VERSION ""

NS_ :

BS_:

BU_: WCM VPM VLM VKM UVM TIM TEST_TOOL_2 TEST_TOOL_1 TCP TCM TCCM3 TCCM STC SRR_SRR SRR_SLR SRR_RR SRR_RF SRR_LR_CR SRR_LF SIB SDM SCL SBZA_R SBZA_L SBM SADS RadioLow RSC RDCM PTM PDR PA NVM MTCM_R MTCM_L MSM_RR MSM_P MSM_LR MSM_D MSB2 MSB1 MRCM_R MRCM_L MFC LRR_HC LRR LIB1 IPC ICS_Info ICCM HVAC_FP_R HVAC_FP_F HUD_CAN HDLM FCM_LC FCM EPS EOCM_HCP2 EOCM_HCP1 EOCM ELM ECP_X1 ECP_MC ECP_E ECM EBCM DMS DEFC DCM CSM CMMb CMMa CGM BSM_MH BSM BCM ARS ARB APA AOS AMP ALC AHS AHL_AFL AGC

BO_ 1470 CGM_CAN5_PDU98: 8 CGM
 SG_ PTOStndbySpdCstCurrSetVal : 48|3@0+ (1,0) [0|7] "" CSM,RadioLow
 SG_ PTOEngRunTmrCstAvlFlg1 : 56|1@0+ (1,0) [0|1] "" CSM,RadioLow
 SG_ PTOEngSpdTypCstCurrSetVal : 58|2@0+ (1,0) [0|2] "" CSM,RadioLow
 SG_ PTOTpStpSpdCstCurrSetVal : 61|3@0+ (1,0) [0|7] "" CSM,RadioLow

BO_ 325 CGM_NM_PDU_On_CAN_5_Cluster: 8 CGM
 SG_ ISignal_CGM_CAN_5_Cluster : 23|48@0+ (1,0) [0|281474976710655] "" AGC,AMP,CSM,HUD_CAN,HVAC_FP_F,HVAC_FP_R,ICS_Info,IPC,PDR,MFC,RSC,RadioLow,TCP,VKM,WCM

BO_ 1263 CSM_CAN5_PDU03: 6 CSM
 SG_ TrlrPlcrdPres : 7|8@0+ (4,0) [0|1020] "kPaG" CGM
 SG_ TrlrProfDrvrReqdSeltn : 10|5@0+ (1,0) [0|21] "" CGM
 SG_ TrlrProfDeltn : 15|5@0+ (1,0) [0|20] "" CGM
 SG_ NumofAxls : 18|2@0+ (1,0) [0|3] "" CGM
 SG_ TrlrTireCnt : 21|3@0+ (1,0) [0|7] "count" CGM

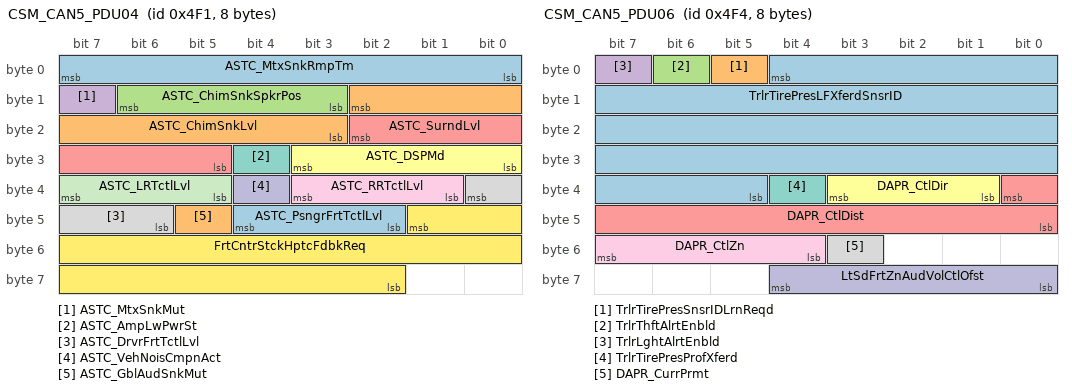
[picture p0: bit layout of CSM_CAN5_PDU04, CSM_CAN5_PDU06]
BO_ 1265 CSM_CAN5_PDU04: 8 CSM
 SG_ ASTC_MtxSnkRmpTm : 7|8@0+ (5,0) [0|1275] "ms" AMP
 SG_ ASTC_ChimSnkLvl : 10|8@0+ (0.5,-127.5) [-127.5|0] "dB" AMP
 SG_ ASTC_ChimSnkSpkrPos : 14|4@0+ (1,0) [0|15] "" AMP
 SG_ ASTC_MtxSnkMut : 15|1@0+ (1,0) [0|1] "" AMP
 SG_ ASTC_SurndLvl : 18|6@0- (1,0) [-32|31] "" AMP
 SG_ ASTC_DSPMd : 27|4@0+ (1,0) [0|15] "" AMP
 SG_ ASTC_AmpLwPwrSt : 28|1@0+ (1,0) [0|1] "" AMP
 SG_ ASTC_DrvrFrtTctlLvl : 32|3@0+ (1,0) [0|7] "Counts" AMP
 SG_ ASTC_RRTctlLvl : 35|3@0+ (1,0) [0|7] "Counts" AMP
 SG_ ASTC_VehNoisCmpnAct : 36|1@0+ (1,0) [0|1] "" AMP
 SG_ ASTC_LRTctlLvl : 39|3@0+ (1,0) [0|7] "Counts" AMP
 SG_ FrtCntrStckHptcFdbkReq : 41|16@0+ (1,0) [0|15] "" ICS_Info
 SG_ ASTC_PsngrFrtTctlLvl : 44|3@0+ (1,0) [0|7] "Counts" AMP
 SG_ ASTC_GblAudSnkMut : 45|1@0+ (1,0) [0|1] "" AMP

BO_ 1266 CSM_CAN5_PDU05: 8 CSM
 SG_ ZALC_LRMtxSnkRmpTm : 4|8@0+ (5,0) [0|1275] "msec" AMP
 SG_ ZALC_LRMtxSnkMut : 5|1@0+ (1,0) [0|1] "" AMP
 SG_ ZALC_PsngrFrtMtxSnkMut : 6|1@0+ (1,0) [0|1] "" AMP
 SG_ ZALC_MltZnMixPrmtAudRR : 7|1@0+ (1,0) [0|1] "" AMP
 SG_ ZALC_PsngrFrtMtxSnkLvl : 12|8@0+ (0.5,-127.5) [-127.5|0] "dB" AMP
 SG_ ZALC_RRMtxSnkLvl : 16|8@0+ (0.5,-127.5) [-127.5|0] "dB" AMP
 SG_ ZALC_RRMtxSnkMut : 17|1@0+ (1,0) [0|1] "" AMP
 SG_ ZALC_MltZnAudFtrStat : 20|3@0+ (1,0) [0|3] "" AMP
 SG_ ZALC_RRMtxSnkRmpTm : 24|8@0+ (5,0) [0|1275] "msec" AMP
 SG_ ZALC_PsngrFrtMtxSnkRmpTm : 32|8@0+ (5,0) [0|1275] "msec" AMP
 SG_ ZALC_VcSrcActvOnRRMtx : 40|1@0+ (1,0) [0|1] "" AMP
 SG_ ZALC_LRMtxSnkLvl : 53|8@0+ (0.5,-127.5) [-127.5|0] "dB" AMP
 SG_ ZALC_MltZnMixPrmtAudDrvrFrt : 54|1@0+ (1,0) [0|1] "" AMP
 SG_ ZALC_VcSrcActvOnPsngrFrtMtx : 55|1@0+ (1,0) [0|1] "" AMP
 SG_ FrtCntrStckOptDskDrvDckStat : 58|3@0+ (1,0) [0|7] "" ICS_Info,TCP
 SG_ ZALC_MltZnMixPrmtAudLR : 59|1@0+ (1,0) [0|1] "" AMP
 SG_ ZALC_MltZnMixPrmtAudPsngrFrt : 60|1@0+ (1,0) [0|1] "" AMP
 SG_ ZALC_VcSrcActvOnLRMtx : 61|1@0+ (1,0) [0|1] "" AMP

BO_ 1268 CSM_CAN5_PDU06: 8 CSM
 SG_ TrlrTirePresLFXferdSnsrID : 4|32@0+ (1,0) [0|4.29497e+009] "" CGM
 SG_ TrlrTirePresSnsrIDLrnReqd : 5|1@0+ (1,0) [0|1] "" CGM
 SG_ TrlrThftAlrtEnbld : 6|1@0+ (1,0) [0|1] "" CGM
 SG_ TrlrLghtAlrtEnbld : 7|1@0+ (1,0) [0|1] "" CGM
 SG_ DAPR_CtlDist : 32|9@0+ (1,0) [0|511] "" AMP
 SG_ DAPR_CtlDir : 35|3@0+ (1,0) [0|7] "" AMP
 SG_ TrlrTirePresProfXferd : 36|1@0+ (1,0) [0|1] "" CGM
 SG_ DAPR_CurrPrmt : 51|1@0+ (1,0) [0|1] "" AMP
 SG_ DAPR_CtlZn : 55|4@0+ (1,0) [0|15] "" AMP
 SG_ LtSdFrtZnAudVolCtlOfst : 60|5@0- (1,0) [-16|15] "" AMP

BO_ 1269 CSM_CAN5_PDU07: 8 CSM
 SG_ LVMAVC_RmtSpchRcgnID : 0|3@0+ (1,0) [0|3] "" PDR
 SG_ LVMAVC_PrmtAudResp : 2|2@0+ (1,0) [0|1] "" PDR
 SG_ LVMAVC_RmtSpchRcgnActn : 4|2@0+ (1,0) [0|3] "" PDR
 SG_ LVMAVC_ApplID : 7|3@0+ (1,0) [0|4] "" PDR
 SG_ LVMAVC_StreoAudResp : 8|2@0+ (1,0) [0|1] "" PDR
 SG_ LVMAVC_RmtEnbl : 11|3@0+ (1,0) [0|2] "" PDR
 SG_ LVMAVC_SpchRcgnAval : 13|2@0+ (1,0) [0|1] "" PDR
 SG_ TrlrLgth : 22|12@0+ (1,0) [0|4095] "cm" CGM
 SG_ TrlrHght : 26|10@0+ (1,0) [0|1023] "cm" CGM
 SG_ TrlrWdth : 32|9@0+ (1,0) [0|511] "cm" CGM
 SG_ TrlrStatTowHaulModeOvrrd : 49|2@0+ (1,0) [0|3] "" CGM
 SG_ TrlrLtngSeqReq : 51|2@0+ (1,0) [0|2] "" CGM
 SG_ TrlrHtchTyp : 53|2@0+ (1,0) [0|3] "" CGM
 SG_ FrtCntrStckVidInSel : 55|2@0+ (1,0) [0|2] "" ICS_Info,PDR,TCP
 SG_ TrlrAppInvsblTrlrPrvwReqd : 56|1@0+ (1,0) [0|1] "" CGM
 SG_ TrlrAppAux2CamPrvwReqd : 57|1@0+ (1,0) [0|1] "" CGM
 SG_ TrlrAppAux1CamPrvwReqd : 58|1@0+ (1,0) [0|1] "" CGM
 SG_ TrlRvsLghtFldEnbld : 59|1@0+ (1,0) [0|1] "" CGM
 SG_ FrtCntrStckTchCtlrRstCmd : 60|1@0+ (1,0) [0|1] "" ICS_Info,TCP
 SG_ Frt360CamSwAct : 61|1@0+ (1,0) [0|1] "" CGM
 SG_ TrlrTyp : 63|2@0+ (1,0) [0|2] "" CGM

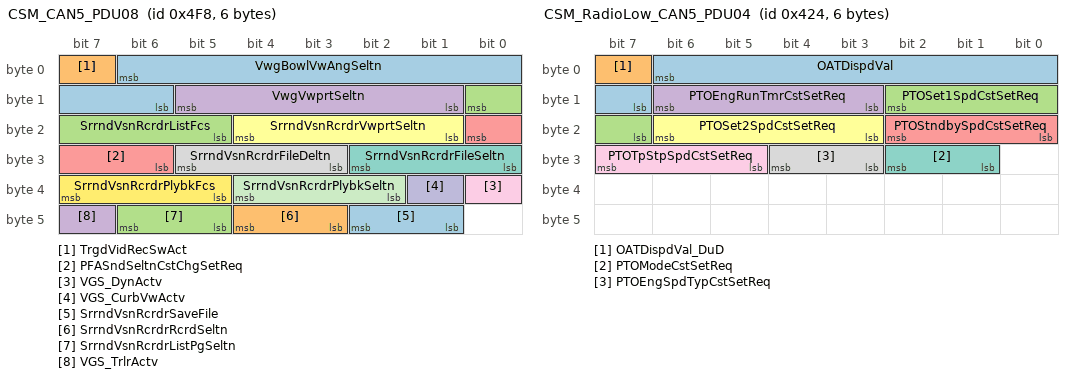
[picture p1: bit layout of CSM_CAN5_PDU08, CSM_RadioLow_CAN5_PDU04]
BO_ 1272 CSM_CAN5_PDU08: 6 CSM
 SG_ VwgBowlVwAngSeltn : 6|9@0+ (1,0) [0|511] "Degree" CGM
 SG_ TrgdVidRecSwAct : 7|1@0+ (1,0) [0|1] "" CGM
 SG_ SrrndVsnRcrdrListFcs : 8|4@0+ (1,0) [0|11] "" CGM
 SG_ VwgVwprtSeltn : 13|5@0+ (1,0) [0|24] "" CGM
 SG_ PFASndSeltnCstChgSetReq : 16|3@0+ (1,0) [0|7] "" CGM
 SG_ SrrndVsnRcrdrVwprtSeltn : 20|4@0+ (1,0) [0|8] "" CGM
 SG_ SrrndVsnRcrdrFileSeltn : 26|3@0+ (1,0) [0|6] "" CGM
 SG_ SrrndVsnRcrdrFileDeltn : 29|3@0+ (1,0) [0|6] "" CGM
 SG_ VGS_DynActv : 32|1@0+ (1,0) [0|1] "" CGM
 SG_ VGS_CurbVwActv : 33|1@0+ (1,0) [0|1] "" CGM
 SG_ SrrndVsnRcrdrPlybkSeltn : 36|3@0+ (1,0) [0|5] "" CGM
 SG_ SrrndVsnRcrdrPlybkFcs : 39|3@0+ (1,0) [0|6] "" CGM
 SG_ SrrndVsnRcrdrSaveFile : 42|2@0+ (1,0) [0|2] "" CGM
 SG_ SrrndVsnRcrdrRcrdSeltn : 44|2@0+ (1,0) [0|2] "" CGM
 SG_ SrrndVsnRcrdrListPgSeltn : 46|2@0+ (1,0) [0|3] "" CGM
 SG_ VGS_TrlrActv : 47|1@0+ (1,0) [0|1] "" CGM

BO_ 1254 CSM_CAN5_PDU09: 8 CSM
 SG_ TrlrTirePresLRXferdSnsrID : 7|32@0+ (1,0) [0|4.29497e+009] "" CGM
 SG_ TrlrTirePresLtMdlXferdSnsrID : 39|32@0+ (1,0) [0|4.29497e+009] "" CGM

BO_ 1257 CSM_CAN5_PDU10: 8 CSM
 SG_ TrlrTirePresRFXferdSnsrID : 7|32@0+ (1,0) [0|4.29497e+009] "" CGM
 SG_ TrlrTirePresRRXferdSnsrID : 39|32@0+ (1,0) [0|4.29497e+009] "" CGM

BO_ 1258 CSM_CAN5_PDU11: 6 CSM
 SG_ TrlrTirePresRtMdlXferdSnsrID : 7|32@0+ (1,0) [0|4.29497e+009] "" CGM
 SG_ HMIInCarVcCommCtl : 34|3@0+ (1,0) [0|6] "" AMP
 SG_ RtSdFrtZnAudVolCtlOfst : 39|5@0- (1,0) [-16|15] "" AMP
 SG_ AutoLnChgCstChgSetReq : 42|3@0+ (1,0) [0|4] "" CGM
 SG_ DrvrSeltdTrlrPrsnt : 43|1@0+ (1,0) [0|1] "" CGM
 SG_ VcRcgnSesnActv : 44|1@0+ (1,0) [0|1] "" AMP
 SG_ HndsFrVcCallActv : 45|1@0+ (1,0) [0|1] "" AMP
 SG_ FrtZnAudVolSyncCtlOn : 46|1@0+ (1,0) [0|1] "" AMP
 SG_ DirAudPrmtRndrngEnbld : 47|1@0+ (1,0) [0|1] "" AMP

BO_ 1415 CSM_CAN5_PDU12: 8 CSM
 SG_ HtchPtLgthExtd : 7|10@0+ (1,1) [1|1024] "cm" CGM
 SG_ TrlrTngeLgth : 13|9@0+ (1,0) [0|511] "cm" CGM
 SG_ VehHtchHght : 20|9@0+ (0.25,0) [0|127.75] "cm" CGM
 SG_ VehHtchLgth : 27|9@0+ (0.25,0) [0|127.75] "cm" CGM
 SG_ TrlrFllHtchPtLgth : 34|11@0+ (1,0) [0|2047] "cm" CGM
 SG_ TrlrToCabLgth : 55|10@0+ (1,0) [0|1023] "cm" CGM

BO_ 1063 CSM_CAN5_PDU13: 6 CSM
 SG_ PASftBtnSeltdStatRw : 5|2@0+ (1,0) [0|3] "" CGM
 SG_ APASftBtnSeltdStatRw : 7|2@0+ (1,0) [0|3] "" CGM

BO_ 1435 CSM_CAN5_PDU14: 6 CSM
 SG_ VehBedHtchToCabLgth : 7|9@0+ (1,0) [0|511] "cm" CGM

BO_ 384 CSM_NM_PDU_On_CAN_5_Cluster: 8 CSM
 SG_ ISignal_CSM_CAN_5_Cluster : 23|48@0+ (1,0) [0|281474976710655] "" AGC,AMP,CGM,HUD_CAN,HVAC_FP_F,HVAC_FP_R,ICS_Info,IPC,PDR,MFC,RSC,RadioLow,TCP,VKM,WCM

BO_ 552 CSM_RadioLow_CAN5_PDU02: 6 CSM
 SG_ WCM_LCMDataMsgStat : 0|1@0+ (1,0) [0|1] "" WCM
 SG_ WCM_LCMFileTrans : 4|3@0+ (1,0) [0|4] "" WCM

BO_ 1356 CSM_RadioLow_CAN5_PDU03: 6 CSM
 SG_ PwrRrClsrCstChgSetReq : 7|3@0+ (1,0) [0|7] "" CGM

BO_ 1060 CSM_RadioLow_CAN5_PDU04: 6 CSM
 SG_ OATDispdVal : 6|8@0+ (1,-40) [-40|215] "" IPC
 SG_ OATDispdVal_DuD : 7|1@0+ (1,0) [0|1] "" IPC
 SG_ PTOSet1SpdCstSetReq : 10|4@0+ (1,0) [0|15] "" CGM
 SG_ PTOEngRunTmrCstSetReq : 14|4@0+ (1,0) [0|15] "" CGM
 SG_ PTOStndbySpdCstSetReq : 18|3@0+ (1,0) [0|7] "" CGM
 SG_ PTOSet2SpdCstSetReq : 22|4@0+ (1,0) [0|15] "" CGM
 SG_ PTOModeCstSetReq : 26|2@0+ (1,0) [0|2] "" CGM
 SG_ PTOEngSpdTypCstSetReq : 28|2@0+ (1,0) [0|2] "" CGM
 SG_ PTOTpStpSpdCstSetReq : 31|3@0+ (1,0) [0|7] "" CGM

BO_ 1419 CSM_VCU_CAN5_PDU01: 6 CSM
 SG_ TrlrBoxWdth : 2|9@0+ (1,0) [0|511] "cm" CGM
 SG_ AutoTrnspHdActvnCstChgSetReq : 5|3@0+ (1,0) [0|2] "" CGM
 SG_ TrlrFaceDpth : 9|9@0+ (1,0) [0|511] "cm" CGM
 SG_ TrlrFrwdSdEdgeHght : 16|9@0+ (1,0) [0|511] "cm" CGM
 SG_ TrlrFrtBtmCrnrHght : 39|9@0+ (1,0) [0|511] "cm" CGM

BO_ 1374 ChmReqInfo_PDU: 8 IPC
 SG_ CRI_ChmPrdcrReq : 7|12@0+ (1,0) [0|4095] "msec" AMP,CSM,RadioLow
 SG_ CRI_CS : 50|11@0+ (1,0) [0|2047] "" AMP,CSM,RadioLow
 SG_ CRI_ARC : 55|2@0+ (1,0) [0|3] "" AMP,CSM,RadioLow

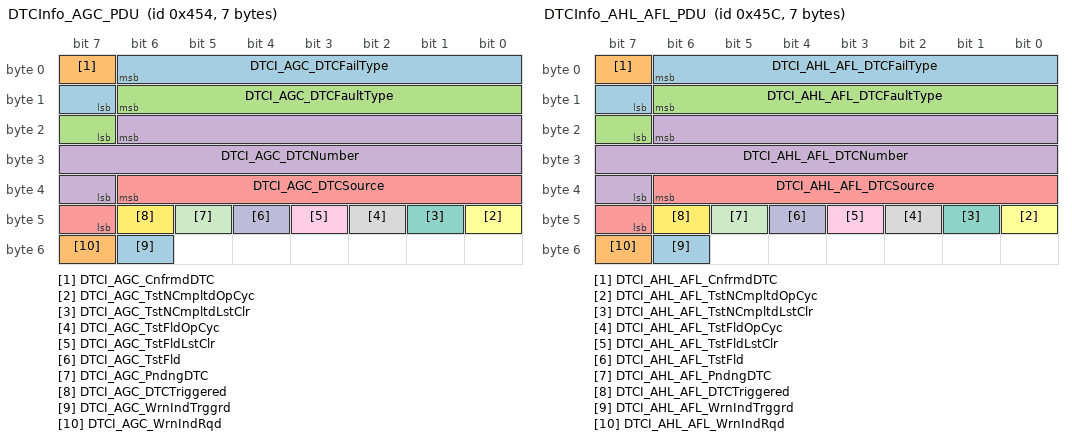
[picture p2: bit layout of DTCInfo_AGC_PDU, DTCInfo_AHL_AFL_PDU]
BO_ 1108 DTCInfo_AGC_PDU: 7 AGC
 SG_ DTCI_AGC_DTCFailType : 6|8@0+ (1,0) [0|255] "" CSM,TCP
 SG_ DTCI_AGC_CnfrmdDTC : 7|1@0+ (1,0) [0|1] "" CSM,TCP
 SG_ DTCI_AGC_DTCFaultType : 14|8@0+ (1,0) [0|3] "" CSM,TCP
 SG_ DTCI_AGC_DTCNumber : 22|16@0+ (1,0) [0|65535] "" CSM,TCP
 SG_ DTCI_AGC_DTCSource : 38|8@0+ (1,0) [0|255] "" CGM,CSM,TCP
 SG_ DTCI_AGC_TstNCmpltdOpCyc : 40|1@0+ (1,0) [0|1] "" CSM,TCP
 SG_ DTCI_AGC_TstNCmpltdLstClr : 41|1@0+ (1,0) [0|1] "" CSM,TCP
 SG_ DTCI_AGC_TstFldOpCyc : 42|1@0+ (1,0) [0|1] "" CSM,TCP
 SG_ DTCI_AGC_TstFldLstClr : 43|1@0+ (1,0) [0|1] "" CSM,TCP
 SG_ DTCI_AGC_TstFld : 44|1@0+ (1,0) [0|1] "" CSM,TCP
 SG_ DTCI_AGC_PndngDTC : 45|1@0+ (1,0) [0|1] "" CSM,TCP
 SG_ DTCI_AGC_DTCTriggered : 46|1@0+ (1,0) [0|1] "" CSM,TCP
 SG_ DTCI_AGC_WrnIndTrggrd : 54|1@0+ (1,0) [0|1] "" CSM,TCP
 SG_ DTCI_AGC_WrnIndRqd : 55|1@0+ (1,0) [0|1] "" CSM,TCP

BO_ 1116 DTCInfo_AHL_AFL_PDU: 7 CGM
 SG_ DTCI_AHL_AFL_DTCFailType : 6|8@0+ (1,0) [0|255] "" CSM,TCP
 SG_ DTCI_AHL_AFL_CnfrmdDTC : 7|1@0+ (1,0) [0|1] "" CSM,TCP
 SG_ DTCI_AHL_AFL_DTCFaultType : 14|8@0+ (1,0) [0|3] "" CSM,TCP
 SG_ DTCI_AHL_AFL_DTCNumber : 22|16@0+ (1,0) [0|65535] "" CSM,TCP
 SG_ DTCI_AHL_AFL_DTCSource : 38|8@0+ (1,0) [0|255] "" CSM,TCP
 SG_ DTCI_AHL_AFL_TstNCmpltdOpCyc : 40|1@0+ (1,0) [0|1] "" CSM,TCP
 SG_ DTCI_AHL_AFL_TstNCmpltdLstClr : 41|1@0+ (1,0) [0|1] "" CSM,TCP
 SG_ DTCI_AHL_AFL_TstFldOpCyc : 42|1@0+ (1,0) [0|1] "" CSM,TCP
 SG_ DTCI_AHL_AFL_TstFldLstClr : 43|1@0+ (1,0) [0|1] "" CSM,TCP
 SG_ DTCI_AHL_AFL_TstFld : 44|1@0+ (1,0) [0|1] "" CSM,TCP
 SG_ DTCI_AHL_AFL_PndngDTC : 45|1@0+ (1,0) [0|1] "" CSM,TCP
 SG_ DTCI_AHL_AFL_DTCTriggered : 46|1@0+ (1,0) [0|1] "" CSM,TCP
 SG_ DTCI_AHL_AFL_WrnIndTrggrd : 54|1@0+ (1,0) [0|1] "" CSM,TCP
 SG_ DTCI_AHL_AFL_WrnIndRqd : 55|1@0+ (1,0) [0|1] "" CSM,TCP

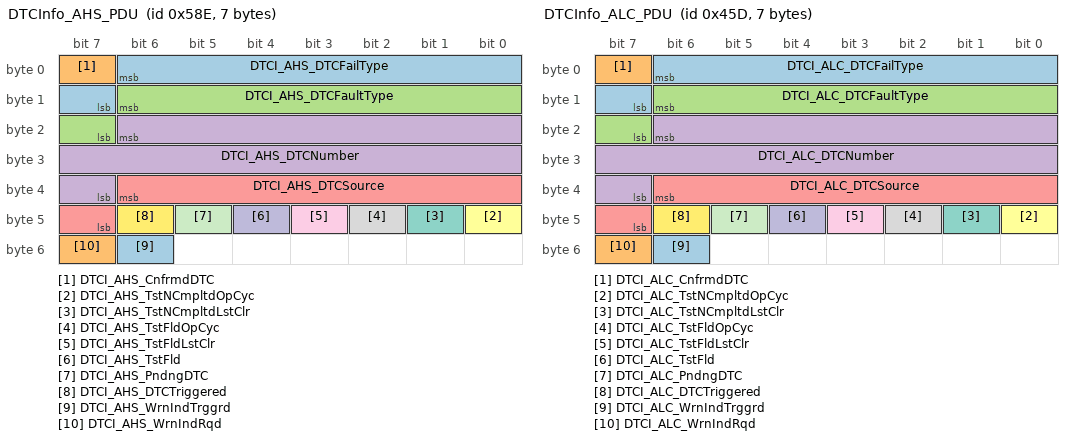
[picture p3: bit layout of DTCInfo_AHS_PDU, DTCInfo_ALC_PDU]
BO_ 1422 DTCInfo_AHS_PDU: 7 CGM
 SG_ DTCI_AHS_DTCFailType : 6|8@0+ (1,0) [0|255] "" TCP
 SG_ DTCI_AHS_CnfrmdDTC : 7|1@0+ (1,0) [0|1] "" TCP
 SG_ DTCI_AHS_DTCFaultType : 14|8@0+ (1,0) [0|3] "" TCP
 SG_ DTCI_AHS_DTCNumber : 22|16@0+ (1,0) [0|65535] "" TCP
 SG_ DTCI_AHS_DTCSource : 38|8@0+ (1,0) [0|255] "" TCP
 SG_ DTCI_AHS_TstNCmpltdOpCyc : 40|1@0+ (1,0) [0|1] "" TCP
 SG_ DTCI_AHS_TstNCmpltdLstClr : 41|1@0+ (1,0) [0|1] "" TCP
 SG_ DTCI_AHS_TstFldOpCyc : 42|1@0+ (1,0) [0|1] "" TCP
 SG_ DTCI_AHS_TstFldLstClr : 43|1@0+ (1,0) [0|1] "" TCP
 SG_ DTCI_AHS_TstFld : 44|1@0+ (1,0) [0|1] "" TCP
 SG_ DTCI_AHS_PndngDTC : 45|1@0+ (1,0) [0|1] "" TCP
 SG_ DTCI_AHS_DTCTriggered : 46|1@0+ (1,0) [0|1] "" TCP
 SG_ DTCI_AHS_WrnIndTrggrd : 54|1@0+ (1,0) [0|1] "" TCP
 SG_ DTCI_AHS_WrnIndRqd : 55|1@0+ (1,0) [0|1] "" TCP

BO_ 1117 DTCInfo_ALC_PDU: 7 CGM
 SG_ DTCI_ALC_DTCFailType : 6|8@0+ (1,0) [0|255] "" CSM,TCP
 SG_ DTCI_ALC_CnfrmdDTC : 7|1@0+ (1,0) [0|1] "" CSM,TCP
 SG_ DTCI_ALC_DTCFaultType : 14|8@0+ (1,0) [0|3] "" CSM,TCP
 SG_ DTCI_ALC_DTCNumber : 22|16@0+ (1,0) [0|65535] "" CSM,TCP
 SG_ DTCI_ALC_DTCSource : 38|8@0+ (1,0) [0|255] "" CSM,TCP
 SG_ DTCI_ALC_TstNCmpltdOpCyc : 40|1@0+ (1,0) [0|1] "" CSM,TCP
 SG_ DTCI_ALC_TstNCmpltdLstClr : 41|1@0+ (1,0) [0|1] "" CSM,TCP
 SG_ DTCI_ALC_TstFldOpCyc : 42|1@0+ (1,0) [0|1] "" CSM,TCP
 SG_ DTCI_ALC_TstFldLstClr : 43|1@0+ (1,0) [0|1] "" CSM,TCP
 SG_ DTCI_ALC_TstFld : 44|1@0+ (1,0) [0|1] "" CSM,TCP
 SG_ DTCI_ALC_PndngDTC : 45|1@0+ (1,0) [0|1] "" CSM,TCP
 SG_ DTCI_ALC_DTCTriggered : 46|1@0+ (1,0) [0|1] "" CSM,TCP
 SG_ DTCI_ALC_WrnIndTrggrd : 54|1@0+ (1,0) [0|1] "" CSM,TCP
 SG_ DTCI_ALC_WrnIndRqd : 55|1@0+ (1,0) [0|1] "" CSM,TCP

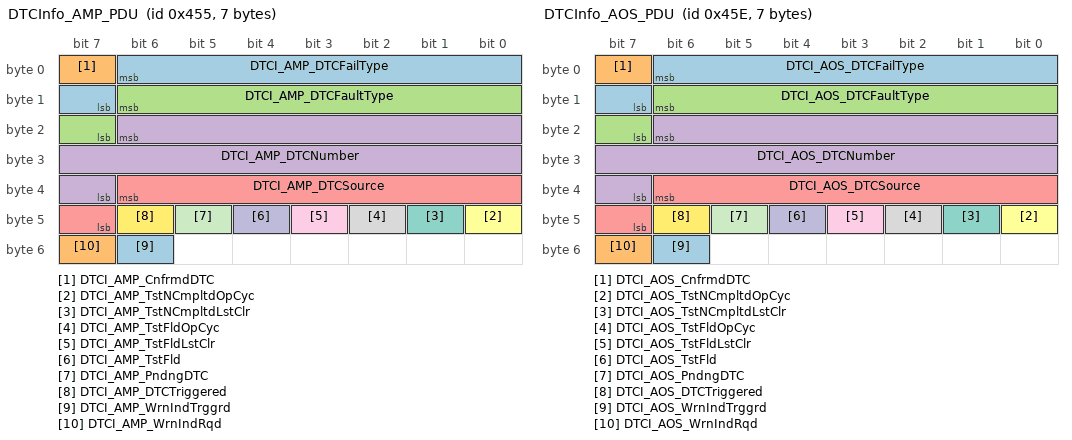
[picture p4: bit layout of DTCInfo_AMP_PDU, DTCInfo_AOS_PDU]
BO_ 1109 DTCInfo_AMP_PDU: 7 AMP
 SG_ DTCI_AMP_DTCFailType : 6|8@0+ (1,0) [0|255] "" CSM,TCP
 SG_ DTCI_AMP_CnfrmdDTC : 7|1@0+ (1,0) [0|1] "" CSM,TCP
 SG_ DTCI_AMP_DTCFaultType : 14|8@0+ (1,0) [0|3] "" CSM,TCP
 SG_ DTCI_AMP_DTCNumber : 22|16@0+ (1,0) [0|65535] "" CSM,TCP
 SG_ DTCI_AMP_DTCSource : 38|8@0+ (1,0) [0|255] "" CGM,CSM,TCP
 SG_ DTCI_AMP_TstNCmpltdOpCyc : 40|1@0+ (1,0) [0|1] "" CSM,TCP
 SG_ DTCI_AMP_TstNCmpltdLstClr : 41|1@0+ (1,0) [0|1] "" CSM,TCP
 SG_ DTCI_AMP_TstFldOpCyc : 42|1@0+ (1,0) [0|1] "" CSM,TCP
 SG_ DTCI_AMP_TstFldLstClr : 43|1@0+ (1,0) [0|1] "" CSM,TCP
 SG_ DTCI_AMP_TstFld : 44|1@0+ (1,0) [0|1] "" CSM,TCP
 SG_ DTCI_AMP_PndngDTC : 45|1@0+ (1,0) [0|1] "" CSM,TCP
 SG_ DTCI_AMP_DTCTriggered : 46|1@0+ (1,0) [0|1] "" CSM,TCP
 SG_ DTCI_AMP_WrnIndTrggrd : 54|1@0+ (1,0) [0|1] "" CSM,TCP
 SG_ DTCI_AMP_WrnIndRqd : 55|1@0+ (1,0) [0|1] "" CSM,TCP

BO_ 1118 DTCInfo_AOS_PDU: 7 CGM
 SG_ DTCI_AOS_DTCFailType : 6|8@0+ (1,0) [0|255] "" CSM,TCP
 SG_ DTCI_AOS_CnfrmdDTC : 7|1@0+ (1,0) [0|1] "" CSM,TCP
 SG_ DTCI_AOS_DTCFaultType : 14|8@0+ (1,0) [0|3] "" CSM,TCP
 SG_ DTCI_AOS_DTCNumber : 22|16@0+ (1,0) [0|65535] "" CSM,TCP
 SG_ DTCI_AOS_DTCSource : 38|8@0+ (1,0) [0|255] "" CSM,TCP
 SG_ DTCI_AOS_TstNCmpltdOpCyc : 40|1@0+ (1,0) [0|1] "" CSM,TCP
 SG_ DTCI_AOS_TstNCmpltdLstClr : 41|1@0+ (1,0) [0|1] "" CSM,TCP
 SG_ DTCI_AOS_TstFldOpCyc : 42|1@0+ (1,0) [0|1] "" CSM,TCP
 SG_ DTCI_AOS_TstFldLstClr : 43|1@0+ (1,0) [0|1] "" CSM,TCP
 SG_ DTCI_AOS_TstFld : 44|1@0+ (1,0) [0|1] "" CSM,TCP
 SG_ DTCI_AOS_PndngDTC : 45|1@0+ (1,0) [0|1] "" CSM,TCP
 SG_ DTCI_AOS_DTCTriggered : 46|1@0+ (1,0) [0|1] "" CSM,TCP
 SG_ DTCI_AOS_WrnIndTrggrd : 54|1@0+ (1,0) [0|1] "" CSM,TCP
 SG_ DTCI_AOS_WrnIndRqd : 55|1@0+ (1,0) [0|1] "" CSM,TCP

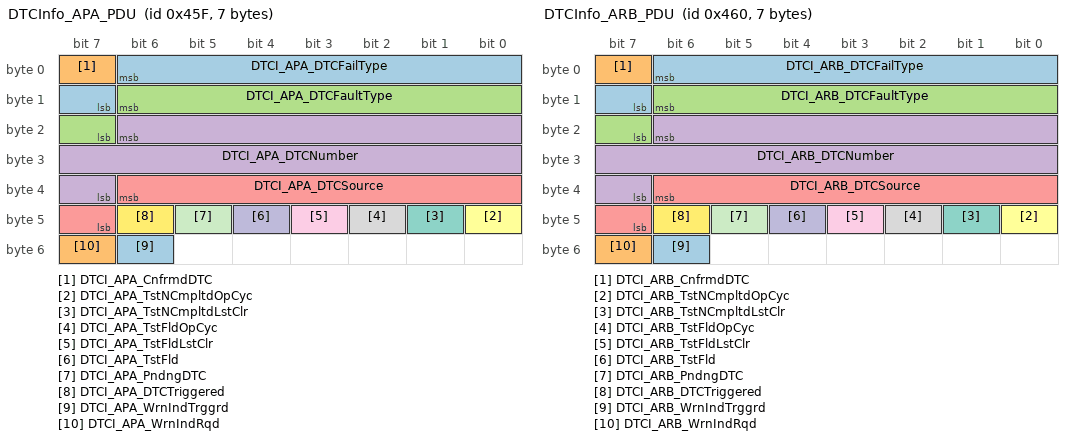
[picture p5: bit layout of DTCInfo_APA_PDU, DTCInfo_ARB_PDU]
BO_ 1119 DTCInfo_APA_PDU: 7 CGM
 SG_ DTCI_APA_DTCFailType : 6|8@0+ (1,0) [0|255] "" CSM,TCP
 SG_ DTCI_APA_CnfrmdDTC : 7|1@0+ (1,0) [0|1] "" CSM,TCP
 SG_ DTCI_APA_DTCFaultType : 14|8@0+ (1,0) [0|3] "" CSM,TCP
 SG_ DTCI_APA_DTCNumber : 22|16@0+ (1,0) [0|65535] "" CSM,TCP
 SG_ DTCI_APA_DTCSource : 38|8@0+ (1,0) [0|255] "" CSM,TCP
 SG_ DTCI_APA_TstNCmpltdOpCyc : 40|1@0+ (1,0) [0|1] "" CSM,TCP
 SG_ DTCI_APA_TstNCmpltdLstClr : 41|1@0+ (1,0) [0|1] "" CSM,TCP
 SG_ DTCI_APA_TstFldOpCyc : 42|1@0+ (1,0) [0|1] "" CSM,TCP
 SG_ DTCI_APA_TstFldLstClr : 43|1@0+ (1,0) [0|1] "" CSM,TCP
 SG_ DTCI_APA_TstFld : 44|1@0+ (1,0) [0|1] "" CSM,TCP
 SG_ DTCI_APA_PndngDTC : 45|1@0+ (1,0) [0|1] "" CSM,TCP
 SG_ DTCI_APA_DTCTriggered : 46|1@0+ (1,0) [0|1] "" CSM,TCP
 SG_ DTCI_APA_WrnIndTrggrd : 54|1@0+ (1,0) [0|1] "" CSM,TCP
 SG_ DTCI_APA_WrnIndRqd : 55|1@0+ (1,0) [0|1] "" CSM,TCP

BO_ 1120 DTCInfo_ARB_PDU: 7 CGM
 SG_ DTCI_ARB_DTCFailType : 6|8@0+ (1,0) [0|255] "" CSM,TCP
 SG_ DTCI_ARB_CnfrmdDTC : 7|1@0+ (1,0) [0|1] "" CSM,TCP
 SG_ DTCI_ARB_DTCFaultType : 14|8@0+ (1,0) [0|3] "" CSM,TCP
 SG_ DTCI_ARB_DTCNumber : 22|16@0+ (1,0) [0|65535] "" CSM,TCP
 SG_ DTCI_ARB_DTCSource : 38|8@0+ (1,0) [0|255] "" CSM,TCP
 SG_ DTCI_ARB_TstNCmpltdOpCyc : 40|1@0+ (1,0) [0|1] "" CSM,TCP
 SG_ DTCI_ARB_TstNCmpltdLstClr : 41|1@0+ (1,0) [0|1] "" CSM,TCP
 SG_ DTCI_ARB_TstFldOpCyc : 42|1@0+ (1,0) [0|1] "" CSM,TCP
 SG_ DTCI_ARB_TstFldLstClr : 43|1@0+ (1,0) [0|1] "" CSM,TCP
 SG_ DTCI_ARB_TstFld : 44|1@0+ (1,0) [0|1] "" CSM,TCP
 SG_ DTCI_ARB_PndngDTC : 45|1@0+ (1,0) [0|1] "" CSM,TCP
 SG_ DTCI_ARB_DTCTriggered : 46|1@0+ (1,0) [0|1] "" CSM,TCP
 SG_ DTCI_ARB_WrnIndTrggrd : 54|1@0+ (1,0) [0|1] "" CSM,TCP
 SG_ DTCI_ARB_WrnIndRqd : 55|1@0+ (1,0) [0|1] "" CSM,TCP

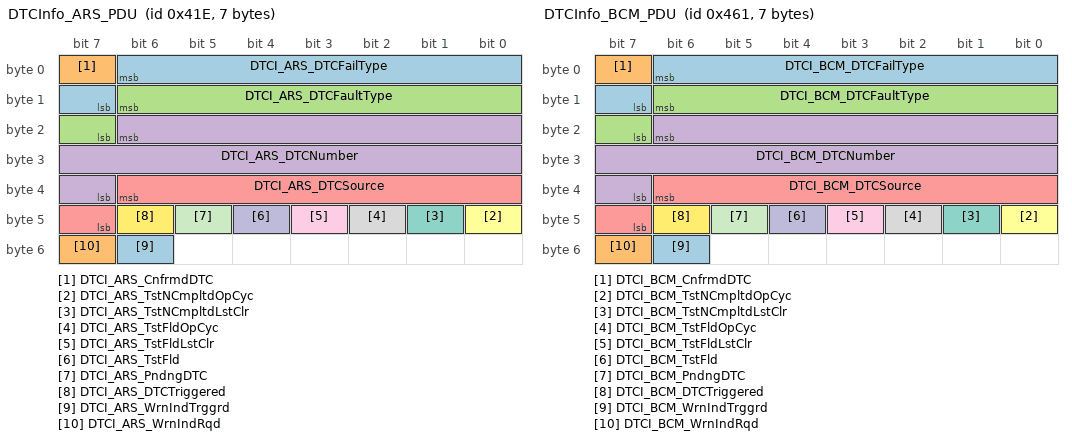
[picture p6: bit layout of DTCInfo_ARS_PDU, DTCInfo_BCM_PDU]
BO_ 1054 DTCInfo_ARS_PDU: 7 CGM
 SG_ DTCI_ARS_DTCFailType : 6|8@0+ (1,0) [0|255] "" CSM,TCP
 SG_ DTCI_ARS_CnfrmdDTC : 7|1@0+ (1,0) [0|1] "" CSM,TCP
 SG_ DTCI_ARS_DTCFaultType : 14|8@0+ (1,0) [0|3] "" CSM,TCP
 SG_ DTCI_ARS_DTCNumber : 22|16@0+ (1,0) [0|65535] "" CSM,TCP
 SG_ DTCI_ARS_DTCSource : 38|8@0+ (1,0) [0|255] "" CSM,TCP
 SG_ DTCI_ARS_TstNCmpltdOpCyc : 40|1@0+ (1,0) [0|1] "" CSM,TCP
 SG_ DTCI_ARS_TstNCmpltdLstClr : 41|1@0+ (1,0) [0|1] "" CSM,TCP
 SG_ DTCI_ARS_TstFldOpCyc : 42|1@0+ (1,0) [0|1] "" CSM,TCP
 SG_ DTCI_ARS_TstFldLstClr : 43|1@0+ (1,0) [0|1] "" CSM,TCP
 SG_ DTCI_ARS_TstFld : 44|1@0+ (1,0) [0|1] "" CSM,TCP
 SG_ DTCI_ARS_PndngDTC : 45|1@0+ (1,0) [0|1] "" CSM,TCP
 SG_ DTCI_ARS_DTCTriggered : 46|1@0+ (1,0) [0|1] "" CSM,TCP
 SG_ DTCI_ARS_WrnIndTrggrd : 54|1@0+ (1,0) [0|1] "" CSM,TCP
 SG_ DTCI_ARS_WrnIndRqd : 55|1@0+ (1,0) [0|1] "" CSM,TCP

BO_ 1121 DTCInfo_BCM_PDU: 7 CGM
 SG_ DTCI_BCM_DTCFailType : 6|8@0+ (1,0) [0|255] "" CSM,TCP
 SG_ DTCI_BCM_CnfrmdDTC : 7|1@0+ (1,0) [0|1] "" CSM,TCP
 SG_ DTCI_BCM_DTCFaultType : 14|8@0+ (1,0) [0|3] "" CSM,TCP
 SG_ DTCI_BCM_DTCNumber : 22|16@0+ (1,0) [0|65535] "" CSM,TCP
 SG_ DTCI_BCM_DTCSource : 38|8@0+ (1,0) [0|255] "" CSM,TCP
 SG_ DTCI_BCM_TstNCmpltdOpCyc : 40|1@0+ (1,0) [0|1] "" CSM,TCP
 SG_ DTCI_BCM_TstNCmpltdLstClr : 41|1@0+ (1,0) [0|1] "" CSM,TCP
 SG_ DTCI_BCM_TstFldOpCyc : 42|1@0+ (1,0) [0|1] "" CSM,TCP
 SG_ DTCI_BCM_TstFldLstClr : 43|1@0+ (1,0) [0|1] "" CSM,TCP
 SG_ DTCI_BCM_TstFld : 44|1@0+ (1,0) [0|1] "" CSM,TCP
 SG_ DTCI_BCM_PndngDTC : 45|1@0+ (1,0) [0|1] "" CSM,TCP
 SG_ DTCI_BCM_DTCTriggered : 46|1@0+ (1,0) [0|1] "" CSM,TCP
 SG_ DTCI_BCM_WrnIndTrggrd : 54|1@0+ (1,0) [0|1] "" CSM,TCP
 SG_ DTCI_BCM_WrnIndRqd : 55|1@0+ (1,0) [0|1] "" CSM,TCP

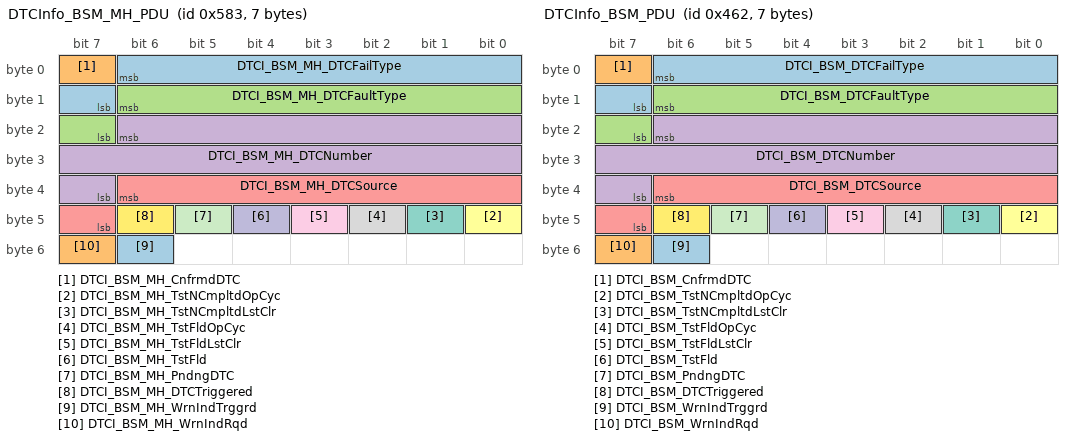
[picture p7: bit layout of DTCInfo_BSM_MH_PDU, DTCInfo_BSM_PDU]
BO_ 1411 DTCInfo_BSM_MH_PDU: 7 CGM
 SG_ DTCI_BSM_MH_DTCFailType : 6|8@0+ (1,0) [0|255] "" CSM,TCP
 SG_ DTCI_BSM_MH_CnfrmdDTC : 7|1@0+ (1,0) [0|1] "" CSM,TCP
 SG_ DTCI_BSM_MH_DTCFaultType : 14|8@0+ (1,0) [0|3] "" CSM,TCP
 SG_ DTCI_BSM_MH_DTCNumber : 22|16@0+ (1,0) [0|65535] "" CSM,TCP
 SG_ DTCI_BSM_MH_DTCSource : 38|8@0+ (1,0) [0|255] "" CSM,TCP
 SG_ DTCI_BSM_MH_TstNCmpltdOpCyc : 40|1@0+ (1,0) [0|1] "" CSM,TCP
 SG_ DTCI_BSM_MH_TstNCmpltdLstClr : 41|1@0+ (1,0) [0|1] "" CSM,TCP
 SG_ DTCI_BSM_MH_TstFldOpCyc : 42|1@0+ (1,0) [0|1] "" CSM,TCP
 SG_ DTCI_BSM_MH_TstFldLstClr : 43|1@0+ (1,0) [0|1] "" CSM,TCP
 SG_ DTCI_BSM_MH_TstFld : 44|1@0+ (1,0) [0|1] "" CSM,TCP
 SG_ DTCI_BSM_MH_PndngDTC : 45|1@0+ (1,0) [0|1] "" CSM,TCP
 SG_ DTCI_BSM_MH_DTCTriggered : 46|1@0+ (1,0) [0|1] "" CSM,TCP
 SG_ DTCI_BSM_MH_WrnIndTrggrd : 54|1@0+ (1,0) [0|1] "" CSM,TCP
 SG_ DTCI_BSM_MH_WrnIndRqd : 55|1@0+ (1,0) [0|1] "" CSM,TCP

BO_ 1122 DTCInfo_BSM_PDU: 7 CGM
 SG_ DTCI_BSM_DTCFailType : 6|8@0+ (1,0) [0|255] "" CSM,TCP
 SG_ DTCI_BSM_CnfrmdDTC : 7|1@0+ (1,0) [0|1] "" CSM,TCP
 SG_ DTCI_BSM_DTCFaultType : 14|8@0+ (1,0) [0|3] "" CSM,TCP
 SG_ DTCI_BSM_DTCNumber : 22|16@0+ (1,0) [0|65535] "" CSM,TCP
 SG_ DTCI_BSM_DTCSource : 38|8@0+ (1,0) [0|255] "" CSM,TCP
 SG_ DTCI_BSM_TstNCmpltdOpCyc : 40|1@0+ (1,0) [0|1] "" CSM,TCP
 SG_ DTCI_BSM_TstNCmpltdLstClr : 41|1@0+ (1,0) [0|1] "" CSM,TCP
 SG_ DTCI_BSM_TstFldOpCyc : 42|1@0+ (1,0) [0|1] "" CSM,TCP
 SG_ DTCI_BSM_TstFldLstClr : 43|1@0+ (1,0) [0|1] "" CSM,TCP
 SG_ DTCI_BSM_TstFld : 44|1@0+ (1,0) [0|1] "" CSM,TCP
 SG_ DTCI_BSM_PndngDTC : 45|1@0+ (1,0) [0|1] "" CSM,TCP
 SG_ DTCI_BSM_DTCTriggered : 46|1@0+ (1,0) [0|1] "" CSM,TCP
 SG_ DTCI_BSM_WrnIndTrggrd : 54|1@0+ (1,0) [0|1] "" CSM,TCP
 SG_ DTCI_BSM_WrnIndRqd : 55|1@0+ (1,0) [0|1] "" CSM,TCP

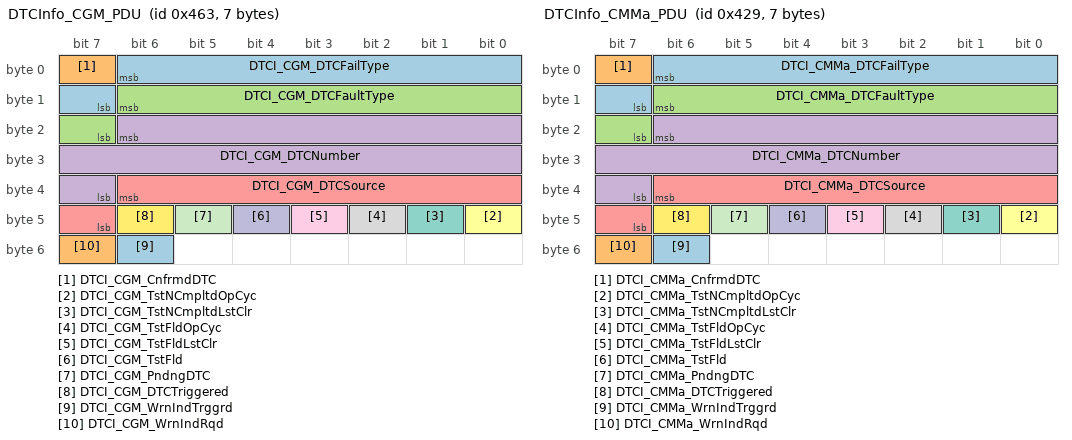
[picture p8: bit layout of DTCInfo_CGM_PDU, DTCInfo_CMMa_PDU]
BO_ 1123 DTCInfo_CGM_PDU: 7 CGM
 SG_ DTCI_CGM_DTCFailType : 6|8@0+ (1,0) [0|255] "" CSM,TCP
 SG_ DTCI_CGM_CnfrmdDTC : 7|1@0+ (1,0) [0|1] "" CSM,TCP
 SG_ DTCI_CGM_DTCFaultType : 14|8@0+ (1,0) [0|3] "" CSM,TCP
 SG_ DTCI_CGM_DTCNumber : 22|16@0+ (1,0) [0|65535] "" CSM,TCP
 SG_ DTCI_CGM_DTCSource : 38|8@0+ (1,0) [0|255] "" CSM,TCP
 SG_ DTCI_CGM_TstNCmpltdOpCyc : 40|1@0+ (1,0) [0|1] "" CSM,TCP
 SG_ DTCI_CGM_TstNCmpltdLstClr : 41|1@0+ (1,0) [0|1] "" CSM,TCP
 SG_ DTCI_CGM_TstFldOpCyc : 42|1@0+ (1,0) [0|1] "" CSM,TCP
 SG_ DTCI_CGM_TstFldLstClr : 43|1@0+ (1,0) [0|1] "" CSM,TCP
 SG_ DTCI_CGM_TstFld : 44|1@0+ (1,0) [0|1] "" CSM,TCP
 SG_ DTCI_CGM_PndngDTC : 45|1@0+ (1,0) [0|1] "" CSM,TCP
 SG_ DTCI_CGM_DTCTriggered : 46|1@0+ (1,0) [0|1] "" CSM,TCP
 SG_ DTCI_CGM_WrnIndTrggrd : 54|1@0+ (1,0) [0|1] "" CSM,TCP
 SG_ DTCI_CGM_WrnIndRqd : 55|1@0+ (1,0) [0|1] "" CSM,TCP

BO_ 1065 DTCInfo_CMMa_PDU: 7 CGM
 SG_ DTCI_CMMa_DTCFailType : 6|8@0+ (1,0) [0|255] "" CSM,TCP
 SG_ DTCI_CMMa_CnfrmdDTC : 7|1@0+ (1,0) [0|1] "" CSM,TCP
 SG_ DTCI_CMMa_DTCFaultType : 14|8@0+ (1,0) [0|3] "" CSM,TCP
 SG_ DTCI_CMMa_DTCNumber : 22|16@0+ (1,0) [0|65535] "" CSM,TCP
 SG_ DTCI_CMMa_DTCSource : 38|8@0+ (1,0) [0|255] "" CSM,TCP
 SG_ DTCI_CMMa_TstNCmpltdOpCyc : 40|1@0+ (1,0) [0|1] "" CSM,TCP
 SG_ DTCI_CMMa_TstNCmpltdLstClr : 41|1@0+ (1,0) [0|1] "" CSM,TCP
 SG_ DTCI_CMMa_TstFldOpCyc : 42|1@0+ (1,0) [0|1] "" CSM,TCP
 SG_ DTCI_CMMa_TstFldLstClr : 43|1@0+ (1,0) [0|1] "" CSM,TCP
 SG_ DTCI_CMMa_TstFld : 44|1@0+ (1,0) [0|1] "" CSM,TCP
 SG_ DTCI_CMMa_PndngDTC : 45|1@0+ (1,0) [0|1] "" CSM,TCP
 SG_ DTCI_CMMa_DTCTriggered : 46|1@0+ (1,0) [0|1] "" CSM,TCP
 SG_ DTCI_CMMa_WrnIndTrggrd : 54|1@0+ (1,0) [0|1] "" CSM,TCP
 SG_ DTCI_CMMa_WrnIndRqd : 55|1@0+ (1,0) [0|1] "" CSM,TCP

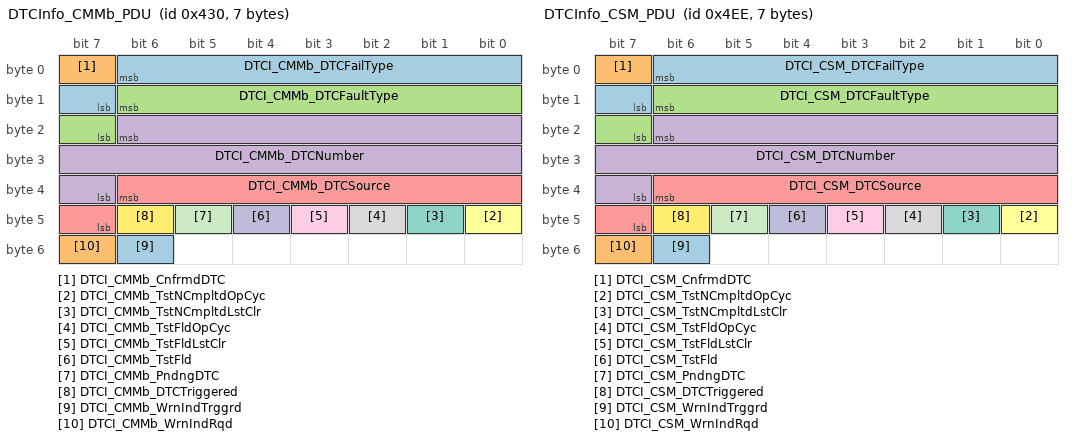
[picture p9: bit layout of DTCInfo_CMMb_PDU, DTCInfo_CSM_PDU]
BO_ 1072 DTCInfo_CMMb_PDU: 7 CGM
 SG_ DTCI_CMMb_DTCFailType : 6|8@0+ (1,0) [0|255] "" CSM,TCP
 SG_ DTCI_CMMb_CnfrmdDTC : 7|1@0+ (1,0) [0|1] "" CSM,TCP
 SG_ DTCI_CMMb_DTCFaultType : 14|8@0+ (1,0) [0|3] "" CSM,TCP
 SG_ DTCI_CMMb_DTCNumber : 22|16@0+ (1,0) [0|65535] "" CSM,TCP
 SG_ DTCI_CMMb_DTCSource : 38|8@0+ (1,0) [0|255] "" CSM,TCP
 SG_ DTCI_CMMb_TstNCmpltdOpCyc : 40|1@0+ (1,0) [0|1] "" CSM,TCP
 SG_ DTCI_CMMb_TstNCmpltdLstClr : 41|1@0+ (1,0) [0|1] "" CSM,TCP
 SG_ DTCI_CMMb_TstFldOpCyc : 42|1@0+ (1,0) [0|1] "" CSM,TCP
 SG_ DTCI_CMMb_TstFldLstClr : 43|1@0+ (1,0) [0|1] "" CSM,TCP
 SG_ DTCI_CMMb_TstFld : 44|1@0+ (1,0) [0|1] "" CSM,TCP
 SG_ DTCI_CMMb_PndngDTC : 45|1@0+ (1,0) [0|1] "" CSM,TCP
 SG_ DTCI_CMMb_DTCTriggered : 46|1@0+ (1,0) [0|1] "" CSM,TCP
 SG_ DTCI_CMMb_WrnIndTrggrd : 54|1@0+ (1,0) [0|1] "" CSM,TCP
 SG_ DTCI_CMMb_WrnIndRqd : 55|1@0+ (1,0) [0|1] "" CSM,TCP

BO_ 1262 DTCInfo_CSM_PDU: 7 CSM
 SG_ DTCI_CSM_DTCFailType : 6|8@0+ (1,0) [0|255] "" CSM,TCP
 SG_ DTCI_CSM_CnfrmdDTC : 7|1@0+ (1,0) [0|1] "" CSM,TCP
 SG_ DTCI_CSM_DTCFaultType : 14|8@0+ (1,0) [0|3] "" CSM,TCP
 SG_ DTCI_CSM_DTCNumber : 22|16@0+ (1,0) [0|65535] "" CSM,TCP
 SG_ DTCI_CSM_DTCSource : 38|8@0+ (1,0) [0|255] "" CGM,CSM,TCP
 SG_ DTCI_CSM_TstNCmpltdOpCyc : 40|1@0+ (1,0) [0|1] "" CSM,TCP
 SG_ DTCI_CSM_TstNCmpltdLstClr : 41|1@0+ (1,0) [0|1] "" CSM,TCP
 SG_ DTCI_CSM_TstFldOpCyc : 42|1@0+ (1,0) [0|1] "" CSM,TCP
 SG_ DTCI_CSM_TstFldLstClr : 43|1@0+ (1,0) [0|1] "" CSM,TCP
 SG_ DTCI_CSM_TstFld : 44|1@0+ (1,0) [0|1] "" CSM,TCP
 SG_ DTCI_CSM_PndngDTC : 45|1@0+ (1,0) [0|1] "" CSM,TCP
 SG_ DTCI_CSM_DTCTriggered : 46|1@0+ (1,0) [0|1] "" CSM,TCP
 SG_ DTCI_CSM_WrnIndTrggrd : 54|1@0+ (1,0) [0|1] "" CSM,TCP
 SG_ DTCI_CSM_WrnIndRqd : 55|1@0+ (1,0) [0|1] "" CSM,TCP

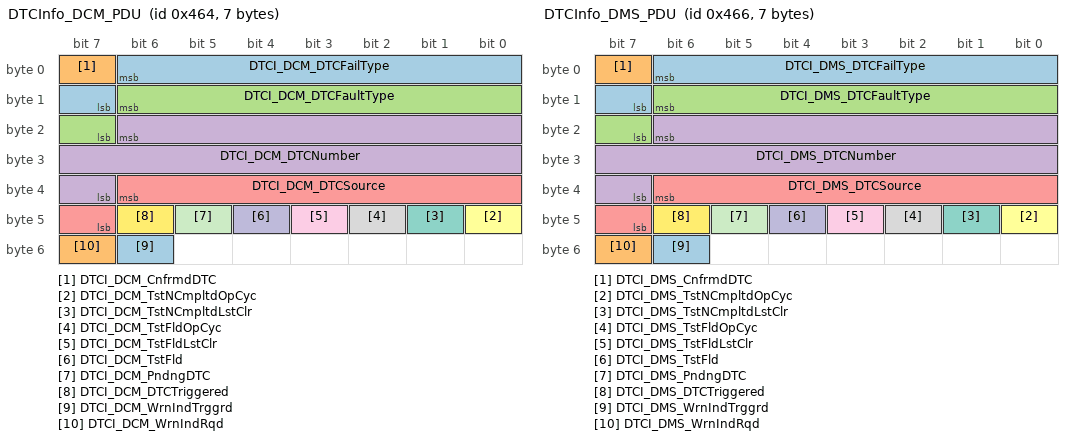
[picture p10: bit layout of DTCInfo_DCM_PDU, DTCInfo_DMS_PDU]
BO_ 1124 DTCInfo_DCM_PDU: 7 CGM
 SG_ DTCI_DCM_DTCFailType : 6|8@0+ (1,0) [0|255] "" CSM,TCP
 SG_ DTCI_DCM_CnfrmdDTC : 7|1@0+ (1,0) [0|1] "" CSM,TCP
 SG_ DTCI_DCM_DTCFaultType : 14|8@0+ (1,0) [0|3] "" CSM,TCP
 SG_ DTCI_DCM_DTCNumber : 22|16@0+ (1,0) [0|65535] "" CSM,TCP
 SG_ DTCI_DCM_DTCSource : 38|8@0+ (1,0) [0|255] "" CSM,TCP
 SG_ DTCI_DCM_TstNCmpltdOpCyc : 40|1@0+ (1,0) [0|1] "" CSM,TCP
 SG_ DTCI_DCM_TstNCmpltdLstClr : 41|1@0+ (1,0) [0|1] "" CSM,TCP
 SG_ DTCI_DCM_TstFldOpCyc : 42|1@0+ (1,0) [0|1] "" CSM,TCP
 SG_ DTCI_DCM_TstFldLstClr : 43|1@0+ (1,0) [0|1] "" CSM,TCP
 SG_ DTCI_DCM_TstFld : 44|1@0+ (1,0) [0|1] "" CSM,TCP
 SG_ DTCI_DCM_PndngDTC : 45|1@0+ (1,0) [0|1] "" CSM,TCP
 SG_ DTCI_DCM_DTCTriggered : 46|1@0+ (1,0) [0|1] "" CSM,TCP
 SG_ DTCI_DCM_WrnIndTrggrd : 54|1@0+ (1,0) [0|1] "" CSM,TCP
 SG_ DTCI_DCM_WrnIndRqd : 55|1@0+ (1,0) [0|1] "" CSM,TCP

BO_ 1126 DTCInfo_DMS_PDU: 7 CGM
 SG_ DTCI_DMS_DTCFailType : 6|8@0+ (1,0) [0|255] "" CSM,TCP
 SG_ DTCI_DMS_CnfrmdDTC : 7|1@0+ (1,0) [0|1] "" CSM,TCP
 SG_ DTCI_DMS_DTCFaultType : 14|8@0+ (1,0) [0|3] "" CSM,TCP
 SG_ DTCI_DMS_DTCNumber : 22|16@0+ (1,0) [0|65535] "" CSM,TCP
 SG_ DTCI_DMS_DTCSource : 38|8@0+ (1,0) [0|255] "" CSM,TCP
 SG_ DTCI_DMS_TstNCmpltdOpCyc : 40|1@0+ (1,0) [0|1] "" CSM,TCP
 SG_ DTCI_DMS_TstNCmpltdLstClr : 41|1@0+ (1,0) [0|1] "" CSM,TCP
 SG_ DTCI_DMS_TstFldOpCyc : 42|1@0+ (1,0) [0|1] "" CSM,TCP
 SG_ DTCI_DMS_TstFldLstClr : 43|1@0+ (1,0) [0|1] "" CSM,TCP
 SG_ DTCI_DMS_TstFld : 44|1@0+ (1,0) [0|1] "" CSM,TCP
 SG_ DTCI_DMS_PndngDTC : 45|1@0+ (1,0) [0|1] "" CSM,TCP
 SG_ DTCI_DMS_DTCTriggered : 46|1@0+ (1,0) [0|1] "" CSM,TCP
 SG_ DTCI_DMS_WrnIndTrggrd : 54|1@0+ (1,0) [0|1] "" CSM,TCP
 SG_ DTCI_DMS_WrnIndRqd : 55|1@0+ (1,0) [0|1] "" CSM,TCP

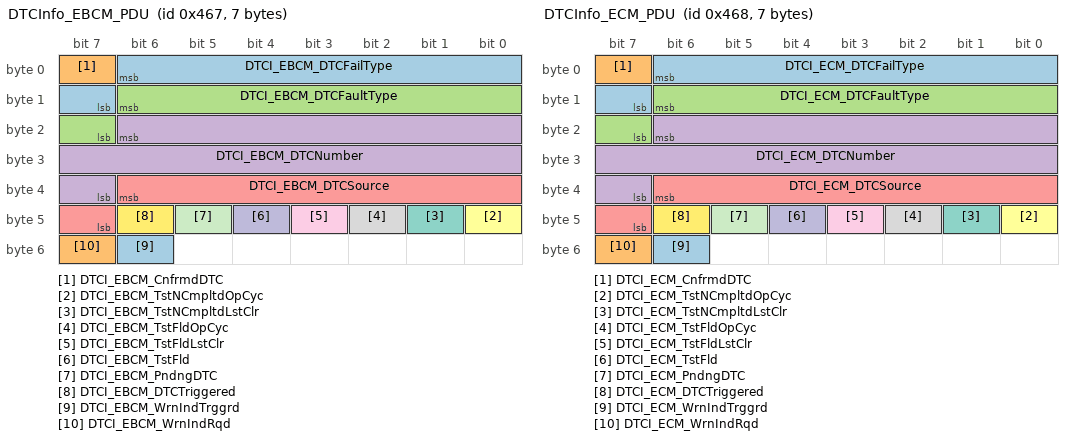
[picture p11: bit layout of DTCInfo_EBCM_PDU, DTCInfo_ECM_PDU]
BO_ 1127 DTCInfo_EBCM_PDU: 7 CGM
 SG_ DTCI_EBCM_DTCFailType : 6|8@0+ (1,0) [0|255] "" CSM,TCP
 SG_ DTCI_EBCM_CnfrmdDTC : 7|1@0+ (1,0) [0|1] "" CSM,TCP
 SG_ DTCI_EBCM_DTCFaultType : 14|8@0+ (1,0) [0|3] "" CSM,TCP
 SG_ DTCI_EBCM_DTCNumber : 22|16@0+ (1,0) [0|65535] "" CSM,TCP
 SG_ DTCI_EBCM_DTCSource : 38|8@0+ (1,0) [0|255] "" CSM,TCP
 SG_ DTCI_EBCM_TstNCmpltdOpCyc : 40|1@0+ (1,0) [0|1] "" CSM,TCP
 SG_ DTCI_EBCM_TstNCmpltdLstClr : 41|1@0+ (1,0) [0|1] "" CSM,TCP
 SG_ DTCI_EBCM_TstFldOpCyc : 42|1@0+ (1,0) [0|1] "" CSM,TCP
 SG_ DTCI_EBCM_TstFldLstClr : 43|1@0+ (1,0) [0|1] "" CSM,TCP
 SG_ DTCI_EBCM_TstFld : 44|1@0+ (1,0) [0|1] "" CSM,TCP
 SG_ DTCI_EBCM_PndngDTC : 45|1@0+ (1,0) [0|1] "" CSM,TCP
 SG_ DTCI_EBCM_DTCTriggered : 46|1@0+ (1,0) [0|1] "" CSM,TCP
 SG_ DTCI_EBCM_WrnIndTrggrd : 54|1@0+ (1,0) [0|1] "" CSM,TCP
 SG_ DTCI_EBCM_WrnIndRqd : 55|1@0+ (1,0) [0|1] "" CSM,TCP

BO_ 1128 DTCInfo_ECM_PDU: 7 CGM
 SG_ DTCI_ECM_DTCFailType : 6|8@0+ (1,0) [0|255] "" CSM,TCP
 SG_ DTCI_ECM_CnfrmdDTC : 7|1@0+ (1,0) [0|1] "" CSM,TCP
 SG_ DTCI_ECM_DTCFaultType : 14|8@0+ (1,0) [0|3] "" CSM,TCP
 SG_ DTCI_ECM_DTCNumber : 22|16@0+ (1,0) [0|65535] "" CSM,TCP
 SG_ DTCI_ECM_DTCSource : 38|8@0+ (1,0) [0|255] "" CSM,TCP
 SG_ DTCI_ECM_TstNCmpltdOpCyc : 40|1@0+ (1,0) [0|1] "" CSM,TCP
 SG_ DTCI_ECM_TstNCmpltdLstClr : 41|1@0+ (1,0) [0|1] "" CSM,TCP
 SG_ DTCI_ECM_TstFldOpCyc : 42|1@0+ (1,0) [0|1] "" CSM,TCP
 SG_ DTCI_ECM_TstFldLstClr : 43|1@0+ (1,0) [0|1] "" CSM,TCP
 SG_ DTCI_ECM_TstFld : 44|1@0+ (1,0) [0|1] "" CSM,TCP
 SG_ DTCI_ECM_PndngDTC : 45|1@0+ (1,0) [0|1] "" CSM,TCP
 SG_ DTCI_ECM_DTCTriggered : 46|1@0+ (1,0) [0|1] "" CSM,TCP
 SG_ DTCI_ECM_WrnIndTrggrd : 54|1@0+ (1,0) [0|1] "" CSM,TCP
 SG_ DTCI_ECM_WrnIndRqd : 55|1@0+ (1,0) [0|1] "" CSM,TCP

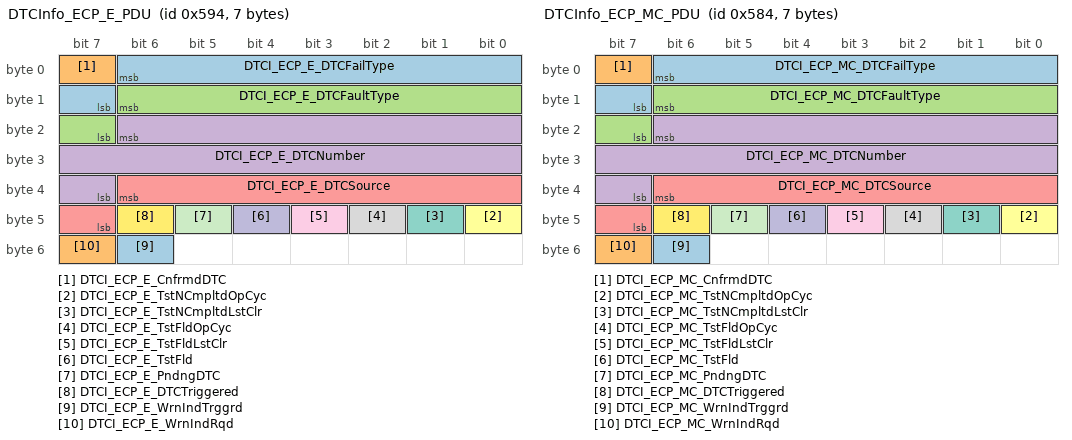
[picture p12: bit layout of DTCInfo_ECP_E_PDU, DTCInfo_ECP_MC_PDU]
BO_ 1428 DTCInfo_ECP_E_PDU: 7 CGM
 SG_ DTCI_ECP_E_DTCFailType : 6|8@0+ (1,0) [0|255] "" CSM,TCP
 SG_ DTCI_ECP_E_CnfrmdDTC : 7|1@0+ (1,0) [0|1] "" CSM,TCP
 SG_ DTCI_ECP_E_DTCFaultType : 14|8@0+ (1,0) [0|3] "" CSM,TCP
 SG_ DTCI_ECP_E_DTCNumber : 22|16@0+ (1,0) [0|65535] "" CSM,TCP
 SG_ DTCI_ECP_E_DTCSource : 38|8@0+ (1,0) [0|255] "" CSM,TCP
 SG_ DTCI_ECP_E_TstNCmpltdOpCyc : 40|1@0+ (1,0) [0|1] "" CSM,TCP
 SG_ DTCI_ECP_E_TstNCmpltdLstClr : 41|1@0+ (1,0) [0|1] "" CSM,TCP
 SG_ DTCI_ECP_E_TstFldOpCyc : 42|1@0+ (1,0) [0|1] "" CSM,TCP
 SG_ DTCI_ECP_E_TstFldLstClr : 43|1@0+ (1,0) [0|1] "" CSM,TCP
 SG_ DTCI_ECP_E_TstFld : 44|1@0+ (1,0) [0|1] "" CSM,TCP
 SG_ DTCI_ECP_E_PndngDTC : 45|1@0+ (1,0) [0|1] "" CSM,TCP
 SG_ DTCI_ECP_E_DTCTriggered : 46|1@0+ (1,0) [0|1] "" CSM,TCP
 SG_ DTCI_ECP_E_WrnIndTrggrd : 54|1@0+ (1,0) [0|1] "" CSM,TCP
 SG_ DTCI_ECP_E_WrnIndRqd : 55|1@0+ (1,0) [0|1] "" CSM,TCP

BO_ 1412 DTCInfo_ECP_MC_PDU: 7 CGM
 SG_ DTCI_ECP_MC_DTCFailType : 6|8@0+ (1,0) [0|255] "" CSM,TCP
 SG_ DTCI_ECP_MC_CnfrmdDTC : 7|1@0+ (1,0) [0|1] "" CSM,TCP
 SG_ DTCI_ECP_MC_DTCFaultType : 14|8@0+ (1,0) [0|3] "" CSM,TCP
 SG_ DTCI_ECP_MC_DTCNumber : 22|16@0+ (1,0) [0|65535] "" CSM,TCP
 SG_ DTCI_ECP_MC_DTCSource : 38|8@0+ (1,0) [0|255] "" CSM,TCP
 SG_ DTCI_ECP_MC_TstNCmpltdOpCyc : 40|1@0+ (1,0) [0|1] "" CSM,TCP
 SG_ DTCI_ECP_MC_TstNCmpltdLstClr : 41|1@0+ (1,0) [0|1] "" CSM,TCP
 SG_ DTCI_ECP_MC_TstFldOpCyc : 42|1@0+ (1,0) [0|1] "" CSM,TCP
 SG_ DTCI_ECP_MC_TstFldLstClr : 43|1@0+ (1,0) [0|1] "" CSM,TCP
 SG_ DTCI_ECP_MC_TstFld : 44|1@0+ (1,0) [0|1] "" CSM,TCP
 SG_ DTCI_ECP_MC_PndngDTC : 45|1@0+ (1,0) [0|1] "" CSM,TCP
 SG_ DTCI_ECP_MC_DTCTriggered : 46|1@0+ (1,0) [0|1] "" CSM,TCP
 SG_ DTCI_ECP_MC_WrnIndTrggrd : 54|1@0+ (1,0) [0|1] "" CSM,TCP
 SG_ DTCI_ECP_MC_WrnIndRqd : 55|1@0+ (1,0) [0|1] "" CSM,TCP

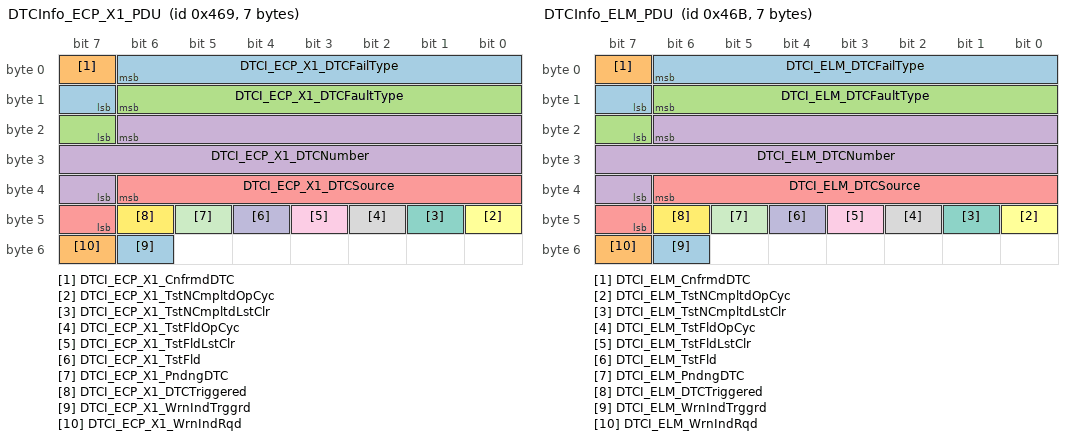
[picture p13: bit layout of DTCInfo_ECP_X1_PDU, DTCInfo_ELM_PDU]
BO_ 1129 DTCInfo_ECP_X1_PDU: 7 CGM
 SG_ DTCI_ECP_X1_DTCFailType : 6|8@0+ (1,0) [0|255] "" CSM,TCP
 SG_ DTCI_ECP_X1_CnfrmdDTC : 7|1@0+ (1,0) [0|1] "" CSM,TCP
 SG_ DTCI_ECP_X1_DTCFaultType : 14|8@0+ (1,0) [0|3] "" CSM,TCP
 SG_ DTCI_ECP_X1_DTCNumber : 22|16@0+ (1,0) [0|65535] "" CSM,TCP
 SG_ DTCI_ECP_X1_DTCSource : 38|8@0+ (1,0) [0|255] "" CSM,TCP
 SG_ DTCI_ECP_X1_TstNCmpltdOpCyc : 40|1@0+ (1,0) [0|1] "" CSM,TCP
 SG_ DTCI_ECP_X1_TstNCmpltdLstClr : 41|1@0+ (1,0) [0|1] "" CSM,TCP
 SG_ DTCI_ECP_X1_TstFldOpCyc : 42|1@0+ (1,0) [0|1] "" CSM,TCP
 SG_ DTCI_ECP_X1_TstFldLstClr : 43|1@0+ (1,0) [0|1] "" CSM,TCP
 SG_ DTCI_ECP_X1_TstFld : 44|1@0+ (1,0) [0|1] "" CSM,TCP
 SG_ DTCI_ECP_X1_PndngDTC : 45|1@0+ (1,0) [0|1] "" CSM,TCP
 SG_ DTCI_ECP_X1_DTCTriggered : 46|1@0+ (1,0) [0|1] "" CSM,TCP
 SG_ DTCI_ECP_X1_WrnIndTrggrd : 54|1@0+ (1,0) [0|1] "" CSM,TCP
 SG_ DTCI_ECP_X1_WrnIndRqd : 55|1@0+ (1,0) [0|1] "" CSM,TCP

BO_ 1131 DTCInfo_ELM_PDU: 7 CGM
 SG_ DTCI_ELM_DTCFailType : 6|8@0+ (1,0) [0|255] "" CSM,TCP
 SG_ DTCI_ELM_CnfrmdDTC : 7|1@0+ (1,0) [0|1] "" CSM,TCP
 SG_ DTCI_ELM_DTCFaultType : 14|8@0+ (1,0) [0|3] "" CSM,TCP
 SG_ DTCI_ELM_DTCNumber : 22|16@0+ (1,0) [0|65535] "" CSM,TCP
 SG_ DTCI_ELM_DTCSource : 38|8@0+ (1,0) [0|255] "" CSM,TCP
 SG_ DTCI_ELM_TstNCmpltdOpCyc : 40|1@0+ (1,0) [0|1] "" CSM,TCP
 SG_ DTCI_ELM_TstNCmpltdLstClr : 41|1@0+ (1,0) [0|1] "" CSM,TCP
 SG_ DTCI_ELM_TstFldOpCyc : 42|1@0+ (1,0) [0|1] "" CSM,TCP
 SG_ DTCI_ELM_TstFldLstClr : 43|1@0+ (1,0) [0|1] "" CSM,TCP
 SG_ DTCI_ELM_TstFld : 44|1@0+ (1,0) [0|1] "" CSM,TCP
 SG_ DTCI_ELM_PndngDTC : 45|1@0+ (1,0) [0|1] "" CSM,TCP
 SG_ DTCI_ELM_DTCTriggered : 46|1@0+ (1,0) [0|1] "" CSM,TCP
 SG_ DTCI_ELM_WrnIndTrggrd : 54|1@0+ (1,0) [0|1] "" CSM,TCP
 SG_ DTCI_ELM_WrnIndRqd : 55|1@0+ (1,0) [0|1] "" CSM,TCP

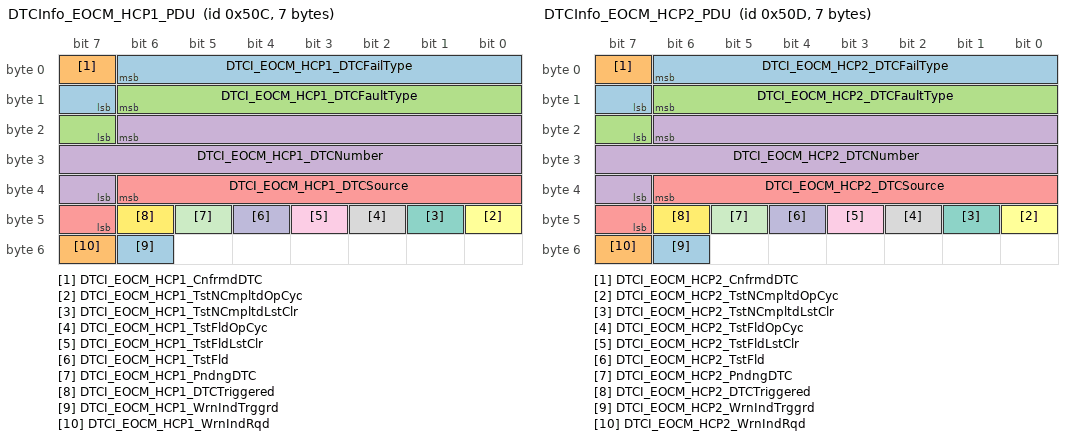
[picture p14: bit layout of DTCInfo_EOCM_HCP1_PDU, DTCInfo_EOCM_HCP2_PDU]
BO_ 1292 DTCInfo_EOCM_HCP1_PDU: 7 CGM
 SG_ DTCI_EOCM_HCP1_DTCFailType : 6|8@0+ (1,0) [0|255] "" CSM,TCP
 SG_ DTCI_EOCM_HCP1_CnfrmdDTC : 7|1@0+ (1,0) [0|1] "" CSM,TCP
 SG_ DTCI_EOCM_HCP1_DTCFaultType : 14|8@0+ (1,0) [0|3] "" CSM,TCP
 SG_ DTCI_EOCM_HCP1_DTCNumber : 22|16@0+ (1,0) [0|65535] "" CSM,TCP
 SG_ DTCI_EOCM_HCP1_DTCSource : 38|8@0+ (1,0) [0|255] "" CSM,TCP
 SG_ DTCI_EOCM_HCP1_TstNCmpltdOpCyc : 40|1@0+ (1,0) [0|1] "" CSM,TCP
 SG_ DTCI_EOCM_HCP1_TstNCmpltdLstClr : 41|1@0+ (1,0) [0|1] "" CSM,TCP
 SG_ DTCI_EOCM_HCP1_TstFldOpCyc : 42|1@0+ (1,0) [0|1] "" CSM,TCP
 SG_ DTCI_EOCM_HCP1_TstFldLstClr : 43|1@0+ (1,0) [0|1] "" CSM,TCP
 SG_ DTCI_EOCM_HCP1_TstFld : 44|1@0+ (1,0) [0|1] "" CSM,TCP
 SG_ DTCI_EOCM_HCP1_PndngDTC : 45|1@0+ (1,0) [0|1] "" CSM,TCP
 SG_ DTCI_EOCM_HCP1_DTCTriggered : 46|1@0+ (1,0) [0|1] "" CSM,TCP
 SG_ DTCI_EOCM_HCP1_WrnIndTrggrd : 54|1@0+ (1,0) [0|1] "" CSM,TCP
 SG_ DTCI_EOCM_HCP1_WrnIndRqd : 55|1@0+ (1,0) [0|1] "" CSM,TCP

BO_ 1293 DTCInfo_EOCM_HCP2_PDU: 7 CGM
 SG_ DTCI_EOCM_HCP2_DTCFailType : 6|8@0+ (1,0) [0|255] "" CSM,TCP
 SG_ DTCI_EOCM_HCP2_CnfrmdDTC : 7|1@0+ (1,0) [0|1] "" CSM,TCP
 SG_ DTCI_EOCM_HCP2_DTCFaultType : 14|8@0+ (1,0) [0|3] "" CSM,TCP
 SG_ DTCI_EOCM_HCP2_DTCNumber : 22|16@0+ (1,0) [0|65535] "" CSM,TCP
 SG_ DTCI_EOCM_HCP2_DTCSource : 38|8@0+ (1,0) [0|255] "" CSM,TCP
 SG_ DTCI_EOCM_HCP2_TstNCmpltdOpCyc : 40|1@0+ (1,0) [0|1] "" CSM,TCP
 SG_ DTCI_EOCM_HCP2_TstNCmpltdLstClr : 41|1@0+ (1,0) [0|1] "" CSM,TCP
 SG_ DTCI_EOCM_HCP2_TstFldOpCyc : 42|1@0+ (1,0) [0|1] "" CSM,TCP
 SG_ DTCI_EOCM_HCP2_TstFldLstClr : 43|1@0+ (1,0) [0|1] "" CSM,TCP
 SG_ DTCI_EOCM_HCP2_TstFld : 44|1@0+ (1,0) [0|1] "" CSM,TCP
 SG_ DTCI_EOCM_HCP2_PndngDTC : 45|1@0+ (1,0) [0|1] "" CSM,TCP
 SG_ DTCI_EOCM_HCP2_DTCTriggered : 46|1@0+ (1,0) [0|1] "" CSM,TCP
 SG_ DTCI_EOCM_HCP2_WrnIndTrggrd : 54|1@0+ (1,0) [0|1] "" CSM,TCP
 SG_ DTCI_EOCM_HCP2_WrnIndRqd : 55|1@0+ (1,0) [0|1] "" CSM,TCP

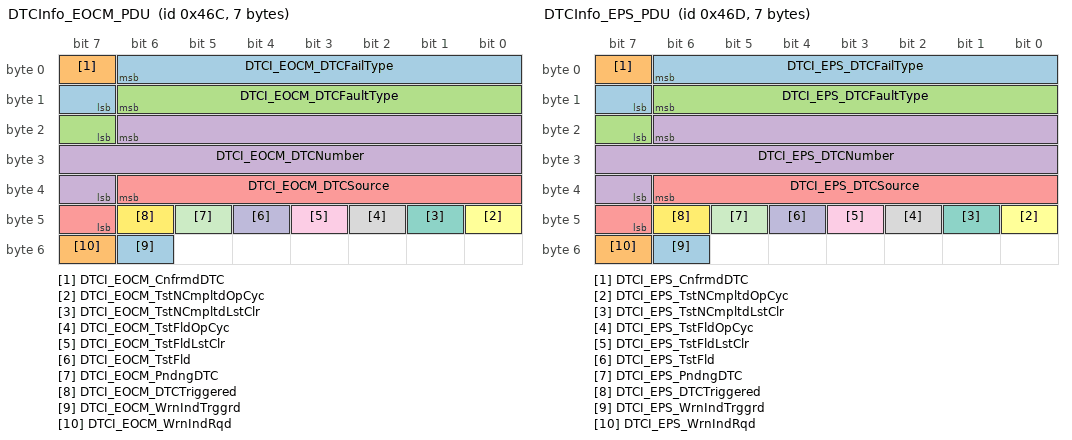
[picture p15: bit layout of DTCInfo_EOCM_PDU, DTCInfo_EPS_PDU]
BO_ 1132 DTCInfo_EOCM_PDU: 7 CGM
 SG_ DTCI_EOCM_DTCFailType : 6|8@0+ (1,0) [0|255] "" CSM,TCP
 SG_ DTCI_EOCM_CnfrmdDTC : 7|1@0+ (1,0) [0|1] "" CSM,TCP
 SG_ DTCI_EOCM_DTCFaultType : 14|8@0+ (1,0) [0|3] "" CSM,TCP
 SG_ DTCI_EOCM_DTCNumber : 22|16@0+ (1,0) [0|65535] "" CSM,TCP
 SG_ DTCI_EOCM_DTCSource : 38|8@0+ (1,0) [0|255] "" CSM,TCP
 SG_ DTCI_EOCM_TstNCmpltdOpCyc : 40|1@0+ (1,0) [0|1] "" CSM,TCP
 SG_ DTCI_EOCM_TstNCmpltdLstClr : 41|1@0+ (1,0) [0|1] "" CSM,TCP
 SG_ DTCI_EOCM_TstFldOpCyc : 42|1@0+ (1,0) [0|1] "" CSM,TCP
 SG_ DTCI_EOCM_TstFldLstClr : 43|1@0+ (1,0) [0|1] "" CSM,TCP
 SG_ DTCI_EOCM_TstFld : 44|1@0+ (1,0) [0|1] "" CSM,TCP
 SG_ DTCI_EOCM_PndngDTC : 45|1@0+ (1,0) [0|1] "" CSM,TCP
 SG_ DTCI_EOCM_DTCTriggered : 46|1@0+ (1,0) [0|1] "" CSM,TCP
 SG_ DTCI_EOCM_WrnIndTrggrd : 54|1@0+ (1,0) [0|1] "" CSM,TCP
 SG_ DTCI_EOCM_WrnIndRqd : 55|1@0+ (1,0) [0|1] "" CSM,TCP

BO_ 1133 DTCInfo_EPS_PDU: 7 CGM
 SG_ DTCI_EPS_DTCFailType : 6|8@0+ (1,0) [0|255] "" CSM,TCP
 SG_ DTCI_EPS_CnfrmdDTC : 7|1@0+ (1,0) [0|1] "" CSM,TCP
 SG_ DTCI_EPS_DTCFaultType : 14|8@0+ (1,0) [0|3] "" CSM,TCP
 SG_ DTCI_EPS_DTCNumber : 22|16@0+ (1,0) [0|65535] "" CSM,TCP
 SG_ DTCI_EPS_DTCSource : 38|8@0+ (1,0) [0|255] "" CSM,TCP
 SG_ DTCI_EPS_TstNCmpltdOpCyc : 40|1@0+ (1,0) [0|1] "" CSM,TCP
 SG_ DTCI_EPS_TstNCmpltdLstClr : 41|1@0+ (1,0) [0|1] "" CSM,TCP
 SG_ DTCI_EPS_TstFldOpCyc : 42|1@0+ (1,0) [0|1] "" CSM,TCP
 SG_ DTCI_EPS_TstFldLstClr : 43|1@0+ (1,0) [0|1] "" CSM,TCP
 SG_ DTCI_EPS_TstFld : 44|1@0+ (1,0) [0|1] "" CSM,TCP
 SG_ DTCI_EPS_PndngDTC : 45|1@0+ (1,0) [0|1] "" CSM,TCP
 SG_ DTCI_EPS_DTCTriggered : 46|1@0+ (1,0) [0|1] "" CSM,TCP
 SG_ DTCI_EPS_WrnIndTrggrd : 54|1@0+ (1,0) [0|1] "" CSM,TCP
 SG_ DTCI_EPS_WrnIndRqd : 55|1@0+ (1,0) [0|1] "" CSM,TCP

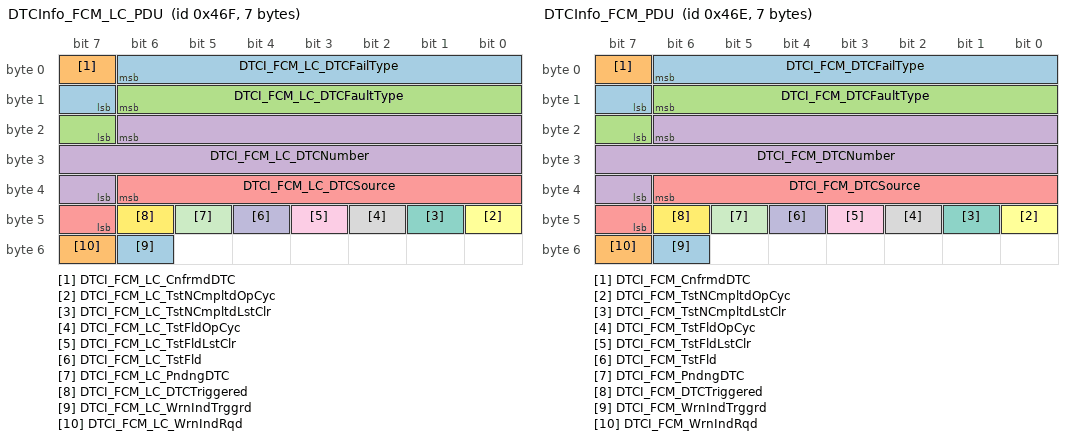
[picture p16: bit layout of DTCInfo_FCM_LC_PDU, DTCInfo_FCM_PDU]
BO_ 1135 DTCInfo_FCM_LC_PDU: 7 CGM
 SG_ DTCI_FCM_LC_DTCFailType : 6|8@0+ (1,0) [0|255] "" CSM,TCP
 SG_ DTCI_FCM_LC_CnfrmdDTC : 7|1@0+ (1,0) [0|1] "" CSM,TCP
 SG_ DTCI_FCM_LC_DTCFaultType : 14|8@0+ (1,0) [0|3] "" CSM,TCP
 SG_ DTCI_FCM_LC_DTCNumber : 22|16@0+ (1,0) [0|65535] "" CSM,TCP
 SG_ DTCI_FCM_LC_DTCSource : 38|8@0+ (1,0) [0|255] "" CSM,TCP
 SG_ DTCI_FCM_LC_TstNCmpltdOpCyc : 40|1@0+ (1,0) [0|1] "" CSM,TCP
 SG_ DTCI_FCM_LC_TstNCmpltdLstClr : 41|1@0+ (1,0) [0|1] "" CSM,TCP
 SG_ DTCI_FCM_LC_TstFldOpCyc : 42|1@0+ (1,0) [0|1] "" CSM,TCP
 SG_ DTCI_FCM_LC_TstFldLstClr : 43|1@0+ (1,0) [0|1] "" CSM,TCP
 SG_ DTCI_FCM_LC_TstFld : 44|1@0+ (1,0) [0|1] "" CSM,TCP
 SG_ DTCI_FCM_LC_PndngDTC : 45|1@0+ (1,0) [0|1] "" CSM,TCP
 SG_ DTCI_FCM_LC_DTCTriggered : 46|1@0+ (1,0) [0|1] "" CSM,TCP
 SG_ DTCI_FCM_LC_WrnIndTrggrd : 54|1@0+ (1,0) [0|1] "" CSM,TCP
 SG_ DTCI_FCM_LC_WrnIndRqd : 55|1@0+ (1,0) [0|1] "" CSM,TCP

BO_ 1134 DTCInfo_FCM_PDU: 7 CGM
 SG_ DTCI_FCM_DTCFailType : 6|8@0+ (1,0) [0|255] "" CSM,TCP
 SG_ DTCI_FCM_CnfrmdDTC : 7|1@0+ (1,0) [0|1] "" CSM,TCP
 SG_ DTCI_FCM_DTCFaultType : 14|8@0+ (1,0) [0|3] "" CSM,TCP
 SG_ DTCI_FCM_DTCNumber : 22|16@0+ (1,0) [0|65535] "" CSM,TCP
 SG_ DTCI_FCM_DTCSource : 38|8@0+ (1,0) [0|255] "" CSM,TCP
 SG_ DTCI_FCM_TstNCmpltdOpCyc : 40|1@0+ (1,0) [0|1] "" CSM,TCP
 SG_ DTCI_FCM_TstNCmpltdLstClr : 41|1@0+ (1,0) [0|1] "" CSM,TCP
 SG_ DTCI_FCM_TstFldOpCyc : 42|1@0+ (1,0) [0|1] "" CSM,TCP
 SG_ DTCI_FCM_TstFldLstClr : 43|1@0+ (1,0) [0|1] "" CSM,TCP
 SG_ DTCI_FCM_TstFld : 44|1@0+ (1,0) [0|1] "" CSM,TCP
 SG_ DTCI_FCM_PndngDTC : 45|1@0+ (1,0) [0|1] "" CSM,TCP
 SG_ DTCI_FCM_DTCTriggered : 46|1@0+ (1,0) [0|1] "" CSM,TCP
 SG_ DTCI_FCM_WrnIndTrggrd : 54|1@0+ (1,0) [0|1] "" CSM,TCP
 SG_ DTCI_FCM_WrnIndRqd : 55|1@0+ (1,0) [0|1] "" CSM,TCP

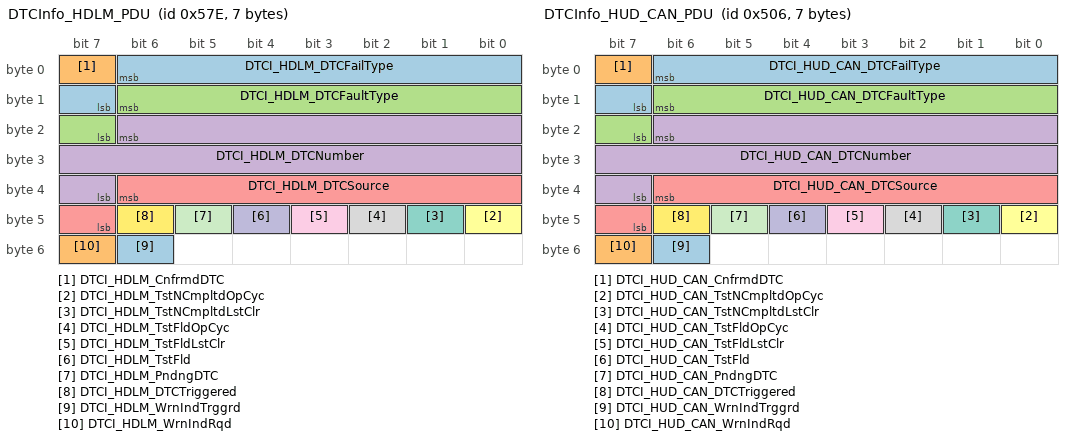
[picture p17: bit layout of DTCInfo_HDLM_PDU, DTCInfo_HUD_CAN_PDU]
BO_ 1406 DTCInfo_HDLM_PDU: 7 CGM
 SG_ DTCI_HDLM_DTCFailType : 6|8@0+ (1,0) [0|255] "" CSM,TCP
 SG_ DTCI_HDLM_CnfrmdDTC : 7|1@0+ (1,0) [0|1] "" CSM,TCP
 SG_ DTCI_HDLM_DTCFaultType : 14|8@0+ (1,0) [0|3] "" CSM,TCP
 SG_ DTCI_HDLM_DTCNumber : 22|16@0+ (1,0) [0|65535] "" CSM,TCP
 SG_ DTCI_HDLM_DTCSource : 38|8@0+ (1,0) [0|255] "" CSM,TCP
 SG_ DTCI_HDLM_TstNCmpltdOpCyc : 40|1@0+ (1,0) [0|1] "" CSM,TCP
 SG_ DTCI_HDLM_TstNCmpltdLstClr : 41|1@0+ (1,0) [0|1] "" CSM,TCP
 SG_ DTCI_HDLM_TstFldOpCyc : 42|1@0+ (1,0) [0|1] "" CSM,TCP
 SG_ DTCI_HDLM_TstFldLstClr : 43|1@0+ (1,0) [0|1] "" CSM,TCP
 SG_ DTCI_HDLM_TstFld : 44|1@0+ (1,0) [0|1] "" CSM,TCP
 SG_ DTCI_HDLM_PndngDTC : 45|1@0+ (1,0) [0|1] "" CSM,TCP
 SG_ DTCI_HDLM_DTCTriggered : 46|1@0+ (1,0) [0|1] "" CSM,TCP
 SG_ DTCI_HDLM_WrnIndTrggrd : 54|1@0+ (1,0) [0|1] "" CSM,TCP
 SG_ DTCI_HDLM_WrnIndRqd : 55|1@0+ (1,0) [0|1] "" CSM,TCP

BO_ 1286 DTCInfo_HUD_CAN_PDU: 7 HUD_CAN
 SG_ DTCI_HUD_CAN_DTCFailType : 6|8@0+ (1,0) [0|255] "" CSM,TCP
 SG_ DTCI_HUD_CAN_CnfrmdDTC : 7|1@0+ (1,0) [0|1] "" CSM,TCP
 SG_ DTCI_HUD_CAN_DTCFaultType : 14|8@0+ (1,0) [0|3] "" CSM,TCP
 SG_ DTCI_HUD_CAN_DTCNumber : 22|16@0+ (1,0) [0|65535] "" CSM,TCP
 SG_ DTCI_HUD_CAN_DTCSource : 38|8@0+ (1,0) [0|255] "" CGM,CSM,TCP
 SG_ DTCI_HUD_CAN_TstNCmpltdOpCyc : 40|1@0+ (1,0) [0|1] "" CSM,TCP
 SG_ DTCI_HUD_CAN_TstNCmpltdLstClr : 41|1@0+ (1,0) [0|1] "" CSM,TCP
 SG_ DTCI_HUD_CAN_TstFldOpCyc : 42|1@0+ (1,0) [0|1] "" CSM,TCP
 SG_ DTCI_HUD_CAN_TstFldLstClr : 43|1@0+ (1,0) [0|1] "" CSM,TCP
 SG_ DTCI_HUD_CAN_TstFld : 44|1@0+ (1,0) [0|1] "" CSM,TCP
 SG_ DTCI_HUD_CAN_PndngDTC : 45|1@0+ (1,0) [0|1] "" CSM,TCP
 SG_ DTCI_HUD_CAN_DTCTriggered : 46|1@0+ (1,0) [0|1] "" CSM,TCP
 SG_ DTCI_HUD_CAN_WrnIndTrggrd : 54|1@0+ (1,0) [0|1] "" CSM,TCP
 SG_ DTCI_HUD_CAN_WrnIndRqd : 55|1@0+ (1,0) [0|1] "" CSM,TCP

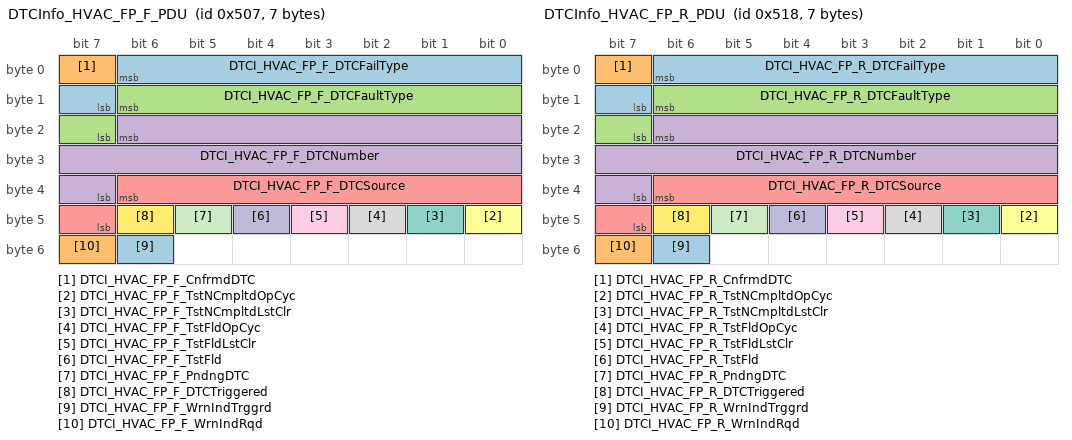
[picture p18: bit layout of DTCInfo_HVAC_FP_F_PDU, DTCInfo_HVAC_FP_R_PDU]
BO_ 1287 DTCInfo_HVAC_FP_F_PDU: 7 HVAC_FP_F
 SG_ DTCI_HVAC_FP_F_DTCFailType : 6|8@0+ (1,0) [0|255] "" CSM,TCP
 SG_ DTCI_HVAC_FP_F_CnfrmdDTC : 7|1@0+ (1,0) [0|1] "" CSM,TCP
 SG_ DTCI_HVAC_FP_F_DTCFaultType : 14|8@0+ (1,0) [0|3] "" CSM,TCP
 SG_ DTCI_HVAC_FP_F_DTCNumber : 22|16@0+ (1,0) [0|65535] "" CSM,TCP
 SG_ DTCI_HVAC_FP_F_DTCSource : 38|8@0+ (1,0) [0|255] "" CGM,CSM,TCP
 SG_ DTCI_HVAC_FP_F_TstNCmpltdOpCyc : 40|1@0+ (1,0) [0|1] "" CSM,TCP
 SG_ DTCI_HVAC_FP_F_TstNCmpltdLstClr : 41|1@0+ (1,0) [0|1] "" CSM,TCP
 SG_ DTCI_HVAC_FP_F_TstFldOpCyc : 42|1@0+ (1,0) [0|1] "" CSM,TCP
 SG_ DTCI_HVAC_FP_F_TstFldLstClr : 43|1@0+ (1,0) [0|1] "" CSM,TCP
 SG_ DTCI_HVAC_FP_F_TstFld : 44|1@0+ (1,0) [0|1] "" CSM,TCP
 SG_ DTCI_HVAC_FP_F_PndngDTC : 45|1@0+ (1,0) [0|1] "" CSM,TCP
 SG_ DTCI_HVAC_FP_F_DTCTriggered : 46|1@0+ (1,0) [0|1] "" CSM,TCP
 SG_ DTCI_HVAC_FP_F_WrnIndTrggrd : 54|1@0+ (1,0) [0|1] "" CSM,TCP
 SG_ DTCI_HVAC_FP_F_WrnIndRqd : 55|1@0+ (1,0) [0|1] "" CSM,TCP

BO_ 1304 DTCInfo_HVAC_FP_R_PDU: 7 HVAC_FP_R
 SG_ DTCI_HVAC_FP_R_DTCFailType : 6|8@0+ (1,0) [0|255] "" CSM,TCP
 SG_ DTCI_HVAC_FP_R_CnfrmdDTC : 7|1@0+ (1,0) [0|1] "" CSM,TCP
 SG_ DTCI_HVAC_FP_R_DTCFaultType : 14|8@0+ (1,0) [0|3] "" CSM,TCP
 SG_ DTCI_HVAC_FP_R_DTCNumber : 22|16@0+ (1,0) [0|65535] "" CSM,TCP
 SG_ DTCI_HVAC_FP_R_DTCSource : 38|8@0+ (1,0) [0|255] "" CGM,CSM,TCP
 SG_ DTCI_HVAC_FP_R_TstNCmpltdOpCyc : 40|1@0+ (1,0) [0|1] "" CSM,TCP
 SG_ DTCI_HVAC_FP_R_TstNCmpltdLstClr : 41|1@0+ (1,0) [0|1] "" CSM,TCP
 SG_ DTCI_HVAC_FP_R_TstFldOpCyc : 42|1@0+ (1,0) [0|1] "" CSM,TCP
 SG_ DTCI_HVAC_FP_R_TstFldLstClr : 43|1@0+ (1,0) [0|1] "" CSM,TCP
 SG_ DTCI_HVAC_FP_R_TstFld : 44|1@0+ (1,0) [0|1] "" CSM,TCP
 SG_ DTCI_HVAC_FP_R_PndngDTC : 45|1@0+ (1,0) [0|1] "" CSM,TCP
 SG_ DTCI_HVAC_FP_R_DTCTriggered : 46|1@0+ (1,0) [0|1] "" CSM,TCP
 SG_ DTCI_HVAC_FP_R_WrnIndTrggrd : 54|1@0+ (1,0) [0|1] "" CSM,TCP
 SG_ DTCI_HVAC_FP_R_WrnIndRqd : 55|1@0+ (1,0) [0|1] "" CSM,TCP

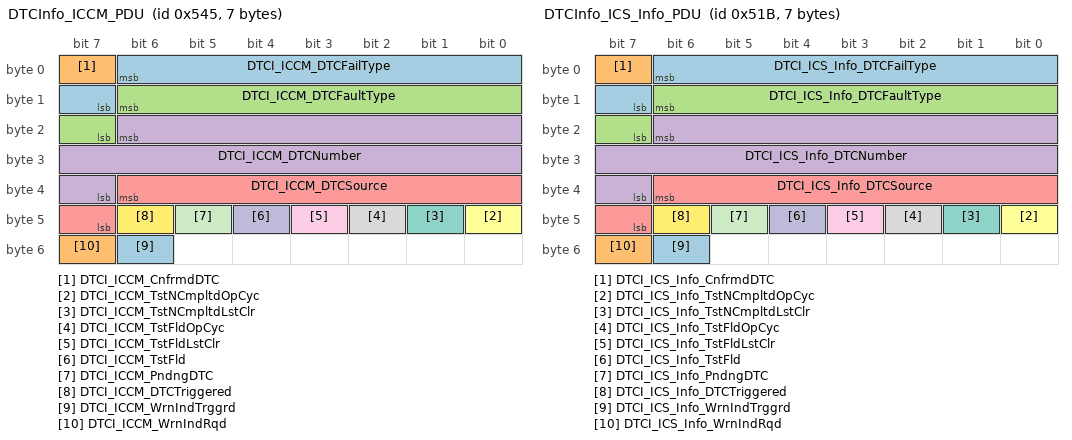
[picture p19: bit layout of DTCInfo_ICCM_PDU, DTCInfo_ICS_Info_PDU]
BO_ 1349 DTCInfo_ICCM_PDU: 7 CGM
 SG_ DTCI_ICCM_DTCFailType : 6|8@0+ (1,0) [0|255] "" CSM,TCP
 SG_ DTCI_ICCM_CnfrmdDTC : 7|1@0+ (1,0) [0|1] "" CSM,TCP
 SG_ DTCI_ICCM_DTCFaultType : 14|8@0+ (1,0) [0|3] "" CSM,TCP
 SG_ DTCI_ICCM_DTCNumber : 22|16@0+ (1,0) [0|65535] "" CSM,TCP
 SG_ DTCI_ICCM_DTCSource : 38|8@0+ (1,0) [0|255] "" CSM,TCP
 SG_ DTCI_ICCM_TstNCmpltdOpCyc : 40|1@0+ (1,0) [0|1] "" CSM,TCP
 SG_ DTCI_ICCM_TstNCmpltdLstClr : 41|1@0+ (1,0) [0|1] "" CSM,TCP
 SG_ DTCI_ICCM_TstFldOpCyc : 42|1@0+ (1,0) [0|1] "" CSM,TCP
 SG_ DTCI_ICCM_TstFldLstClr : 43|1@0+ (1,0) [0|1] "" CSM,TCP
 SG_ DTCI_ICCM_TstFld : 44|1@0+ (1,0) [0|1] "" CSM,TCP
 SG_ DTCI_ICCM_PndngDTC : 45|1@0+ (1,0) [0|1] "" CSM,TCP
 SG_ DTCI_ICCM_DTCTriggered : 46|1@0+ (1,0) [0|1] "" CSM,TCP
 SG_ DTCI_ICCM_WrnIndTrggrd : 54|1@0+ (1,0) [0|1] "" CSM,TCP
 SG_ DTCI_ICCM_WrnIndRqd : 55|1@0+ (1,0) [0|1] "" CSM,TCP

BO_ 1307 DTCInfo_ICS_Info_PDU: 7 ICS_Info
 SG_ DTCI_ICS_Info_DTCFailType : 6|8@0+ (1,0) [0|255] "" CSM,TCP
 SG_ DTCI_ICS_Info_CnfrmdDTC : 7|1@0+ (1,0) [0|1] "" CSM,TCP
 SG_ DTCI_ICS_Info_DTCFaultType : 14|8@0+ (1,0) [0|3] "" CSM,TCP
 SG_ DTCI_ICS_Info_DTCNumber : 22|16@0+ (1,0) [0|65535] "" CSM,TCP
 SG_ DTCI_ICS_Info_DTCSource : 38|8@0+ (1,0) [0|255] "" CGM,CSM,TCP
 SG_ DTCI_ICS_Info_TstNCmpltdOpCyc : 40|1@0+ (1,0) [0|1] "" CSM,TCP
 SG_ DTCI_ICS_Info_TstNCmpltdLstClr : 41|1@0+ (1,0) [0|1] "" CSM,TCP
 SG_ DTCI_ICS_Info_TstFldOpCyc : 42|1@0+ (1,0) [0|1] "" CSM,TCP
 SG_ DTCI_ICS_Info_TstFldLstClr : 43|1@0+ (1,0) [0|1] "" CSM,TCP
 SG_ DTCI_ICS_Info_TstFld : 44|1@0+ (1,0) [0|1] "" CSM,TCP
 SG_ DTCI_ICS_Info_PndngDTC : 45|1@0+ (1,0) [0|1] "" CSM,TCP
 SG_ DTCI_ICS_Info_DTCTriggered : 46|1@0+ (1,0) [0|1] "" CSM,TCP
 SG_ DTCI_ICS_Info_WrnIndTrggrd : 54|1@0+ (1,0) [0|1] "" CSM,TCP
 SG_ DTCI_ICS_Info_WrnIndRqd : 55|1@0+ (1,0) [0|1] "" CSM,TCP

BA_DEF_ SG_  "SignalType" STRING ;
BA_DEF_ SG_  "SignalLongName" STRING ;
BA_DEF_ BO_  "GenMsgCycleTime" INT 0 10000;
BA_DEF_ BO_  "GenMsgSendType" ENUM "cyclicX","spontanX","cyclicIfActiveX","spontanWithDelay","cyclicAndSpontanX","cyclicAndSpontanWithDelay","spontanWithRepetition","cyclicIfActiveAndSpontanWD";
BA_DEF_DEF_  "SignalType" "";
BA_DEF_DEF_  "SignalLongName" "";
BA_DEF_DEF_  "GenMsgCycleTime" 0;
BA_DEF_DEF_  "GenMsgSendType" "cyclicX";
BA_ "GenMsgCycleTime" BO_ 1470 1000;
BA_ "GenMsgCycleTime" BO_ 1263 1000;
BA_ "GenMsgCycleTime" BO_ 1265 1000;
BA_ "GenMsgCycleTime" BO_ 1266 1000;
BA_ "GenMsgCycleTime" BO_ 1268 1000;
BA_ "GenMsgCycleTime" BO_ 1269 1000;
BA_ "GenMsgCycleTime" BO_ 1272 1000;
BA_ "GenMsgCycleTime" BO_ 1254 1000;
BA_ "GenMsgCycleTime" BO_ 1257 1000;
BA_ "GenMsgCycleTime" BO_ 1258 1000;
BA_ "GenMsgCycleTime" BO_ 1415 1000;
BA_ "GenMsgCycleTime" BO_ 1063 1000;
BA_ "GenMsgCycleTime" BO_ 1435 1000;
BA_ "GenMsgCycleTime" BO_ 1356 1000;
BA_ "GenMsgCycleTime" BO_ 1060 1000;
BA_ "GenMsgCycleTime" BO_ 1419 1000;
BA_ "GenMsgCycleTime" BO_ 1374 1000;
BA_ "GenMsgCycleTime" BO_ 1108 1000;
BA_ "GenMsgCycleTime" BO_ 1116 1000;
BA_ "GenMsgCycleTime" BO_ 1422 1000;
BA_ "GenMsgCycleTime" BO_ 1117 1000;
BA_ "GenMsgCycleTime" BO_ 1109 1000;
BA_ "GenMsgCycleTime" BO_ 1118 1000;
BA_ "GenMsgCycleTime" BO_ 1119 1000;
BA_ "GenMsgCycleTime" BO_ 1120 1000;
BA_ "GenMsgCycleTime" BO_ 1054 1000;
BA_ "GenMsgCycleTime" BO_ 1121 1000;
BA_ "GenMsgCycleTime" BO_ 1411 1000;
BA_ "GenMsgCycleTime" BO_ 1122 1000;
BA_ "GenMsgCycleTime" BO_ 1123 1000;
BA_ "GenMsgCycleTime" BO_ 1065 1000;
BA_ "GenMsgCycleTime" BO_ 1072 1000;
BA_ "GenMsgCycleTime" BO_ 1262 1000;
BA_ "GenMsgCycleTime" BO_ 1124 1000;
BA_ "GenMsgCycleTime" BO_ 1126 1000;
BA_ "GenMsgCycleTime" BO_ 1127 1000;
BA_ "GenMsgCycleTime" BO_ 1128 1000;
BA_ "GenMsgCycleTime" BO_ 1428 1000;
BA_ "GenMsgCycleTime" BO_ 1412 1000;
BA_ "GenMsgCycleTime" BO_ 1129 1000;
BA_ "GenMsgCycleTime" BO_ 1131 1000;
BA_ "GenMsgCycleTime" BO_ 1292 1000;
BA_ "GenMsgCycleTime" BO_ 1293 1000;
BA_ "GenMsgCycleTime" BO_ 1132 1000;
BA_ "GenMsgCycleTime" BO_ 1133 1000;
BA_ "GenMsgCycleTime" BO_ 1135 1000;
BA_ "GenMsgCycleTime" BO_ 1134 1000;
BA_ "GenMsgCycleTime" BO_ 1406 1000;
BA_ "GenMsgCycleTime" BO_ 1286 1000;
BA_ "GenMsgCycleTime" BO_ 1287 1000;
BA_ "GenMsgCycleTime" BO_ 1304 1000;
BA_ "GenMsgCycleTime" BO_ 1349 1000;
BA_ "GenMsgCycleTime" BO_ 1307 1000;
BA_ "SignalType" SG_ 1470 PTOStndbySpdCstCurrSetVal "ENM";
BA_ "SignalLongName" SG_ 1470 PTOStndbySpdCstCurrSetVal "Power Take Off Standby Speed Customization Current Setting Value";
BA_ "SignalType" SG_ 1470 PTOEngRunTmrCstAvlFlg1 "ENM";
BA_ "SignalLongName" SG_ 1470 PTOEngRunTmrCstAvlFlg1 "Power Take Off Engine Run Timer Customization Availability Flag 1";
BA_ "SignalType" SG_ 1470 PTOEngSpdTypCstCurrSetVal "ENM";
BA_ "SignalLongName" SG_ 1470 PTOEngSpdTypCstCurrSetVal "Power Take Off Engine Speed Type Customization Current Setting Value";
BA_ "SignalType" SG_ 1470 PTOTpStpSpdCstCurrSetVal "ENM";
BA_ "SignalLongName" SG_ 1470 PTOTpStpSpdCstCurrSetVal "Power Take Off Tap Step Speed Customization Current Setting Value";
BA_ "SignalLongName" SG_ 1263 TrlrPlcrdPres "Trailer Placard Pressure";
BA_ "SignalType" SG_ 1263 TrlrProfDrvrReqdSeltn "ENM";
BA_ "SignalLongName" SG_ 1263 TrlrProfDrvrReqdSeltn "Trailer Profile Driver Requested Selection";
BA_ "SignalType" SG_ 1263 TrlrProfDeltn "ENM";
BA_ "SignalLongName" SG_ 1263 TrlrProfDeltn "Trailer Profile Deletion";
BA_ "SignalType" SG_ 1263 NumofAxls "ENM";
BA_ "SignalLongName" SG_ 1263 NumofAxls "Trailer Axle Count";
BA_ "SignalLongName" SG_ 1263 TrlrTireCnt "Trailer Tire Count";
BA_ "SignalLongName" SG_ 1265 ASTC_MtxSnkRmpTm "Amplifier Settings Tone Control : Mutex Sink Ramp Time";
BA_ "SignalLongName" SG_ 1265 ASTC_ChimSnkLvl "Amplifier Settings Tone Control : Chime Sink Level";
BA_ "SignalType" SG_ 1265 ASTC_ChimSnkSpkrPos "ENM";
BA_ "SignalLongName" SG_ 1265 ASTC_ChimSnkSpkrPos "Amplifier Settings Tone Control : Chime Sink Speaker Position";
BA_ "SignalType" SG_ 1265 ASTC_MtxSnkMut "ENM";
BA_ "SignalLongName" SG_ 1265 ASTC_MtxSnkMut "Amplifier Settings Tone Control : Mutex Sink Mute";
BA_ "SignalLongName" SG_ 1265 ASTC_SurndLvl "Amplifier Settings Tone Control : Surround Level";
BA_ "SignalType" SG_ 1265 ASTC_DSPMd "ENM";
BA_ "SignalLongName" SG_ 1265 ASTC_DSPMd "Amplifier Settings Tone Control : DSP Mode";
BA_ "SignalType" SG_ 1265 ASTC_AmpLwPwrSt "ENM";
BA_ "SignalLongName" SG_ 1265 ASTC_AmpLwPwrSt "Amplifier Settings Tone Control : Amplifier Low Power State";
BA_ "SignalLongName" SG_ 1265 ASTC_DrvrFrtTctlLvl "Amplifier Settings Tone Control : Driver Front Tactile Level";
BA_ "SignalLongName" SG_ 1265 ASTC_RRTctlLvl "Amplifier Settings Tone Control : Right RearTactile Level";
BA_ "SignalType" SG_ 1265 ASTC_VehNoisCmpnAct "ENM";
BA_ "SignalLongName" SG_ 1265 ASTC_VehNoisCmpnAct "Amplifier Settings Tone Control : Vehicle Noise Compensation Active";
BA_ "SignalLongName" SG_ 1265 ASTC_LRTctlLvl "Amplifier Settings Tone Control : Left RearTactile Level";
BA_ "SignalType" SG_ 1265 FrtCntrStckHptcFdbkReq "ENM";
BA_ "SignalLongName" SG_ 1265 FrtCntrStckHptcFdbkReq "Front Center Stack Haptic Feedback Request";
BA_ "SignalLongName" SG_ 1265 ASTC_PsngrFrtTctlLvl "Amplifier Settings Tone Control : Passenger Front Tactile Level";
BA_ "SignalType" SG_ 1265 ASTC_GblAudSnkMut "ENM";
BA_ "SignalLongName" SG_ 1265 ASTC_GblAudSnkMut "Amplifier Settings Tone Control : Global Audio Sink Mute";
BA_ "SignalLongName" SG_ 1266 ZALC_LRMtxSnkRmpTm "Zone Audio Level Control : Left Rear Mutex Sink Ramp Time";
BA_ "SignalType" SG_ 1266 ZALC_LRMtxSnkMut "ENM";
BA_ "SignalLongName" SG_ 1266 ZALC_LRMtxSnkMut "Zone Audio Level Control : Left Rear Mutex Sink Mute";
BA_ "SignalType" SG_ 1266 ZALC_PsngrFrtMtxSnkMut "ENM";
BA_ "SignalLongName" SG_ 1266 ZALC_PsngrFrtMtxSnkMut "Zone Audio Level Control : Passenger Front Mutex Sink Mute";
BA_ "SignalType" SG_ 1266 ZALC_MltZnMixPrmtAudRR "ENM";
BA_ "SignalLongName" SG_ 1266 ZALC_MltZnMixPrmtAudRR "Zone Audio Level Control : Multi-Zone Mix Prompt Audio Right Rear";
BA_ "SignalLongName" SG_ 1266 ZALC_PsngrFrtMtxSnkLvl "Zone Audio Level Control : Passenger Front Mutex Sink Level";
BA_ "SignalLongName" SG_ 1266 ZALC_RRMtxSnkLvl "Zone Audio Level Control : Right Rear Mutex Sink Level";
BA_ "SignalType" SG_ 1266 ZALC_RRMtxSnkMut "ENM";
BA_ "SignalLongName" SG_ 1266 ZALC_RRMtxSnkMut "Zone Audio Level Control : Right Rear Mutex Sink Mute";
BA_ "SignalType" SG_ 1266 ZALC_MltZnAudFtrStat "ENM";
BA_ "SignalLongName" SG_ 1266 ZALC_MltZnAudFtrStat "Zone Audio Level Control : Multi-Zone Audio Feature State";
BA_ "SignalLongName" SG_ 1266 ZALC_RRMtxSnkRmpTm "Zone Audio Level Control : Right Rear Mutex Sink Ramp Time";
BA_ "SignalLongName" SG_ 1266 ZALC_PsngrFrtMtxSnkRmpTm "Zone Audio Level Control : Passenger Front Mutex Sink Ramp Time";
BA_ "SignalType" SG_ 1266 ZALC_VcSrcActvOnRRMtx "ENM";
BA_ "SignalLongName" SG_ 1266 ZALC_VcSrcActvOnRRMtx "Zone Audio Level Control : Voice Source Active On Right Rear Mutex";
BA_ "SignalLongName" SG_ 1266 ZALC_LRMtxSnkLvl "Zone Audio Level Control : Left Rear Mutex Sink Level";
BA_ "SignalType" SG_ 1266 ZALC_MltZnMixPrmtAudDrvrFrt "ENM";
BA_ "SignalLongName" SG_ 1266 ZALC_MltZnMixPrmtAudDrvrFrt "Zone Audio Level Control : Multi-Zone Mix Prompt Audio Driver Front";
BA_ "SignalType" SG_ 1266 ZALC_VcSrcActvOnPsngrFrtMtx "ENM";
BA_ "SignalLongName" SG_ 1266 ZALC_VcSrcActvOnPsngrFrtMtx "Zone Audio Level Control : Voice Source Active On Passenger Front Mutex";
BA_ "SignalType" SG_ 1266 FrtCntrStckOptDskDrvDckStat "ENM";
BA_ "SignalLongName" SG_ 1266 FrtCntrStckOptDskDrvDckStat "Front Center Stack Optical Disk Drive Deck State";
BA_ "SignalType" SG_ 1266 ZALC_MltZnMixPrmtAudLR "ENM";
BA_ "SignalLongName" SG_ 1266 ZALC_MltZnMixPrmtAudLR "Zone Audio Level Control : Multi-Zone Mix Prompt Audio Left Rear";
BA_ "SignalType" SG_ 1266 ZALC_MltZnMixPrmtAudPsngrFrt "ENM";
BA_ "SignalLongName" SG_ 1266 ZALC_MltZnMixPrmtAudPsngrFrt "Zone Audio Level Control : Multi-Zone Mix Prompt Audio Passenger Front";
BA_ "SignalType" SG_ 1266 ZALC_VcSrcActvOnLRMtx "ENM";
BA_ "SignalLongName" SG_ 1266 ZALC_VcSrcActvOnLRMtx "Zone Audio Level Control : Voice Source Active On Left Rear Mutex";
BA_ "SignalLongName" SG_ 1268 TrlrTirePresLFXferdSnsrID "Trailer Tire Pressure Left Front Transferred Sensor ID";
BA_ "SignalType" SG_ 1268 TrlrTirePresSnsrIDLrnReqd "ENM";
BA_ "SignalLongName" SG_ 1268 TrlrTirePresSnsrIDLrnReqd "Trailer Tire Pressure Sensor ID Learn Requested";
BA_ "SignalType" SG_ 1268 TrlrThftAlrtEnbld "ENM";
BA_ "SignalLongName" SG_ 1268 TrlrThftAlrtEnbld "Trailer Theft Alert Enabled";
BA_ "SignalType" SG_ 1268 TrlrLghtAlrtEnbld "ENM";
BA_ "SignalLongName" SG_ 1268 TrlrLghtAlrtEnbld "Trailer Light Alerts Enabled";
BA_ "SignalLongName" SG_ 1268 DAPR_CtlDist "Directional Audio Prompt Rendering : Control Distance";
BA_ "SignalType" SG_ 1268 DAPR_CtlDir "ENM";
BA_ "SignalLongName" SG_ 1268 DAPR_CtlDir "Directional Audio Prompt Rendering : Control Direction";
BA_ "SignalType" SG_ 1268 TrlrTirePresProfXferd "ENM";
BA_ "SignalLongName" SG_ 1268 TrlrTirePresProfXferd "Trailer Tire Pressure Profile Transferred";
BA_ "SignalType" SG_ 1268 DAPR_CurrPrmt "ENM";
BA_ "SignalLongName" SG_ 1268 DAPR_CurrPrmt "Directional Audio Prompt Rendering : Current Prompt";
BA_ "SignalType" SG_ 1268 DAPR_CtlZn "ENM";
BA_ "SignalLongName" SG_ 1268 DAPR_CtlZn "Directional Audio Prompt Rendering : Control Zone";
BA_ "SignalLongName" SG_ 1268 LtSdFrtZnAudVolCtlOfst "Left Side Front Zone Audio Volume Control Offset";
BA_ "SignalType" SG_ 1269 LVMAVC_RmtSpchRcgnID "ENM";
BA_ "SignalLongName" SG_ 1269 LVMAVC_RmtSpchRcgnID "Low Volume Module Audio Video Command : Remote Speech Recognition ID";
BA_ "SignalType" SG_ 1269 LVMAVC_PrmtAudResp "ENM";
BA_ "SignalLongName" SG_ 1269 LVMAVC_PrmtAudResp "Low Volume Module Audio Video Command : Prompt Audio Response";
BA_ "SignalType" SG_ 1269 LVMAVC_RmtSpchRcgnActn "ENM";
BA_ "SignalLongName" SG_ 1269 LVMAVC_RmtSpchRcgnActn "Low Volume Module Audio Video Command : Remote Speech Recognition Action";
BA_ "SignalType" SG_ 1269 LVMAVC_ApplID "ENM";
BA_ "SignalLongName" SG_ 1269 LVMAVC_ApplID "Low Volume Module Audio Video Command : LVM Application ID";
BA_ "SignalType" SG_ 1269 LVMAVC_StreoAudResp "ENM";
BA_ "SignalLongName" SG_ 1269 LVMAVC_StreoAudResp "Low Volume Module Audio Video Command : Stereo Audio Response";
BA_ "SignalType" SG_ 1269 LVMAVC_RmtEnbl "ENM";
BA_ "SignalLongName" SG_ 1269 LVMAVC_RmtEnbl "Low Volume Module Audio Video Command : Remote Enable";
BA_ "SignalType" SG_ 1269 LVMAVC_SpchRcgnAval "ENM";
BA_ "SignalLongName" SG_ 1269 LVMAVC_SpchRcgnAval "Low Volume Module Audio Video Command : Speech Recognition Available";
BA_ "SignalLongName" SG_ 1269 TrlrLgth "Trailer Length";
BA_ "SignalLongName" SG_ 1269 TrlrHght "Trailer Height";
BA_ "SignalLongName" SG_ 1269 TrlrWdth "Trailer Width";
BA_ "SignalType" SG_ 1269 TrlrStatTowHaulModeOvrrd "ENM";
BA_ "SignalLongName" SG_ 1269 TrlrStatTowHaulModeOvrrd "Trailer State Tow Haul Mode Override";
BA_ "SignalType" SG_ 1269 TrlrLtngSeqReq "ENM";
BA_ "SignalLongName" SG_ 1269 TrlrLtngSeqReq "Trailer Lighting Sequence Request";
BA_ "SignalType" SG_ 1269 TrlrHtchTyp "ENM";
BA_ "SignalLongName" SG_ 1269 TrlrHtchTyp "Trailer Hitch Type";
BA_ "SignalType" SG_ 1269 FrtCntrStckVidInSel "ENM";
BA_ "SignalLongName" SG_ 1269 FrtCntrStckVidInSel "Front Center Stack Video Input Select";
BA_ "SignalType" SG_ 1269 TrlrAppInvsblTrlrPrvwReqd "ENM";
BA_ "SignalLongName" SG_ 1269 TrlrAppInvsblTrlrPrvwReqd "Trailering App Invisible Trailer Preview Requested";
BA_ "SignalType" SG_ 1269 TrlrAppAux2CamPrvwReqd "ENM";
BA_ "SignalLongName" SG_ 1269 TrlrAppAux2CamPrvwReqd "Trailering App Aux 2 Camera Preview Requested";
BA_ "SignalType" SG_ 1269 TrlrAppAux1CamPrvwReqd "ENM";
BA_ "SignalLongName" SG_ 1269 TrlrAppAux1CamPrvwReqd "Trailering App Aux 1 Camera Preview Requested";
BA_ "SignalType" SG_ 1269 TrlRvsLghtFldEnbld "ENM";
BA_ "SignalLongName" SG_ 1269 TrlRvsLghtFldEnbld "Trailer Reverse Light Failed Enabled";
BA_ "SignalType" SG_ 1269 FrtCntrStckTchCtlrRstCmd "ENM";
BA_ "SignalLongName" SG_ 1269 FrtCntrStckTchCtlrRstCmd "Front Center Stack Touch Controller Reset Command";
BA_ "SignalType" SG_ 1269 Frt360CamSwAct "ENM";
BA_ "SignalLongName" SG_ 1269 Frt360CamSwAct "Front 360 Camera Switch Active";
BA_ "SignalType" SG_ 1269 TrlrTyp "ENM";
BA_ "SignalLongName" SG_ 1269 TrlrTyp "Trailer Type";
BA_ "SignalLongName" SG_ 1272 VwgBowlVwAngSeltn "Viewing Bowl View Angle Selection";
BA_ "SignalType" SG_ 1272 TrgdVidRecSwAct "ENM";
BA_ "SignalLongName" SG_ 1272 TrgdVidRecSwAct "Triggered Video Recorder Switch Active";
BA_ "SignalType" SG_ 1272 SrrndVsnRcrdrListFcs "ENM";
BA_ "SignalLongName" SG_ 1272 SrrndVsnRcrdrListFcs "Surround Vision Recorder List Focus";
BA_ "SignalType" SG_ 1272 VwgVwprtSeltn "ENM";
BA_ "SignalLongName" SG_ 1272 VwgVwprtSeltn "Viewing Viewport Selection";
BA_ "SignalType" SG_ 1272 PFASndSeltnCstChgSetReq "ENM";
BA_ "SignalLongName" SG_ 1272 PFASndSeltnCstChgSetReq "Pedestrian Friendly Alert Sound Selection Customization Change Setting Request";
BA_ "SignalType" SG_ 1272 SrrndVsnRcrdrVwprtSeltn "ENM";
BA_ "SignalLongName" SG_ 1272 SrrndVsnRcrdrVwprtSeltn "Surround Vision Recorder Viewport Selection";
BA_ "SignalType" SG_ 1272 SrrndVsnRcrdrFileSeltn "ENM";
BA_ "SignalLongName" SG_ 1272 SrrndVsnRcrdrFileSeltn "Surround Vision Recorder File Selection";
BA_ "SignalType" SG_ 1272 SrrndVsnRcrdrFileDeltn "ENM";
BA_ "SignalLongName" SG_ 1272 SrrndVsnRcrdrFileDeltn "Surround Vision Recorder File Deletion";
BA_ "SignalType" SG_ 1272 VGS_DynActv "ENM";
BA_ "SignalLongName" SG_ 1272 VGS_DynActv "Viewing Guideline Selection : Viewing Guideline Selection: Dynamic Active";
BA_ "SignalType" SG_ 1272 VGS_CurbVwActv "ENM";
BA_ "SignalLongName" SG_ 1272 VGS_CurbVwActv "Viewing Guideline Selection : Viewing Guideline Selection: Curb View Active";
BA_ "SignalType" SG_ 1272 SrrndVsnRcrdrPlybkSeltn "ENM";
BA_ "SignalLongName" SG_ 1272 SrrndVsnRcrdrPlybkSeltn "Surround Vision Recorder Playback Selection";
BA_ "SignalType" SG_ 1272 SrrndVsnRcrdrPlybkFcs "ENM";
BA_ "SignalLongName" SG_ 1272 SrrndVsnRcrdrPlybkFcs "Surround Vision Recorder Playback Focus";
BA_ "SignalType" SG_ 1272 SrrndVsnRcrdrSaveFile "ENM";
BA_ "SignalLongName" SG_ 1272 SrrndVsnRcrdrSaveFile "Surround Vision Recorder Save File";
BA_ "SignalType" SG_ 1272 SrrndVsnRcrdrRcrdSeltn "ENM";
BA_ "SignalLongName" SG_ 1272 SrrndVsnRcrdrRcrdSeltn "Surround Vision Recorder Record Selection";
BA_ "SignalType" SG_ 1272 SrrndVsnRcrdrListPgSeltn "ENM";
BA_ "SignalLongName" SG_ 1272 SrrndVsnRcrdrListPgSeltn "Surround Vision Recorder List Page Selection";
BA_ "SignalType" SG_ 1272 VGS_TrlrActv "ENM";
BA_ "SignalLongName" SG_ 1272 VGS_TrlrActv "Viewing Guideline Selection : Viewing Guideline Selection: Trailer Active";
BA_ "SignalLongName" SG_ 1254 TrlrTirePresLRXferdSnsrID "Trailer Tire Pressure Left Rear Transferred Sensor ID";
BA_ "SignalLongName" SG_ 1254 TrlrTirePresLtMdlXferdSnsrID "Trailer Tire Pressure Left Middle Transferred Sensor ID";
BA_ "SignalLongName" SG_ 1257 TrlrTirePresRFXferdSnsrID "Trailer Tire Pressure Right Front Transferred Sensor ID";
BA_ "SignalLongName" SG_ 1257 TrlrTirePresRRXferdSnsrID "Trailer Tire Pressure Right Rear Transferred Sensor ID";
BA_ "SignalLongName" SG_ 1258 TrlrTirePresRtMdlXferdSnsrID "Trailer Tire Pressure Right Middle Transferred Sensor ID";
BA_ "SignalType" SG_ 1258 HMIInCarVcCommCtl "ENM";
BA_ "SignalLongName" SG_ 1258 HMIInCarVcCommCtl "HMI In Car Voice Communication Control";
BA_ "SignalLongName" SG_ 1258 RtSdFrtZnAudVolCtlOfst "Right Side Front Zone Audio Volume Control Offset";
BA_ "SignalType" SG_ 1258 AutoLnChgCstChgSetReq "ENM";
BA_ "SignalLongName" SG_ 1258 AutoLnChgCstChgSetReq "Automatic Lane Change Customization Change Setting Request";
BA_ "SignalType" SG_ 1258 DrvrSeltdTrlrPrsnt "ENM";
BA_ "SignalLongName" SG_ 1258 DrvrSeltdTrlrPrsnt "Driver Selected Trailer Present";
BA_ "SignalType" SG_ 1258 VcRcgnSesnActv "ENM";
BA_ "SignalLongName" SG_ 1258 VcRcgnSesnActv "Voice Recognition Session Active";
BA_ "SignalType" SG_ 1258 HndsFrVcCallActv "ENM";
BA_ "SignalLongName" SG_ 1258 HndsFrVcCallActv "Hands Free Voice Call Active";
BA_ "SignalType" SG_ 1258 FrtZnAudVolSyncCtlOn "ENM";
BA_ "SignalLongName" SG_ 1258 FrtZnAudVolSyncCtlOn "Front Zone Audio Volume Sync Control On";
BA_ "SignalType" SG_ 1258 DirAudPrmtRndrngEnbld "ENM";
BA_ "SignalLongName" SG_ 1258 DirAudPrmtRndrngEnbld "Directional Audio Prompt Rendering Enabled";
BA_ "SignalLongName" SG_ 1415 HtchPtLgthExtd "Hitching Point Length Extended";
BA_ "SignalLongName" SG_ 1415 TrlrTngeLgth "Trailer Tongue Length";
BA_ "SignalLongName" SG_ 1415 VehHtchHght "Vehicle Hitch Height";
BA_ "SignalLongName" SG_ 1415 VehHtchLgth "Vehicle Hitch Length";
BA_ "SignalLongName" SG_ 1415 TrlrFllHtchPtLgth "Trailer Full Hitching Point Length";
BA_ "SignalLongName" SG_ 1415 TrlrToCabLgth "Trailer to Cab Length";
BA_ "SignalType" SG_ 1063 PASftBtnSeltdStatRw "ENM";
BA_ "SignalLongName" SG_ 1063 PASftBtnSeltdStatRw "Park Assist Soft Button Selected State Raw";
BA_ "SignalType" SG_ 1063 APASftBtnSeltdStatRw "ENM";
BA_ "SignalLongName" SG_ 1063 APASftBtnSeltdStatRw "Advanced Park Assist Soft Button Selected State Raw";
BA_ "SignalLongName" SG_ 1435 VehBedHtchToCabLgth "Vehicle Bed Hitch to Cab Length";
BA_ "SignalType" SG_ 552 WCM_LCMDataMsgStat "ENM";
BA_ "SignalLongName" SG_ 552 WCM_LCMDataMsgStat "Wireless Charger Module - License Compliance Material Data Message Status";
BA_ "SignalType" SG_ 552 WCM_LCMFileTrans "ENM";
BA_ "SignalLongName" SG_ 552 WCM_LCMFileTrans "Wireless Charger Module - License Compliance Material File Transfer";
BA_ "SignalType" SG_ 1356 PwrRrClsrCstChgSetReq "ENM";
BA_ "SignalLongName" SG_ 1356 PwrRrClsrCstChgSetReq "Power Rear Closure Customization Change Setting Request";
BA_ "SignalLongName" SG_ 1060 OATDispdVal "Outside Air Temperature Displayed Value";
BA_ "SignalType" SG_ 1060 OATDispdVal_DuD "ENM";
BA_ "SignalLongName" SG_ 1060 OATDispdVal_DuD "Outside Air Temperature Displayed Value Don't Use Data";
BA_ "SignalType" SG_ 1060 PTOSet1SpdCstSetReq "ENM";
BA_ "SignalLongName" SG_ 1060 PTOSet1SpdCstSetReq "Power Take Off Set 1 Speed Customization Setting Request";
BA_ "SignalType" SG_ 1060 PTOEngRunTmrCstSetReq "ENM";
BA_ "SignalLongName" SG_ 1060 PTOEngRunTmrCstSetReq "Power Take Off Engine Run Timer Customization Setting Request";
BA_ "SignalType" SG_ 1060 PTOStndbySpdCstSetReq "ENM";
BA_ "SignalLongName" SG_ 1060 PTOStndbySpdCstSetReq "Power Take Off Standby Speed Customization Setting Request";
BA_ "SignalType" SG_ 1060 PTOSet2SpdCstSetReq "ENM";
BA_ "SignalLongName" SG_ 1060 PTOSet2SpdCstSetReq "Power Take Off Set 2 Speed Customization Setting Request";
BA_ "SignalType" SG_ 1060 PTOModeCstSetReq "ENM";
BA_ "SignalLongName" SG_ 1060 PTOModeCstSetReq "Power Take Off Mode Customization Setting Request";
BA_ "SignalType" SG_ 1060 PTOEngSpdTypCstSetReq "ENM";
BA_ "SignalLongName" SG_ 1060 PTOEngSpdTypCstSetReq "Power Take Off Engine Speed Type Customization Setting Request";
BA_ "SignalType" SG_ 1060 PTOTpStpSpdCstSetReq "ENM";
BA_ "SignalLongName" SG_ 1060 PTOTpStpSpdCstSetReq "Power Take Off Tap Step Speed Customization Setting Request";
BA_ "SignalLongName" SG_ 1419 TrlrBoxWdth "Trailer Box Width";
BA_ "SignalType" SG_ 1419 AutoTrnspHdActvnCstChgSetReq "ENM";
BA_ "SignalLongName" SG_ 1419 AutoTrnspHdActvnCstChgSetReq "Automatic Transparent Hood Activation Customization Change Setting Request";
BA_ "SignalLongName" SG_ 1419 TrlrFaceDpth "Trailer Face Depth";
BA_ "SignalLongName" SG_ 1419 TrlrFrwdSdEdgeHght "Trailer Forward Side Edge Height";
BA_ "SignalLongName" SG_ 1419 TrlrFrtBtmCrnrHght "Trailer Front Bottom Corner Height";
BA_ "SignalLongName" SG_ 1374 CRI_ChmPrdcrReq "Chime Request Information : Chime Producer Request";
BA_ "SignalLongName" SG_ 1374 CRI_CS "Chime Request Information : Checksum";
BA_ "SignalLongName" SG_ 1374 CRI_ARC "Chime Request Information : Alive Rolling Count";
BA_ "SignalLongName" SG_ 1108 DTCI_AGC_DTCFailType "Diagnostic Trouble Code Information Extended - AGC : Diagnostic Trouble Code Failure Type";
BA_ "SignalType" SG_ 1108 DTCI_AGC_CnfrmdDTC "ENM";
BA_ "SignalLongName" SG_ 1108 DTCI_AGC_CnfrmdDTC "Diagnostic Trouble Code Information Extended - AGC : Confirmed DTC";
BA_ "SignalType" SG_ 1108 DTCI_AGC_DTCFaultType "ENM";
BA_ "SignalLongName" SG_ 1108 DTCI_AGC_DTCFaultType "Diagnostic Trouble Code Information Extended - AGC : Diagnostic Trouble Code Fault Type";
BA_ "SignalLongName" SG_ 1108 DTCI_AGC_DTCNumber "Diagnostic Trouble Code Information Extended - AGC : Diagnostic Trouble Code Number";
BA_ "SignalLongName" SG_ 1108 DTCI_AGC_DTCSource "Diagnostic Trouble Code Information Extended - AGC : Diagnostic Trouble Code Source";
BA_ "SignalType" SG_ 1108 DTCI_AGC_TstNCmpltdOpCyc "ENM";
BA_ "SignalLongName" SG_ 1108 DTCI_AGC_TstNCmpltdOpCyc "Diagnostic Trouble Code Information Extended - AGC : Test Not Completed This Operation Cycle";
BA_ "SignalType" SG_ 1108 DTCI_AGC_TstNCmpltdLstClr "ENM";
BA_ "SignalLongName" SG_ 1108 DTCI_AGC_TstNCmpltdLstClr "Diagnostic Trouble Code Information Extended - AGC : Test Not Completed Since Last Clear";
BA_ "SignalType" SG_ 1108 DTCI_AGC_TstFldOpCyc "ENM";
BA_ "SignalLongName" SG_ 1108 DTCI_AGC_TstFldOpCyc "Diagnostic Trouble Code Information Extended - AGC : Test Failed This Operation Cycle";
BA_ "SignalType" SG_ 1108 DTCI_AGC_TstFldLstClr "ENM";
BA_ "SignalLongName" SG_ 1108 DTCI_AGC_TstFldLstClr "Diagnostic Trouble Code Information Extended - AGC : Test Failed Since Last Clear";
BA_ "SignalType" SG_ 1108 DTCI_AGC_TstFld "ENM";
BA_ "SignalLongName" SG_ 1108 DTCI_AGC_TstFld "Diagnostic Trouble Code Information Extended - AGC : Test Failed";
BA_ "SignalType" SG_ 1108 DTCI_AGC_PndngDTC "ENM";
BA_ "SignalLongName" SG_ 1108 DTCI_AGC_PndngDTC "Diagnostic Trouble Code Information Extended - AGC : Pending DTC";
BA_ "SignalType" SG_ 1108 DTCI_AGC_DTCTriggered "ENM";
BA_ "SignalLongName" SG_ 1108 DTCI_AGC_DTCTriggered "Diagnostic Trouble Code Information Extended - AGC : Diagnostic Trouble Code Triggered";
BA_ "SignalType" SG_ 1108 DTCI_AGC_WrnIndTrggrd "ENM";
BA_ "SignalLongName" SG_ 1108 DTCI_AGC_WrnIndTrggrd "Diagnostic Trouble Code Information Extended - AGC : Warning Indicator Triggered";
BA_ "SignalType" SG_ 1108 DTCI_AGC_WrnIndRqd "ENM";
BA_ "SignalLongName" SG_ 1108 DTCI_AGC_WrnIndRqd "Diagnostic Trouble Code Information Extended - AGC : Warning Indicator Requested";
BA_ "SignalLongName" SG_ 1116 DTCI_AHL_AFL_DTCFailType "Diagnostic Trouble Code Information Extended - AHL_AFL : Diagnostic Trouble Code Failure Type";
BA_ "SignalType" SG_ 1116 DTCI_AHL_AFL_CnfrmdDTC "ENM";
BA_ "SignalLongName" SG_ 1116 DTCI_AHL_AFL_CnfrmdDTC "Diagnostic Trouble Code Information Extended - AHL_AFL : Confirmed DTC";
BA_ "SignalType" SG_ 1116 DTCI_AHL_AFL_DTCFaultType "ENM";
BA_ "SignalLongName" SG_ 1116 DTCI_AHL_AFL_DTCFaultType "Diagnostic Trouble Code Information Extended - AHL_AFL : Diagnostic Trouble Code Fault Type";
BA_ "SignalLongName" SG_ 1116 DTCI_AHL_AFL_DTCNumber "Diagnostic Trouble Code Information Extended - AHL_AFL : Diagnostic Trouble Code Number";
BA_ "SignalLongName" SG_ 1116 DTCI_AHL_AFL_DTCSource "Diagnostic Trouble Code Information Extended - AHL_AFL : Diagnostic Trouble Code Source";
BA_ "SignalType" SG_ 1116 DTCI_AHL_AFL_TstNCmpltdOpCyc "ENM";
BA_ "SignalLongName" SG_ 1116 DTCI_AHL_AFL_TstNCmpltdOpCyc "Diagnostic Trouble Code Information Extended - AHL_AFL : Test Not Completed This Operation Cycle";
BA_ "SignalType" SG_ 1116 DTCI_AHL_AFL_TstNCmpltdLstClr "ENM";
BA_ "SignalLongName" SG_ 1116 DTCI_AHL_AFL_TstNCmpltdLstClr "Diagnostic Trouble Code Information Extended - AHL_AFL : Test Not Completed Since Last Clear";
BA_ "SignalType" SG_ 1116 DTCI_AHL_AFL_TstFldOpCyc "ENM";
BA_ "SignalLongName" SG_ 1116 DTCI_AHL_AFL_TstFldOpCyc "Diagnostic Trouble Code Information Extended - AHL_AFL : Test Failed This Operation Cycle";
BA_ "SignalType" SG_ 1116 DTCI_AHL_AFL_TstFldLstClr "ENM";
BA_ "SignalLongName" SG_ 1116 DTCI_AHL_AFL_TstFldLstClr "Diagnostic Trouble Code Information Extended - AHL_AFL : Test Failed Since Last Clear";
BA_ "SignalType" SG_ 1116 DTCI_AHL_AFL_TstFld "ENM";
BA_ "SignalLongName" SG_ 1116 DTCI_AHL_AFL_TstFld "Diagnostic Trouble Code Information Extended - AHL_AFL : Test Failed";
BA_ "SignalType" SG_ 1116 DTCI_AHL_AFL_PndngDTC "ENM";
BA_ "SignalLongName" SG_ 1116 DTCI_AHL_AFL_PndngDTC "Diagnostic Trouble Code Information Extended - AHL_AFL : Pending DTC";
BA_ "SignalType" SG_ 1116 DTCI_AHL_AFL_DTCTriggered "ENM";
BA_ "SignalLongName" SG_ 1116 DTCI_AHL_AFL_DTCTriggered "Diagnostic Trouble Code Information Extended - AHL_AFL : Diagnostic Trouble Code Triggered";
BA_ "SignalType" SG_ 1116 DTCI_AHL_AFL_WrnIndTrggrd "ENM";
BA_ "SignalLongName" SG_ 1116 DTCI_AHL_AFL_WrnIndTrggrd "Diagnostic Trouble Code Information Extended - AHL_AFL : Warning Indicator Triggered";
BA_ "SignalType" SG_ 1116 DTCI_AHL_AFL_WrnIndRqd "ENM";
BA_ "SignalLongName" SG_ 1116 DTCI_AHL_AFL_WrnIndRqd "Diagnostic Trouble Code Information Extended - AHL_AFL : Warning Indicator Requested";
BA_ "SignalLongName" SG_ 1422 DTCI_AHS_DTCFailType "Diagnostic Trouble Code Information Extended - AHS : Diagnostic Trouble Code Failure Type";
BA_ "SignalType" SG_ 1422 DTCI_AHS_CnfrmdDTC "ENM";
BA_ "SignalLongName" SG_ 1422 DTCI_AHS_CnfrmdDTC "Diagnostic Trouble Code Information Extended - AHS : Confirmed DTC";
BA_ "SignalType" SG_ 1422 DTCI_AHS_DTCFaultType "ENM";
BA_ "SignalLongName" SG_ 1422 DTCI_AHS_DTCFaultType "Diagnostic Trouble Code Information Extended - AHS : Diagnostic Trouble Code Fault Type";
BA_ "SignalLongName" SG_ 1422 DTCI_AHS_DTCNumber "Diagnostic Trouble Code Information Extended - AHS : Diagnostic Trouble Code Number";
BA_ "SignalLongName" SG_ 1422 DTCI_AHS_DTCSource "Diagnostic Trouble Code Information Extended - AHS : Diagnostic Trouble Code Source";
BA_ "SignalType" SG_ 1422 DTCI_AHS_TstNCmpltdOpCyc "ENM";
BA_ "SignalLongName" SG_ 1422 DTCI_AHS_TstNCmpltdOpCyc "Diagnostic Trouble Code Information Extended - AHS : Test Not Completed This Operation Cycle";
BA_ "SignalType" SG_ 1422 DTCI_AHS_TstNCmpltdLstClr "ENM";
BA_ "SignalLongName" SG_ 1422 DTCI_AHS_TstNCmpltdLstClr "Diagnostic Trouble Code Information Extended - AHS : Test Not Completed Since Last Clear";
BA_ "SignalType" SG_ 1422 DTCI_AHS_TstFldOpCyc "ENM";
BA_ "SignalLongName" SG_ 1422 DTCI_AHS_TstFldOpCyc "Diagnostic Trouble Code Information Extended - AHS : Test Failed This Operation Cycle";
BA_ "SignalType" SG_ 1422 DTCI_AHS_TstFldLstClr "ENM";
BA_ "SignalLongName" SG_ 1422 DTCI_AHS_TstFldLstClr "Diagnostic Trouble Code Information Extended - AHS : Test Failed Since Last Clear";
BA_ "SignalType" SG_ 1422 DTCI_AHS_TstFld "ENM";
BA_ "SignalLongName" SG_ 1422 DTCI_AHS_TstFld "Diagnostic Trouble Code Information Extended - AHS : Test Failed";
BA_ "SignalType" SG_ 1422 DTCI_AHS_PndngDTC "ENM";
BA_ "SignalLongName" SG_ 1422 DTCI_AHS_PndngDTC "Diagnostic Trouble Code Information Extended - AHS : Pending DTC";
BA_ "SignalType" SG_ 1422 DTCI_AHS_DTCTriggered "ENM";
BA_ "SignalLongName" SG_ 1422 DTCI_AHS_DTCTriggered "Diagnostic Trouble Code Information Extended - AHS : Diagnostic Trouble Code Triggered";
BA_ "SignalType" SG_ 1422 DTCI_AHS_WrnIndTrggrd "ENM";
BA_ "SignalLongName" SG_ 1422 DTCI_AHS_WrnIndTrggrd "Diagnostic Trouble Code Information Extended - AHS : Warning Indicator Triggered";
BA_ "SignalType" SG_ 1422 DTCI_AHS_WrnIndRqd "ENM";
BA_ "SignalLongName" SG_ 1422 DTCI_AHS_WrnIndRqd "Diagnostic Trouble Code Information Extended - AHS : Warning Indicator Requested";
BA_ "SignalLongName" SG_ 1117 DTCI_ALC_DTCFailType "Diagnostic Trouble Code Information Extended - ALC : Diagnostic Trouble Code Failure Type";
BA_ "SignalType" SG_ 1117 DTCI_ALC_CnfrmdDTC "ENM";
BA_ "SignalLongName" SG_ 1117 DTCI_ALC_CnfrmdDTC "Diagnostic Trouble Code Information Extended - ALC : Confirmed DTC";
BA_ "SignalType" SG_ 1117 DTCI_ALC_DTCFaultType "ENM";
BA_ "SignalLongName" SG_ 1117 DTCI_ALC_DTCFaultType "Diagnostic Trouble Code Information Extended - ALC : Diagnostic Trouble Code Fault Type";
BA_ "SignalLongName" SG_ 1117 DTCI_ALC_DTCNumber "Diagnostic Trouble Code Information Extended - ALC : Diagnostic Trouble Code Number";
BA_ "SignalLongName" SG_ 1117 DTCI_ALC_DTCSource "Diagnostic Trouble Code Information Extended - ALC : Diagnostic Trouble Code Source";
BA_ "SignalType" SG_ 1117 DTCI_ALC_TstNCmpltdOpCyc "ENM";
BA_ "SignalLongName" SG_ 1117 DTCI_ALC_TstNCmpltdOpCyc "Diagnostic Trouble Code Information Extended - ALC : Test Not Completed This Operation Cycle";
BA_ "SignalType" SG_ 1117 DTCI_ALC_TstNCmpltdLstClr "ENM";
BA_ "SignalLongName" SG_ 1117 DTCI_ALC_TstNCmpltdLstClr "Diagnostic Trouble Code Information Extended - ALC : Test Not Completed Since Last Clear";
BA_ "SignalType" SG_ 1117 DTCI_ALC_TstFldOpCyc "ENM";
BA_ "SignalLongName" SG_ 1117 DTCI_ALC_TstFldOpCyc "Diagnostic Trouble Code Information Extended - ALC : Test Failed This Operation Cycle";
BA_ "SignalType" SG_ 1117 DTCI_ALC_TstFldLstClr "ENM";
BA_ "SignalLongName" SG_ 1117 DTCI_ALC_TstFldLstClr "Diagnostic Trouble Code Information Extended - ALC : Test Failed Since Last Clear";
BA_ "SignalType" SG_ 1117 DTCI_ALC_TstFld "ENM";
BA_ "SignalLongName" SG_ 1117 DTCI_ALC_TstFld "Diagnostic Trouble Code Information Extended - ALC : Test Failed";
BA_ "SignalType" SG_ 1117 DTCI_ALC_PndngDTC "ENM";
BA_ "SignalLongName" SG_ 1117 DTCI_ALC_PndngDTC "Diagnostic Trouble Code Information Extended - ALC : Pending DTC";
BA_ "SignalType" SG_ 1117 DTCI_ALC_DTCTriggered "ENM";
BA_ "SignalLongName" SG_ 1117 DTCI_ALC_DTCTriggered "Diagnostic Trouble Code Information Extended - ALC : Diagnostic Trouble Code Triggered";
BA_ "SignalType" SG_ 1117 DTCI_ALC_WrnIndTrggrd "ENM";
BA_ "SignalLongName" SG_ 1117 DTCI_ALC_WrnIndTrggrd "Diagnostic Trouble Code Information Extended - ALC : Warning Indicator Triggered";
BA_ "SignalType" SG_ 1117 DTCI_ALC_WrnIndRqd "ENM";
BA_ "SignalLongName" SG_ 1117 DTCI_ALC_WrnIndRqd "Diagnostic Trouble Code Information Extended - ALC : Warning Indicator Requested";
BA_ "SignalLongName" SG_ 1109 DTCI_AMP_DTCFailType "Diagnostic Trouble Code Information Extended - AMP : Diagnostic Trouble Code Failure Type";
BA_ "SignalType" SG_ 1109 DTCI_AMP_CnfrmdDTC "ENM";
BA_ "SignalLongName" SG_ 1109 DTCI_AMP_CnfrmdDTC "Diagnostic Trouble Code Information Extended - AMP : Confirmed DTC";
BA_ "SignalType" SG_ 1109 DTCI_AMP_DTCFaultType "ENM";
BA_ "SignalLongName" SG_ 1109 DTCI_AMP_DTCFaultType "Diagnostic Trouble Code Information Extended - AMP : Diagnostic Trouble Code Fault Type";
BA_ "SignalLongName" SG_ 1109 DTCI_AMP_DTCNumber "Diagnostic Trouble Code Information Extended - AMP : Diagnostic Trouble Code Number";
BA_ "SignalLongName" SG_ 1109 DTCI_AMP_DTCSource "Diagnostic Trouble Code Information Extended - AMP : Diagnostic Trouble Code Source";
BA_ "SignalType" SG_ 1109 DTCI_AMP_TstNCmpltdOpCyc "ENM";
BA_ "SignalLongName" SG_ 1109 DTCI_AMP_TstNCmpltdOpCyc "Diagnostic Trouble Code Information Extended - AMP : Test Not Completed This Operation Cycle";
BA_ "SignalType" SG_ 1109 DTCI_AMP_TstNCmpltdLstClr "ENM";
BA_ "SignalLongName" SG_ 1109 DTCI_AMP_TstNCmpltdLstClr "Diagnostic Trouble Code Information Extended - AMP : Test Not Completed Since Last Clear";
BA_ "SignalType" SG_ 1109 DTCI_AMP_TstFldOpCyc "ENM";
BA_ "SignalLongName" SG_ 1109 DTCI_AMP_TstFldOpCyc "Diagnostic Trouble Code Information Extended - AMP : Test Failed This Operation Cycle";
BA_ "SignalType" SG_ 1109 DTCI_AMP_TstFldLstClr "ENM";
BA_ "SignalLongName" SG_ 1109 DTCI_AMP_TstFldLstClr "Diagnostic Trouble Code Information Extended - AMP : Test Failed Since Last Clear";
BA_ "SignalType" SG_ 1109 DTCI_AMP_TstFld "ENM";
BA_ "SignalLongName" SG_ 1109 DTCI_AMP_TstFld "Diagnostic Trouble Code Information Extended - AMP : Test Failed";
BA_ "SignalType" SG_ 1109 DTCI_AMP_PndngDTC "ENM";
BA_ "SignalLongName" SG_ 1109 DTCI_AMP_PndngDTC "Diagnostic Trouble Code Information Extended - AMP : Pending DTC";
BA_ "SignalType" SG_ 1109 DTCI_AMP_DTCTriggered "ENM";
BA_ "SignalLongName" SG_ 1109 DTCI_AMP_DTCTriggered "Diagnostic Trouble Code Information Extended - AMP : Diagnostic Trouble Code Triggered";
BA_ "SignalType" SG_ 1109 DTCI_AMP_WrnIndTrggrd "ENM";
BA_ "SignalLongName" SG_ 1109 DTCI_AMP_WrnIndTrggrd "Diagnostic Trouble Code Information Extended - AMP : Warning Indicator Triggered";
BA_ "SignalType" SG_ 1109 DTCI_AMP_WrnIndRqd "ENM";
BA_ "SignalLongName" SG_ 1109 DTCI_AMP_WrnIndRqd "Diagnostic Trouble Code Information Extended - AMP : Warning Indicator Requested";
BA_ "SignalLongName" SG_ 1118 DTCI_AOS_DTCFailType "Diagnostic Trouble Code Information Extended - AOS : Diagnostic Trouble Code Failure Type";
BA_ "SignalType" SG_ 1118 DTCI_AOS_CnfrmdDTC "ENM";
BA_ "SignalLongName" SG_ 1118 DTCI_AOS_CnfrmdDTC "Diagnostic Trouble Code Information Extended - AOS : Confirmed DTC";
BA_ "SignalType" SG_ 1118 DTCI_AOS_DTCFaultType "ENM";
BA_ "SignalLongName" SG_ 1118 DTCI_AOS_DTCFaultType "Diagnostic Trouble Code Information Extended - AOS : Diagnostic Trouble Code Fault Type";
BA_ "SignalLongName" SG_ 1118 DTCI_AOS_DTCNumber "Diagnostic Trouble Code Information Extended - AOS : Diagnostic Trouble Code Number";
BA_ "SignalLongName" SG_ 1118 DTCI_AOS_DTCSource "Diagnostic Trouble Code Information Extended - AOS : Diagnostic Trouble Code Source";
BA_ "SignalType" SG_ 1118 DTCI_AOS_TstNCmpltdOpCyc "ENM";
BA_ "SignalLongName" SG_ 1118 DTCI_AOS_TstNCmpltdOpCyc "Diagnostic Trouble Code Information Extended - AOS : Test Not Completed This Operation Cycle";
BA_ "SignalType" SG_ 1118 DTCI_AOS_TstNCmpltdLstClr "ENM";
BA_ "SignalLongName" SG_ 1118 DTCI_AOS_TstNCmpltdLstClr "Diagnostic Trouble Code Information Extended - AOS : Test Not Completed Since Last Clear";
BA_ "SignalType" SG_ 1118 DTCI_AOS_TstFldOpCyc "ENM";
BA_ "SignalLongName" SG_ 1118 DTCI_AOS_TstFldOpCyc "Diagnostic Trouble Code Information Extended - AOS : Test Failed This Operation Cycle";
BA_ "SignalType" SG_ 1118 DTCI_AOS_TstFldLstClr "ENM";
BA_ "SignalLongName" SG_ 1118 DTCI_AOS_TstFldLstClr "Diagnostic Trouble Code Information Extended - AOS : Test Failed Since Last Clear";
BA_ "SignalType" SG_ 1118 DTCI_AOS_TstFld "ENM";
BA_ "SignalLongName" SG_ 1118 DTCI_AOS_TstFld "Diagnostic Trouble Code Information Extended - AOS : Test Failed";
BA_ "SignalType" SG_ 1118 DTCI_AOS_PndngDTC "ENM";
BA_ "SignalLongName" SG_ 1118 DTCI_AOS_PndngDTC "Diagnostic Trouble Code Information Extended - AOS : Pending DTC";
BA_ "SignalType" SG_ 1118 DTCI_AOS_DTCTriggered "ENM";
BA_ "SignalLongName" SG_ 1118 DTCI_AOS_DTCTriggered "Diagnostic Trouble Code Information Extended - AOS : Diagnostic Trouble Code Triggered";
BA_ "SignalType" SG_ 1118 DTCI_AOS_WrnIndTrggrd "ENM";
BA_ "SignalLongName" SG_ 1118 DTCI_AOS_WrnIndTrggrd "Diagnostic Trouble Code Information Extended - AOS : Warning Indicator Triggered";
BA_ "SignalType" SG_ 1118 DTCI_AOS_WrnIndRqd "ENM";
BA_ "SignalLongName" SG_ 1118 DTCI_AOS_WrnIndRqd "Diagnostic Trouble Code Information Extended - AOS : Warning Indicator Requested";
BA_ "SignalLongName" SG_ 1119 DTCI_APA_DTCFailType "Diagnostic Trouble Code Information Extended - APA : Diagnostic Trouble Code Failure Type";
BA_ "SignalType" SG_ 1119 DTCI_APA_CnfrmdDTC "ENM";
BA_ "SignalLongName" SG_ 1119 DTCI_APA_CnfrmdDTC "Diagnostic Trouble Code Information Extended - APA : Confirmed DTC";
BA_ "SignalType" SG_ 1119 DTCI_APA_DTCFaultType "ENM";
BA_ "SignalLongName" SG_ 1119 DTCI_APA_DTCFaultType "Diagnostic Trouble Code Information Extended - APA : Diagnostic Trouble Code Fault Type";
BA_ "SignalLongName" SG_ 1119 DTCI_APA_DTCNumber "Diagnostic Trouble Code Information Extended - APA : Diagnostic Trouble Code Number";
BA_ "SignalLongName" SG_ 1119 DTCI_APA_DTCSource "Diagnostic Trouble Code Information Extended - APA : Diagnostic Trouble Code Source";
BA_ "SignalType" SG_ 1119 DTCI_APA_TstNCmpltdOpCyc "ENM";
BA_ "SignalLongName" SG_ 1119 DTCI_APA_TstNCmpltdOpCyc "Diagnostic Trouble Code Information Extended - APA : Test Not Completed This Operation Cycle";
BA_ "SignalType" SG_ 1119 DTCI_APA_TstNCmpltdLstClr "ENM";
BA_ "SignalLongName" SG_ 1119 DTCI_APA_TstNCmpltdLstClr "Diagnostic Trouble Code Information Extended - APA : Test Not Completed Since Last Clear";
BA_ "SignalType" SG_ 1119 DTCI_APA_TstFldOpCyc "ENM";
BA_ "SignalLongName" SG_ 1119 DTCI_APA_TstFldOpCyc "Diagnostic Trouble Code Information Extended - APA : Test Failed This Operation Cycle";
BA_ "SignalType" SG_ 1119 DTCI_APA_TstFldLstClr "ENM";
BA_ "SignalLongName" SG_ 1119 DTCI_APA_TstFldLstClr "Diagnostic Trouble Code Information Extended - APA : Test Failed Since Last Clear";
BA_ "SignalType" SG_ 1119 DTCI_APA_TstFld "ENM";
BA_ "SignalLongName" SG_ 1119 DTCI_APA_TstFld "Diagnostic Trouble Code Information Extended - APA : Test Failed";
BA_ "SignalType" SG_ 1119 DTCI_APA_PndngDTC "ENM";
BA_ "SignalLongName" SG_ 1119 DTCI_APA_PndngDTC "Diagnostic Trouble Code Information Extended - APA : Pending DTC";
BA_ "SignalType" SG_ 1119 DTCI_APA_DTCTriggered "ENM";
BA_ "SignalLongName" SG_ 1119 DTCI_APA_DTCTriggered "Diagnostic Trouble Code Information Extended - APA : Diagnostic Trouble Code Triggered";
BA_ "SignalType" SG_ 1119 DTCI_APA_WrnIndTrggrd "ENM";
BA_ "SignalLongName" SG_ 1119 DTCI_APA_WrnIndTrggrd "Diagnostic Trouble Code Information Extended - APA : Warning Indicator Triggered";
BA_ "SignalType" SG_ 1119 DTCI_APA_WrnIndRqd "ENM";
BA_ "SignalLongName" SG_ 1119 DTCI_APA_WrnIndRqd "Diagnostic Trouble Code Information Extended - APA : Warning Indicator Requested";
BA_ "SignalLongName" SG_ 1120 DTCI_ARB_DTCFailType "Diagnostic Trouble Code Information Extended - ARB : Diagnostic Trouble Code Failure Type";
BA_ "SignalType" SG_ 1120 DTCI_ARB_CnfrmdDTC "ENM";
BA_ "SignalLongName" SG_ 1120 DTCI_ARB_CnfrmdDTC "Diagnostic Trouble Code Information Extended - ARB : Confirmed DTC";
BA_ "SignalType" SG_ 1120 DTCI_ARB_DTCFaultType "ENM";
BA_ "SignalLongName" SG_ 1120 DTCI_ARB_DTCFaultType "Diagnostic Trouble Code Information Extended - ARB : Diagnostic Trouble Code Fault Type";
BA_ "SignalLongName" SG_ 1120 DTCI_ARB_DTCNumber "Diagnostic Trouble Code Information Extended - ARB : Diagnostic Trouble Code Number";
BA_ "SignalLongName" SG_ 1120 DTCI_ARB_DTCSource "Diagnostic Trouble Code Information Extended - ARB : Diagnostic Trouble Code Source";
BA_ "SignalType" SG_ 1120 DTCI_ARB_TstNCmpltdOpCyc "ENM";
BA_ "SignalLongName" SG_ 1120 DTCI_ARB_TstNCmpltdOpCyc "Diagnostic Trouble Code Information Extended - ARB : Test Not Completed This Operation Cycle";
BA_ "SignalType" SG_ 1120 DTCI_ARB_TstNCmpltdLstClr "ENM";
BA_ "SignalLongName" SG_ 1120 DTCI_ARB_TstNCmpltdLstClr "Diagnostic Trouble Code Information Extended - ARB : Test Not Completed Since Last Clear";
BA_ "SignalType" SG_ 1120 DTCI_ARB_TstFldOpCyc "ENM";
BA_ "SignalLongName" SG_ 1120 DTCI_ARB_TstFldOpCyc "Diagnostic Trouble Code Information Extended - ARB : Test Failed This Operation Cycle";
BA_ "SignalType" SG_ 1120 DTCI_ARB_TstFldLstClr "ENM";
BA_ "SignalLongName" SG_ 1120 DTCI_ARB_TstFldLstClr "Diagnostic Trouble Code Information Extended - ARB : Test Failed Since Last Clear";
BA_ "SignalType" SG_ 1120 DTCI_ARB_TstFld "ENM";
BA_ "SignalLongName" SG_ 1120 DTCI_ARB_TstFld "Diagnostic Trouble Code Information Extended - ARB : Test Failed";
BA_ "SignalType" SG_ 1120 DTCI_ARB_PndngDTC "ENM";
BA_ "SignalLongName" SG_ 1120 DTCI_ARB_PndngDTC "Diagnostic Trouble Code Information Extended - ARB : Pending DTC";
BA_ "SignalType" SG_ 1120 DTCI_ARB_DTCTriggered "ENM";
BA_ "SignalLongName" SG_ 1120 DTCI_ARB_DTCTriggered "Diagnostic Trouble Code Information Extended - ARB : Diagnostic Trouble Code Triggered";
BA_ "SignalType" SG_ 1120 DTCI_ARB_WrnIndTrggrd "ENM";
BA_ "SignalLongName" SG_ 1120 DTCI_ARB_WrnIndTrggrd "Diagnostic Trouble Code Information Extended - ARB : Warning Indicator Triggered";
BA_ "SignalType" SG_ 1120 DTCI_ARB_WrnIndRqd "ENM";
BA_ "SignalLongName" SG_ 1120 DTCI_ARB_WrnIndRqd "Diagnostic Trouble Code Information Extended - ARB : Warning Indicator Requested";
BA_ "SignalLongName" SG_ 1054 DTCI_ARS_DTCFailType "Diagnostic Trouble Code Information Extended - ARS : Diagnostic Trouble Code Failure Type";
BA_ "SignalType" SG_ 1054 DTCI_ARS_CnfrmdDTC "ENM";
BA_ "SignalLongName" SG_ 1054 DTCI_ARS_CnfrmdDTC "Diagnostic Trouble Code Information Extended - ARS : Confirmed DTC";
BA_ "SignalType" SG_ 1054 DTCI_ARS_DTCFaultType "ENM";
BA_ "SignalLongName" SG_ 1054 DTCI_ARS_DTCFaultType "Diagnostic Trouble Code Information Extended - ARS : Diagnostic Trouble Code Fault Type";
BA_ "SignalLongName" SG_ 1054 DTCI_ARS_DTCNumber "Diagnostic Trouble Code Information Extended - ARS : Diagnostic Trouble Code Number";
BA_ "SignalLongName" SG_ 1054 DTCI_ARS_DTCSource "Diagnostic Trouble Code Information Extended - ARS : Diagnostic Trouble Code Source";
BA_ "SignalType" SG_ 1054 DTCI_ARS_TstNCmpltdOpCyc "ENM";
BA_ "SignalLongName" SG_ 1054 DTCI_ARS_TstNCmpltdOpCyc "Diagnostic Trouble Code Information Extended - ARS : Test Not Completed This Operation Cycle";
BA_ "SignalType" SG_ 1054 DTCI_ARS_TstNCmpltdLstClr "ENM";
BA_ "SignalLongName" SG_ 1054 DTCI_ARS_TstNCmpltdLstClr "Diagnostic Trouble Code Information Extended - ARS : Test Not Completed Since Last Clear";
BA_ "SignalType" SG_ 1054 DTCI_ARS_TstFldOpCyc "ENM";
BA_ "SignalLongName" SG_ 1054 DTCI_ARS_TstFldOpCyc "Diagnostic Trouble Code Information Extended - ARS : Test Failed This Operation Cycle";
BA_ "SignalType" SG_ 1054 DTCI_ARS_TstFldLstClr "ENM";
BA_ "SignalLongName" SG_ 1054 DTCI_ARS_TstFldLstClr "Diagnostic Trouble Code Information Extended - ARS : Test Failed Since Last Clear";
BA_ "SignalType" SG_ 1054 DTCI_ARS_TstFld "ENM";
BA_ "SignalLongName" SG_ 1054 DTCI_ARS_TstFld "Diagnostic Trouble Code Information Extended - ARS : Test Failed";
BA_ "SignalType" SG_ 1054 DTCI_ARS_PndngDTC "ENM";
BA_ "SignalLongName" SG_ 1054 DTCI_ARS_PndngDTC "Diagnostic Trouble Code Information Extended - ARS : Pending DTC";
BA_ "SignalType" SG_ 1054 DTCI_ARS_DTCTriggered "ENM";
BA_ "SignalLongName" SG_ 1054 DTCI_ARS_DTCTriggered "Diagnostic Trouble Code Information Extended - ARS : Diagnostic Trouble Code Triggered";
BA_ "SignalType" SG_ 1054 DTCI_ARS_WrnIndTrggrd "ENM";
BA_ "SignalLongName" SG_ 1054 DTCI_ARS_WrnIndTrggrd "Diagnostic Trouble Code Information Extended - ARS : Warning Indicator Triggered";
BA_ "SignalType" SG_ 1054 DTCI_ARS_WrnIndRqd "ENM";
BA_ "SignalLongName" SG_ 1054 DTCI_ARS_WrnIndRqd "Diagnostic Trouble Code Information Extended - ARS : Warning Indicator Requested";
BA_ "SignalLongName" SG_ 1121 DTCI_BCM_DTCFailType "Diagnostic Trouble Code Information Extended - BCM : Diagnostic Trouble Code Failure Type";
BA_ "SignalType" SG_ 1121 DTCI_BCM_CnfrmdDTC "ENM";
BA_ "SignalLongName" SG_ 1121 DTCI_BCM_CnfrmdDTC "Diagnostic Trouble Code Information Extended - BCM : Confirmed DTC";
BA_ "SignalType" SG_ 1121 DTCI_BCM_DTCFaultType "ENM";
BA_ "SignalLongName" SG_ 1121 DTCI_BCM_DTCFaultType "Diagnostic Trouble Code Information Extended - BCM : Diagnostic Trouble Code Fault Type";
BA_ "SignalLongName" SG_ 1121 DTCI_BCM_DTCNumber "Diagnostic Trouble Code Information Extended - BCM : Diagnostic Trouble Code Number";
BA_ "SignalLongName" SG_ 1121 DTCI_BCM_DTCSource "Diagnostic Trouble Code Information Extended - BCM : Diagnostic Trouble Code Source";
BA_ "SignalType" SG_ 1121 DTCI_BCM_TstNCmpltdOpCyc "ENM";
BA_ "SignalLongName" SG_ 1121 DTCI_BCM_TstNCmpltdOpCyc "Diagnostic Trouble Code Information Extended - BCM : Test Not Completed This Operation Cycle";
BA_ "SignalType" SG_ 1121 DTCI_BCM_TstNCmpltdLstClr "ENM";
BA_ "SignalLongName" SG_ 1121 DTCI_BCM_TstNCmpltdLstClr "Diagnostic Trouble Code Information Extended - BCM : Test Not Completed Since Last Clear";
BA_ "SignalType" SG_ 1121 DTCI_BCM_TstFldOpCyc "ENM";
BA_ "SignalLongName" SG_ 1121 DTCI_BCM_TstFldOpCyc "Diagnostic Trouble Code Information Extended - BCM : Test Failed This Operation Cycle";
BA_ "SignalType" SG_ 1121 DTCI_BCM_TstFldLstClr "ENM";
BA_ "SignalLongName" SG_ 1121 DTCI_BCM_TstFldLstClr "Diagnostic Trouble Code Information Extended - BCM : Test Failed Since Last Clear";
BA_ "SignalType" SG_ 1121 DTCI_BCM_TstFld "ENM";
BA_ "SignalLongName" SG_ 1121 DTCI_BCM_TstFld "Diagnostic Trouble Code Information Extended - BCM : Test Failed";
BA_ "SignalType" SG_ 1121 DTCI_BCM_PndngDTC "ENM";
BA_ "SignalLongName" SG_ 1121 DTCI_BCM_PndngDTC "Diagnostic Trouble Code Information Extended - BCM : Pending DTC";
BA_ "SignalType" SG_ 1121 DTCI_BCM_DTCTriggered "ENM";
BA_ "SignalLongName" SG_ 1121 DTCI_BCM_DTCTriggered "Diagnostic Trouble Code Information Extended - BCM : Diagnostic Trouble Code Triggered";
BA_ "SignalType" SG_ 1121 DTCI_BCM_WrnIndTrggrd "ENM";
BA_ "SignalLongName" SG_ 1121 DTCI_BCM_WrnIndTrggrd "Diagnostic Trouble Code Information Extended - BCM : Warning Indicator Triggered";
BA_ "SignalType" SG_ 1121 DTCI_BCM_WrnIndRqd "ENM";
BA_ "SignalLongName" SG_ 1121 DTCI_BCM_WrnIndRqd "Diagnostic Trouble Code Information Extended - BCM : Warning Indicator Requested";
BA_ "SignalLongName" SG_ 1411 DTCI_BSM_MH_DTCFailType "Diagnostic Trouble Code Information Extended - BSM_MH : Diagnostic Trouble Code Failure Type";
BA_ "SignalType" SG_ 1411 DTCI_BSM_MH_CnfrmdDTC "ENM";
BA_ "SignalLongName" SG_ 1411 DTCI_BSM_MH_CnfrmdDTC "Diagnostic Trouble Code Information Extended - BSM_MH : Confirmed DTC";
BA_ "SignalType" SG_ 1411 DTCI_BSM_MH_DTCFaultType "ENM";
BA_ "SignalLongName" SG_ 1411 DTCI_BSM_MH_DTCFaultType "Diagnostic Trouble Code Information Extended - BSM_MH : Diagnostic Trouble Code Fault Type";
BA_ "SignalLongName" SG_ 1411 DTCI_BSM_MH_DTCNumber "Diagnostic Trouble Code Information Extended - BSM_MH : Diagnostic Trouble Code Number";
BA_ "SignalLongName" SG_ 1411 DTCI_BSM_MH_DTCSource "Diagnostic Trouble Code Information Extended - BSM_MH : Diagnostic Trouble Code Source";
BA_ "SignalType" SG_ 1411 DTCI_BSM_MH_TstNCmpltdOpCyc "ENM";
BA_ "SignalLongName" SG_ 1411 DTCI_BSM_MH_TstNCmpltdOpCyc "Diagnostic Trouble Code Information Extended - BSM_MH : Test Not Completed This Operation Cycle";
BA_ "SignalType" SG_ 1411 DTCI_BSM_MH_TstNCmpltdLstClr "ENM";
BA_ "SignalLongName" SG_ 1411 DTCI_BSM_MH_TstNCmpltdLstClr "Diagnostic Trouble Code Information Extended - BSM_MH : Test Not Completed Since Last Clear";
BA_ "SignalType" SG_ 1411 DTCI_BSM_MH_TstFldOpCyc "ENM";
BA_ "SignalLongName" SG_ 1411 DTCI_BSM_MH_TstFldOpCyc "Diagnostic Trouble Code Information Extended - BSM_MH : Test Failed This Operation Cycle";
BA_ "SignalType" SG_ 1411 DTCI_BSM_MH_TstFldLstClr "ENM";
BA_ "SignalLongName" SG_ 1411 DTCI_BSM_MH_TstFldLstClr "Diagnostic Trouble Code Information Extended - BSM_MH : Test Failed Since Last Clear";
BA_ "SignalType" SG_ 1411 DTCI_BSM_MH_TstFld "ENM";
BA_ "SignalLongName" SG_ 1411 DTCI_BSM_MH_TstFld "Diagnostic Trouble Code Information Extended - BSM_MH : Test Failed";
BA_ "SignalType" SG_ 1411 DTCI_BSM_MH_PndngDTC "ENM";
BA_ "SignalLongName" SG_ 1411 DTCI_BSM_MH_PndngDTC "Diagnostic Trouble Code Information Extended - BSM_MH : Pending DTC";
BA_ "SignalType" SG_ 1411 DTCI_BSM_MH_DTCTriggered "ENM";
BA_ "SignalLongName" SG_ 1411 DTCI_BSM_MH_DTCTriggered "Diagnostic Trouble Code Information Extended - BSM_MH : Diagnostic Trouble Code Triggered";
BA_ "SignalType" SG_ 1411 DTCI_BSM_MH_WrnIndTrggrd "ENM";
BA_ "SignalLongName" SG_ 1411 DTCI_BSM_MH_WrnIndTrggrd "Diagnostic Trouble Code Information Extended - BSM_MH : Warning Indicator Triggered";
BA_ "SignalType" SG_ 1411 DTCI_BSM_MH_WrnIndRqd "ENM";
BA_ "SignalLongName" SG_ 1411 DTCI_BSM_MH_WrnIndRqd "Diagnostic Trouble Code Information Extended - BSM_MH : Warning Indicator Requested";
BA_ "SignalLongName" SG_ 1122 DTCI_BSM_DTCFailType "Diagnostic Trouble Code Information Extended - BSM : Diagnostic Trouble Code Failure Type";
BA_ "SignalType" SG_ 1122 DTCI_BSM_CnfrmdDTC "ENM";
BA_ "SignalLongName" SG_ 1122 DTCI_BSM_CnfrmdDTC "Diagnostic Trouble Code Information Extended - BSM : Confirmed DTC";
BA_ "SignalType" SG_ 1122 DTCI_BSM_DTCFaultType "ENM";
BA_ "SignalLongName" SG_ 1122 DTCI_BSM_DTCFaultType "Diagnostic Trouble Code Information Extended - BSM : Diagnostic Trouble Code Fault Type";
BA_ "SignalLongName" SG_ 1122 DTCI_BSM_DTCNumber "Diagnostic Trouble Code Information Extended - BSM : Diagnostic Trouble Code Number";
BA_ "SignalLongName" SG_ 1122 DTCI_BSM_DTCSource "Diagnostic Trouble Code Information Extended - BSM : Diagnostic Trouble Code Source";
BA_ "SignalType" SG_ 1122 DTCI_BSM_TstNCmpltdOpCyc "ENM";
BA_ "SignalLongName" SG_ 1122 DTCI_BSM_TstNCmpltdOpCyc "Diagnostic Trouble Code Information Extended - BSM : Test Not Completed This Operation Cycle";
BA_ "SignalType" SG_ 1122 DTCI_BSM_TstNCmpltdLstClr "ENM";
BA_ "SignalLongName" SG_ 1122 DTCI_BSM_TstNCmpltdLstClr "Diagnostic Trouble Code Information Extended - BSM : Test Not Completed Since Last Clear";
BA_ "SignalType" SG_ 1122 DTCI_BSM_TstFldOpCyc "ENM";
BA_ "SignalLongName" SG_ 1122 DTCI_BSM_TstFldOpCyc "Diagnostic Trouble Code Information Extended - BSM : Test Failed This Operation Cycle";
BA_ "SignalType" SG_ 1122 DTCI_BSM_TstFldLstClr "ENM";
BA_ "SignalLongName" SG_ 1122 DTCI_BSM_TstFldLstClr "Diagnostic Trouble Code Information Extended - BSM : Test Failed Since Last Clear";
BA_ "SignalType" SG_ 1122 DTCI_BSM_TstFld "ENM";
BA_ "SignalLongName" SG_ 1122 DTCI_BSM_TstFld "Diagnostic Trouble Code Information Extended - BSM : Test Failed";
BA_ "SignalType" SG_ 1122 DTCI_BSM_PndngDTC "ENM";
BA_ "SignalLongName" SG_ 1122 DTCI_BSM_PndngDTC "Diagnostic Trouble Code Information Extended - BSM : Pending DTC";
BA_ "SignalType" SG_ 1122 DTCI_BSM_DTCTriggered "ENM";
BA_ "SignalLongName" SG_ 1122 DTCI_BSM_DTCTriggered "Diagnostic Trouble Code Information Extended - BSM : Diagnostic Trouble Code Triggered";
BA_ "SignalType" SG_ 1122 DTCI_BSM_WrnIndTrggrd "ENM";
BA_ "SignalLongName" SG_ 1122 DTCI_BSM_WrnIndTrggrd "Diagnostic Trouble Code Information Extended - BSM : Warning Indicator Triggered";
BA_ "SignalType" SG_ 1122 DTCI_BSM_WrnIndRqd "ENM";
BA_ "SignalLongName" SG_ 1122 DTCI_BSM_WrnIndRqd "Diagnostic Trouble Code Information Extended - BSM : Warning Indicator Requested";
BA_ "SignalLongName" SG_ 1123 DTCI_CGM_DTCFailType "Diagnostic Trouble Code Information Extended - CGM : Diagnostic Trouble Code Failure Type";
BA_ "SignalType" SG_ 1123 DTCI_CGM_CnfrmdDTC "ENM";
BA_ "SignalLongName" SG_ 1123 DTCI_CGM_CnfrmdDTC "Diagnostic Trouble Code Information Extended - CGM : Confirmed DTC";
BA_ "SignalType" SG_ 1123 DTCI_CGM_DTCFaultType "ENM";
BA_ "SignalLongName" SG_ 1123 DTCI_CGM_DTCFaultType "Diagnostic Trouble Code Information Extended - CGM : Diagnostic Trouble Code Fault Type";
BA_ "SignalLongName" SG_ 1123 DTCI_CGM_DTCNumber "Diagnostic Trouble Code Information Extended - CGM : Diagnostic Trouble Code Number";
BA_ "SignalLongName" SG_ 1123 DTCI_CGM_DTCSource "Diagnostic Trouble Code Information Extended - CGM : Diagnostic Trouble Code Source";
BA_ "SignalType" SG_ 1123 DTCI_CGM_TstNCmpltdOpCyc "ENM";
BA_ "SignalLongName" SG_ 1123 DTCI_CGM_TstNCmpltdOpCyc "Diagnostic Trouble Code Information Extended - CGM : Test Not Completed This Operation Cycle";
BA_ "SignalType" SG_ 1123 DTCI_CGM_TstNCmpltdLstClr "ENM";
BA_ "SignalLongName" SG_ 1123 DTCI_CGM_TstNCmpltdLstClr "Diagnostic Trouble Code Information Extended - CGM : Test Not Completed Since Last Clear";
BA_ "SignalType" SG_ 1123 DTCI_CGM_TstFldOpCyc "ENM";
BA_ "SignalLongName" SG_ 1123 DTCI_CGM_TstFldOpCyc "Diagnostic Trouble Code Information Extended - CGM : Test Failed This Operation Cycle";
BA_ "SignalType" SG_ 1123 DTCI_CGM_TstFldLstClr "ENM";
BA_ "SignalLongName" SG_ 1123 DTCI_CGM_TstFldLstClr "Diagnostic Trouble Code Information Extended - CGM : Test Failed Since Last Clear";
BA_ "SignalType" SG_ 1123 DTCI_CGM_TstFld "ENM";
BA_ "SignalLongName" SG_ 1123 DTCI_CGM_TstFld "Diagnostic Trouble Code Information Extended - CGM : Test Failed";
BA_ "SignalType" SG_ 1123 DTCI_CGM_PndngDTC "ENM";
BA_ "SignalLongName" SG_ 1123 DTCI_CGM_PndngDTC "Diagnostic Trouble Code Information Extended - CGM : Pending DTC";
BA_ "SignalType" SG_ 1123 DTCI_CGM_DTCTriggered "ENM";
BA_ "SignalLongName" SG_ 1123 DTCI_CGM_DTCTriggered "Diagnostic Trouble Code Information Extended - CGM : Diagnostic Trouble Code Triggered";
BA_ "SignalType" SG_ 1123 DTCI_CGM_WrnIndTrggrd "ENM";
BA_ "SignalLongName" SG_ 1123 DTCI_CGM_WrnIndTrggrd "Diagnostic Trouble Code Information Extended - CGM : Warning Indicator Triggered";
BA_ "SignalType" SG_ 1123 DTCI_CGM_WrnIndRqd "ENM";
BA_ "SignalLongName" SG_ 1123 DTCI_CGM_WrnIndRqd "Diagnostic Trouble Code Information Extended - CGM : Warning Indicator Requested";
BA_ "SignalLongName" SG_ 1065 DTCI_CMMa_DTCFailType "Diagnostic Trouble Code Information Extended - CMMa : Diagnostic Trouble Code Failure Type";
BA_ "SignalType" SG_ 1065 DTCI_CMMa_CnfrmdDTC "ENM";
BA_ "SignalLongName" SG_ 1065 DTCI_CMMa_CnfrmdDTC "Diagnostic Trouble Code Information Extended - CMMa : Confirmed DTC";
BA_ "SignalType" SG_ 1065 DTCI_CMMa_DTCFaultType "ENM";
BA_ "SignalLongName" SG_ 1065 DTCI_CMMa_DTCFaultType "Diagnostic Trouble Code Information Extended - CMMa : Diagnostic Trouble Code Fault Type";
BA_ "SignalLongName" SG_ 1065 DTCI_CMMa_DTCNumber "Diagnostic Trouble Code Information Extended - CMMa : Diagnostic Trouble Code Number";
BA_ "SignalLongName" SG_ 1065 DTCI_CMMa_DTCSource "Diagnostic Trouble Code Information Extended - CMMa : Diagnostic Trouble Code Source";
BA_ "SignalType" SG_ 1065 DTCI_CMMa_TstNCmpltdOpCyc "ENM";
BA_ "SignalLongName" SG_ 1065 DTCI_CMMa_TstNCmpltdOpCyc "Diagnostic Trouble Code Information Extended - CMMa : Test Not Completed This Operation Cycle";
BA_ "SignalType" SG_ 1065 DTCI_CMMa_TstNCmpltdLstClr "ENM";
BA_ "SignalLongName" SG_ 1065 DTCI_CMMa_TstNCmpltdLstClr "Diagnostic Trouble Code Information Extended - CMMa : Test Not Completed Since Last Clear";
BA_ "SignalType" SG_ 1065 DTCI_CMMa_TstFldOpCyc "ENM";
BA_ "SignalLongName" SG_ 1065 DTCI_CMMa_TstFldOpCyc "Diagnostic Trouble Code Information Extended - CMMa : Test Failed This Operation Cycle";
BA_ "SignalType" SG_ 1065 DTCI_CMMa_TstFldLstClr "ENM";
BA_ "SignalLongName" SG_ 1065 DTCI_CMMa_TstFldLstClr "Diagnostic Trouble Code Information Extended - CMMa : Test Failed Since Last Clear";
BA_ "SignalType" SG_ 1065 DTCI_CMMa_TstFld "ENM";
BA_ "SignalLongName" SG_ 1065 DTCI_CMMa_TstFld "Diagnostic Trouble Code Information Extended - CMMa : Test Failed";
BA_ "SignalType" SG_ 1065 DTCI_CMMa_PndngDTC "ENM";
BA_ "SignalLongName" SG_ 1065 DTCI_CMMa_PndngDTC "Diagnostic Trouble Code Information Extended - CMMa : Pending DTC";
BA_ "SignalType" SG_ 1065 DTCI_CMMa_DTCTriggered "ENM";
BA_ "SignalLongName" SG_ 1065 DTCI_CMMa_DTCTriggered "Diagnostic Trouble Code Information Extended - CMMa : Diagnostic Trouble Code Triggered";
BA_ "SignalType" SG_ 1065 DTCI_CMMa_WrnIndTrggrd "ENM";
BA_ "SignalLongName" SG_ 1065 DTCI_CMMa_WrnIndTrggrd "Diagnostic Trouble Code Information Extended - CMMa : Warning Indicator Triggered";
BA_ "SignalType" SG_ 1065 DTCI_CMMa_WrnIndRqd "ENM";
BA_ "SignalLongName" SG_ 1065 DTCI_CMMa_WrnIndRqd "Diagnostic Trouble Code Information Extended - CMMa : Warning Indicator Requested";
BA_ "SignalLongName" SG_ 1072 DTCI_CMMb_DTCFailType "Diagnostic Trouble Code Information Extended - CMMb : Diagnostic Trouble Code Failure Type";
BA_ "SignalType" SG_ 1072 DTCI_CMMb_CnfrmdDTC "ENM";
BA_ "SignalLongName" SG_ 1072 DTCI_CMMb_CnfrmdDTC "Diagnostic Trouble Code Information Extended - CMMb : Confirmed DTC";
BA_ "SignalType" SG_ 1072 DTCI_CMMb_DTCFaultType "ENM";
BA_ "SignalLongName" SG_ 1072 DTCI_CMMb_DTCFaultType "Diagnostic Trouble Code Information Extended - CMMb : Diagnostic Trouble Code Fault Type";
BA_ "SignalLongName" SG_ 1072 DTCI_CMMb_DTCNumber "Diagnostic Trouble Code Information Extended - CMMb : Diagnostic Trouble Code Number";
BA_ "SignalLongName" SG_ 1072 DTCI_CMMb_DTCSource "Diagnostic Trouble Code Information Extended - CMMb : Diagnostic Trouble Code Source";
BA_ "SignalType" SG_ 1072 DTCI_CMMb_TstNCmpltdOpCyc "ENM";
BA_ "SignalLongName" SG_ 1072 DTCI_CMMb_TstNCmpltdOpCyc "Diagnostic Trouble Code Information Extended - CMMb : Test Not Completed This Operation Cycle";
BA_ "SignalType" SG_ 1072 DTCI_CMMb_TstNCmpltdLstClr "ENM";
BA_ "SignalLongName" SG_ 1072 DTCI_CMMb_TstNCmpltdLstClr "Diagnostic Trouble Code Information Extended - CMMb : Test Not Completed Since Last Clear";
BA_ "SignalType" SG_ 1072 DTCI_CMMb_TstFldOpCyc "ENM";
BA_ "SignalLongName" SG_ 1072 DTCI_CMMb_TstFldOpCyc "Diagnostic Trouble Code Information Extended - CMMb : Test Failed This Operation Cycle";
BA_ "SignalType" SG_ 1072 DTCI_CMMb_TstFldLstClr "ENM";
BA_ "SignalLongName" SG_ 1072 DTCI_CMMb_TstFldLstClr "Diagnostic Trouble Code Information Extended - CMMb : Test Failed Since Last Clear";
BA_ "SignalType" SG_ 1072 DTCI_CMMb_TstFld "ENM";
BA_ "SignalLongName" SG_ 1072 DTCI_CMMb_TstFld "Diagnostic Trouble Code Information Extended - CMMb : Test Failed";
BA_ "SignalType" SG_ 1072 DTCI_CMMb_PndngDTC "ENM";
BA_ "SignalLongName" SG_ 1072 DTCI_CMMb_PndngDTC "Diagnostic Trouble Code Information Extended - CMMb : Pending DTC";
BA_ "SignalType" SG_ 1072 DTCI_CMMb_DTCTriggered "ENM";
BA_ "SignalLongName" SG_ 1072 DTCI_CMMb_DTCTriggered "Diagnostic Trouble Code Information Extended - CMMb : Diagnostic Trouble Code Triggered";
BA_ "SignalType" SG_ 1072 DTCI_CMMb_WrnIndTrggrd "ENM";
BA_ "SignalLongName" SG_ 1072 DTCI_CMMb_WrnIndTrggrd "Diagnostic Trouble Code Information Extended - CMMb : Warning Indicator Triggered";
BA_ "SignalType" SG_ 1072 DTCI_CMMb_WrnIndRqd "ENM";
BA_ "SignalLongName" SG_ 1072 DTCI_CMMb_WrnIndRqd "Diagnostic Trouble Code Information Extended - CMMb : Warning Indicator Requested";
BA_ "SignalLongName" SG_ 1262 DTCI_CSM_DTCFailType "Diagnostic Trouble Code Information Extended - CSM : Diagnostic Trouble Code Failure Type";
BA_ "SignalType" SG_ 1262 DTCI_CSM_CnfrmdDTC "ENM";
BA_ "SignalLongName" SG_ 1262 DTCI_CSM_CnfrmdDTC "Diagnostic Trouble Code Information Extended - CSM : Confirmed DTC";
BA_ "SignalType" SG_ 1262 DTCI_CSM_DTCFaultType "ENM";
BA_ "SignalLongName" SG_ 1262 DTCI_CSM_DTCFaultType "Diagnostic Trouble Code Information Extended - CSM : Diagnostic Trouble Code Fault Type";
BA_ "SignalLongName" SG_ 1262 DTCI_CSM_DTCNumber "Diagnostic Trouble Code Information Extended - CSM : Diagnostic Trouble Code Number";
BA_ "SignalLongName" SG_ 1262 DTCI_CSM_DTCSource "Diagnostic Trouble Code Information Extended - CSM : Diagnostic Trouble Code Source";
BA_ "SignalType" SG_ 1262 DTCI_CSM_TstNCmpltdOpCyc "ENM";
BA_ "SignalLongName" SG_ 1262 DTCI_CSM_TstNCmpltdOpCyc "Diagnostic Trouble Code Information Extended - CSM : Test Not Completed This Operation Cycle";
BA_ "SignalType" SG_ 1262 DTCI_CSM_TstNCmpltdLstClr "ENM";
BA_ "SignalLongName" SG_ 1262 DTCI_CSM_TstNCmpltdLstClr "Diagnostic Trouble Code Information Extended - CSM : Test Not Completed Since Last Clear";
BA_ "SignalType" SG_ 1262 DTCI_CSM_TstFldOpCyc "ENM";
BA_ "SignalLongName" SG_ 1262 DTCI_CSM_TstFldOpCyc "Diagnostic Trouble Code Information Extended - CSM : Test Failed This Operation Cycle";
BA_ "SignalType" SG_ 1262 DTCI_CSM_TstFldLstClr "ENM";
BA_ "SignalLongName" SG_ 1262 DTCI_CSM_TstFldLstClr "Diagnostic Trouble Code Information Extended - CSM : Test Failed Since Last Clear";
BA_ "SignalType" SG_ 1262 DTCI_CSM_TstFld "ENM";
BA_ "SignalLongName" SG_ 1262 DTCI_CSM_TstFld "Diagnostic Trouble Code Information Extended - CSM : Test Failed";
BA_ "SignalType" SG_ 1262 DTCI_CSM_PndngDTC "ENM";
BA_ "SignalLongName" SG_ 1262 DTCI_CSM_PndngDTC "Diagnostic Trouble Code Information Extended - CSM : Pending DTC";
BA_ "SignalType" SG_ 1262 DTCI_CSM_DTCTriggered "ENM";
BA_ "SignalLongName" SG_ 1262 DTCI_CSM_DTCTriggered "Diagnostic Trouble Code Information Extended - CSM : Diagnostic Trouble Code Triggered";
BA_ "SignalType" SG_ 1262 DTCI_CSM_WrnIndTrggrd "ENM";
BA_ "SignalLongName" SG_ 1262 DTCI_CSM_WrnIndTrggrd "Diagnostic Trouble Code Information Extended - CSM : Warning Indicator Triggered";
BA_ "SignalType" SG_ 1262 DTCI_CSM_WrnIndRqd "ENM";
BA_ "SignalLongName" SG_ 1262 DTCI_CSM_WrnIndRqd "Diagnostic Trouble Code Information Extended - CSM : Warning Indicator Requested";
BA_ "SignalLongName" SG_ 1124 DTCI_DCM_DTCFailType "Diagnostic Trouble Code Information Extended - DCM : Diagnostic Trouble Code Failure Type";
BA_ "SignalType" SG_ 1124 DTCI_DCM_CnfrmdDTC "ENM";
BA_ "SignalLongName" SG_ 1124 DTCI_DCM_CnfrmdDTC "Diagnostic Trouble Code Information Extended - DCM : Confirmed DTC";
BA_ "SignalType" SG_ 1124 DTCI_DCM_DTCFaultType "ENM";
BA_ "SignalLongName" SG_ 1124 DTCI_DCM_DTCFaultType "Diagnostic Trouble Code Information Extended - DCM : Diagnostic Trouble Code Fault Type";
BA_ "SignalLongName" SG_ 1124 DTCI_DCM_DTCNumber "Diagnostic Trouble Code Information Extended - DCM : Diagnostic Trouble Code Number";
BA_ "SignalLongName" SG_ 1124 DTCI_DCM_DTCSource "Diagnostic Trouble Code Information Extended - DCM : Diagnostic Trouble Code Source";
BA_ "SignalType" SG_ 1124 DTCI_DCM_TstNCmpltdOpCyc "ENM";
BA_ "SignalLongName" SG_ 1124 DTCI_DCM_TstNCmpltdOpCyc "Diagnostic Trouble Code Information Extended - DCM : Test Not Completed This Operation Cycle";
BA_ "SignalType" SG_ 1124 DTCI_DCM_TstNCmpltdLstClr "ENM";
BA_ "SignalLongName" SG_ 1124 DTCI_DCM_TstNCmpltdLstClr "Diagnostic Trouble Code Information Extended - DCM : Test Not Completed Since Last Clear";
BA_ "SignalType" SG_ 1124 DTCI_DCM_TstFldOpCyc "ENM";
BA_ "SignalLongName" SG_ 1124 DTCI_DCM_TstFldOpCyc "Diagnostic Trouble Code Information Extended - DCM : Test Failed This Operation Cycle";
BA_ "SignalType" SG_ 1124 DTCI_DCM_TstFldLstClr "ENM";
BA_ "SignalLongName" SG_ 1124 DTCI_DCM_TstFldLstClr "Diagnostic Trouble Code Information Extended - DCM : Test Failed Since Last Clear";
BA_ "SignalType" SG_ 1124 DTCI_DCM_TstFld "ENM";
BA_ "SignalLongName" SG_ 1124 DTCI_DCM_TstFld "Diagnostic Trouble Code Information Extended - DCM : Test Failed";
BA_ "SignalType" SG_ 1124 DTCI_DCM_PndngDTC "ENM";
BA_ "SignalLongName" SG_ 1124 DTCI_DCM_PndngDTC "Diagnostic Trouble Code Information Extended - DCM : Pending DTC";
BA_ "SignalType" SG_ 1124 DTCI_DCM_DTCTriggered "ENM";
BA_ "SignalLongName" SG_ 1124 DTCI_DCM_DTCTriggered "Diagnostic Trouble Code Information Extended - DCM : Diagnostic Trouble Code Triggered";
BA_ "SignalType" SG_ 1124 DTCI_DCM_WrnIndTrggrd "ENM";
BA_ "SignalLongName" SG_ 1124 DTCI_DCM_WrnIndTrggrd "Diagnostic Trouble Code Information Extended - DCM : Warning Indicator Triggered";
BA_ "SignalType" SG_ 1124 DTCI_DCM_WrnIndRqd "ENM";
BA_ "SignalLongName" SG_ 1124 DTCI_DCM_WrnIndRqd "Diagnostic Trouble Code Information Extended - DCM : Warning Indicator Requested";
BA_ "SignalLongName" SG_ 1126 DTCI_DMS_DTCFailType "Diagnostic Trouble Code Information Extended - DMS : Diagnostic Trouble Code Failure Type";
BA_ "SignalType" SG_ 1126 DTCI_DMS_CnfrmdDTC "ENM";
BA_ "SignalLongName" SG_ 1126 DTCI_DMS_CnfrmdDTC "Diagnostic Trouble Code Information Extended - DMS : Confirmed DTC";
BA_ "SignalType" SG_ 1126 DTCI_DMS_DTCFaultType "ENM";
BA_ "SignalLongName" SG_ 1126 DTCI_DMS_DTCFaultType "Diagnostic Trouble Code Information Extended - DMS : Diagnostic Trouble Code Fault Type";
BA_ "SignalLongName" SG_ 1126 DTCI_DMS_DTCNumber "Diagnostic Trouble Code Information Extended - DMS : Diagnostic Trouble Code Number";
BA_ "SignalLongName" SG_ 1126 DTCI_DMS_DTCSource "Diagnostic Trouble Code Information Extended - DMS : Diagnostic Trouble Code Source";
BA_ "SignalType" SG_ 1126 DTCI_DMS_TstNCmpltdOpCyc "ENM";
BA_ "SignalLongName" SG_ 1126 DTCI_DMS_TstNCmpltdOpCyc "Diagnostic Trouble Code Information Extended - DMS : Test Not Completed This Operation Cycle";
BA_ "SignalType" SG_ 1126 DTCI_DMS_TstNCmpltdLstClr "ENM";
BA_ "SignalLongName" SG_ 1126 DTCI_DMS_TstNCmpltdLstClr "Diagnostic Trouble Code Information Extended - DMS : Test Not Completed Since Last Clear";
BA_ "SignalType" SG_ 1126 DTCI_DMS_TstFldOpCyc "ENM";
BA_ "SignalLongName" SG_ 1126 DTCI_DMS_TstFldOpCyc "Diagnostic Trouble Code Information Extended - DMS : Test Failed This Operation Cycle";
BA_ "SignalType" SG_ 1126 DTCI_DMS_TstFldLstClr "ENM";
BA_ "SignalLongName" SG_ 1126 DTCI_DMS_TstFldLstClr "Diagnostic Trouble Code Information Extended - DMS : Test Failed Since Last Clear";
BA_ "SignalType" SG_ 1126 DTCI_DMS_TstFld "ENM";
BA_ "SignalLongName" SG_ 1126 DTCI_DMS_TstFld "Diagnostic Trouble Code Information Extended - DMS : Test Failed";
BA_ "SignalType" SG_ 1126 DTCI_DMS_PndngDTC "ENM";
BA_ "SignalLongName" SG_ 1126 DTCI_DMS_PndngDTC "Diagnostic Trouble Code Information Extended - DMS : Pending DTC";
BA_ "SignalType" SG_ 1126 DTCI_DMS_DTCTriggered "ENM";
BA_ "SignalLongName" SG_ 1126 DTCI_DMS_DTCTriggered "Diagnostic Trouble Code Information Extended - DMS : Diagnostic Trouble Code Triggered";
BA_ "SignalType" SG_ 1126 DTCI_DMS_WrnIndTrggrd "ENM";
BA_ "SignalLongName" SG_ 1126 DTCI_DMS_WrnIndTrggrd "Diagnostic Trouble Code Information Extended - DMS : Warning Indicator Triggered";
BA_ "SignalType" SG_ 1126 DTCI_DMS_WrnIndRqd "ENM";
BA_ "SignalLongName" SG_ 1126 DTCI_DMS_WrnIndRqd "Diagnostic Trouble Code Information Extended - DMS : Warning Indicator Requested";
BA_ "SignalLongName" SG_ 1127 DTCI_EBCM_DTCFailType "Diagnostic Trouble Code Information Extended - EBCM : Diagnostic Trouble Code Failure Type";
BA_ "SignalType" SG_ 1127 DTCI_EBCM_CnfrmdDTC "ENM";
BA_ "SignalLongName" SG_ 1127 DTCI_EBCM_CnfrmdDTC "Diagnostic Trouble Code Information Extended - EBCM : Confirmed DTC";
BA_ "SignalType" SG_ 1127 DTCI_EBCM_DTCFaultType "ENM";
BA_ "SignalLongName" SG_ 1127 DTCI_EBCM_DTCFaultType "Diagnostic Trouble Code Information Extended - EBCM : Diagnostic Trouble Code Fault Type";
BA_ "SignalLongName" SG_ 1127 DTCI_EBCM_DTCNumber "Diagnostic Trouble Code Information Extended - EBCM : Diagnostic Trouble Code Number";
BA_ "SignalLongName" SG_ 1127 DTCI_EBCM_DTCSource "Diagnostic Trouble Code Information Extended - EBCM : Diagnostic Trouble Code Source";
BA_ "SignalType" SG_ 1127 DTCI_EBCM_TstNCmpltdOpCyc "ENM";
BA_ "SignalLongName" SG_ 1127 DTCI_EBCM_TstNCmpltdOpCyc "Diagnostic Trouble Code Information Extended - EBCM : Test Not Completed This Operation Cycle";
BA_ "SignalType" SG_ 1127 DTCI_EBCM_TstNCmpltdLstClr "ENM";
BA_ "SignalLongName" SG_ 1127 DTCI_EBCM_TstNCmpltdLstClr "Diagnostic Trouble Code Information Extended - EBCM : Test Not Completed Since Last Clear";
BA_ "SignalType" SG_ 1127 DTCI_EBCM_TstFldOpCyc "ENM";
BA_ "SignalLongName" SG_ 1127 DTCI_EBCM_TstFldOpCyc "Diagnostic Trouble Code Information Extended - EBCM : Test Failed This Operation Cycle";
BA_ "SignalType" SG_ 1127 DTCI_EBCM_TstFldLstClr "ENM";
BA_ "SignalLongName" SG_ 1127 DTCI_EBCM_TstFldLstClr "Diagnostic Trouble Code Information Extended - EBCM : Test Failed Since Last Clear";
BA_ "SignalType" SG_ 1127 DTCI_EBCM_TstFld "ENM";
BA_ "SignalLongName" SG_ 1127 DTCI_EBCM_TstFld "Diagnostic Trouble Code Information Extended - EBCM : Test Failed";
BA_ "SignalType" SG_ 1127 DTCI_EBCM_PndngDTC "ENM";
BA_ "SignalLongName" SG_ 1127 DTCI_EBCM_PndngDTC "Diagnostic Trouble Code Information Extended - EBCM : Pending DTC";
BA_ "SignalType" SG_ 1127 DTCI_EBCM_DTCTriggered "ENM";
BA_ "SignalLongName" SG_ 1127 DTCI_EBCM_DTCTriggered "Diagnostic Trouble Code Information Extended - EBCM : Diagnostic Trouble Code Triggered";
BA_ "SignalType" SG_ 1127 DTCI_EBCM_WrnIndTrggrd "ENM";
BA_ "SignalLongName" SG_ 1127 DTCI_EBCM_WrnIndTrggrd "Diagnostic Trouble Code Information Extended - EBCM : Warning Indicator Triggered";
BA_ "SignalType" SG_ 1127 DTCI_EBCM_WrnIndRqd "ENM";
BA_ "SignalLongName" SG_ 1127 DTCI_EBCM_WrnIndRqd "Diagnostic Trouble Code Information Extended - EBCM : Warning Indicator Requested";
BA_ "SignalLongName" SG_ 1128 DTCI_ECM_DTCFailType "Diagnostic Trouble Code Information Extended - ECM : Diagnostic Trouble Code Failure Type";
BA_ "SignalType" SG_ 1128 DTCI_ECM_CnfrmdDTC "ENM";
BA_ "SignalLongName" SG_ 1128 DTCI_ECM_CnfrmdDTC "Diagnostic Trouble Code Information Extended - ECM : Confirmed DTC";
BA_ "SignalType" SG_ 1128 DTCI_ECM_DTCFaultType "ENM";
BA_ "SignalLongName" SG_ 1128 DTCI_ECM_DTCFaultType "Diagnostic Trouble Code Information Extended - ECM : Diagnostic Trouble Code Fault Type";
BA_ "SignalLongName" SG_ 1128 DTCI_ECM_DTCNumber "Diagnostic Trouble Code Information Extended - ECM : Diagnostic Trouble Code Number";
BA_ "SignalLongName" SG_ 1128 DTCI_ECM_DTCSource "Diagnostic Trouble Code Information Extended - ECM : Diagnostic Trouble Code Source";
BA_ "SignalType" SG_ 1128 DTCI_ECM_TstNCmpltdOpCyc "ENM";
BA_ "SignalLongName" SG_ 1128 DTCI_ECM_TstNCmpltdOpCyc "Diagnostic Trouble Code Information Extended - ECM : Test Not Completed This Operation Cycle";
BA_ "SignalType" SG_ 1128 DTCI_ECM_TstNCmpltdLstClr "ENM";
BA_ "SignalLongName" SG_ 1128 DTCI_ECM_TstNCmpltdLstClr "Diagnostic Trouble Code Information Extended - ECM : Test Not Completed Since Last Clear";
BA_ "SignalType" SG_ 1128 DTCI_ECM_TstFldOpCyc "ENM";
BA_ "SignalLongName" SG_ 1128 DTCI_ECM_TstFldOpCyc "Diagnostic Trouble Code Information Extended - ECM : Test Failed This Operation Cycle";
BA_ "SignalType" SG_ 1128 DTCI_ECM_TstFldLstClr "ENM";
BA_ "SignalLongName" SG_ 1128 DTCI_ECM_TstFldLstClr "Diagnostic Trouble Code Information Extended - ECM : Test Failed Since Last Clear";
BA_ "SignalType" SG_ 1128 DTCI_ECM_TstFld "ENM";
BA_ "SignalLongName" SG_ 1128 DTCI_ECM_TstFld "Diagnostic Trouble Code Information Extended - ECM : Test Failed";
BA_ "SignalType" SG_ 1128 DTCI_ECM_PndngDTC "ENM";
BA_ "SignalLongName" SG_ 1128 DTCI_ECM_PndngDTC "Diagnostic Trouble Code Information Extended - ECM : Pending DTC";
BA_ "SignalType" SG_ 1128 DTCI_ECM_DTCTriggered "ENM";
BA_ "SignalLongName" SG_ 1128 DTCI_ECM_DTCTriggered "Diagnostic Trouble Code Information Extended - ECM : Diagnostic Trouble Code Triggered";
BA_ "SignalType" SG_ 1128 DTCI_ECM_WrnIndTrggrd "ENM";
BA_ "SignalLongName" SG_ 1128 DTCI_ECM_WrnIndTrggrd "Diagnostic Trouble Code Information Extended - ECM : Warning Indicator Triggered";
BA_ "SignalType" SG_ 1128 DTCI_ECM_WrnIndRqd "ENM";
BA_ "SignalLongName" SG_ 1128 DTCI_ECM_WrnIndRqd "Diagnostic Trouble Code Information Extended - ECM : Warning Indicator Requested";
BA_ "SignalLongName" SG_ 1428 DTCI_ECP_E_DTCFailType "Diagnostic Trouble Code Information Extended - ECP_E : Diagnostic Trouble Code Failure Type";
BA_ "SignalType" SG_ 1428 DTCI_ECP_E_CnfrmdDTC "ENM";
BA_ "SignalLongName" SG_ 1428 DTCI_ECP_E_CnfrmdDTC "Diagnostic Trouble Code Information Extended - ECP_E : Confirmed DTC";
BA_ "SignalType" SG_ 1428 DTCI_ECP_E_DTCFaultType "ENM";
BA_ "SignalLongName" SG_ 1428 DTCI_ECP_E_DTCFaultType "Diagnostic Trouble Code Information Extended - ECP_E : Diagnostic Trouble Code Fault Type";
BA_ "SignalLongName" SG_ 1428 DTCI_ECP_E_DTCNumber "Diagnostic Trouble Code Information Extended - ECP_E : Diagnostic Trouble Code Number";
BA_ "SignalLongName" SG_ 1428 DTCI_ECP_E_DTCSource "Diagnostic Trouble Code Information Extended - ECP_E : Diagnostic Trouble Code Source";
BA_ "SignalType" SG_ 1428 DTCI_ECP_E_TstNCmpltdOpCyc "ENM";
BA_ "SignalLongName" SG_ 1428 DTCI_ECP_E_TstNCmpltdOpCyc "Diagnostic Trouble Code Information Extended - ECP_E : Test Not Completed This Operation Cycle";
BA_ "SignalType" SG_ 1428 DTCI_ECP_E_TstNCmpltdLstClr "ENM";
BA_ "SignalLongName" SG_ 1428 DTCI_ECP_E_TstNCmpltdLstClr "Diagnostic Trouble Code Information Extended - ECP_E : Test Not Completed Since Last Clear";
BA_ "SignalType" SG_ 1428 DTCI_ECP_E_TstFldOpCyc "ENM";
BA_ "SignalLongName" SG_ 1428 DTCI_ECP_E_TstFldOpCyc "Diagnostic Trouble Code Information Extended - ECP_E : Test Failed This Operation Cycle";
BA_ "SignalType" SG_ 1428 DTCI_ECP_E_TstFldLstClr "ENM";
BA_ "SignalLongName" SG_ 1428 DTCI_ECP_E_TstFldLstClr "Diagnostic Trouble Code Information Extended - ECP_E : Test Failed Since Last Clear";
BA_ "SignalType" SG_ 1428 DTCI_ECP_E_TstFld "ENM";
BA_ "SignalLongName" SG_ 1428 DTCI_ECP_E_TstFld "Diagnostic Trouble Code Information Extended - ECP_E : Test Failed";
BA_ "SignalType" SG_ 1428 DTCI_ECP_E_PndngDTC "ENM";
BA_ "SignalLongName" SG_ 1428 DTCI_ECP_E_PndngDTC "Diagnostic Trouble Code Information Extended - ECP_E : Pending DTC";
BA_ "SignalType" SG_ 1428 DTCI_ECP_E_DTCTriggered "ENM";
BA_ "SignalLongName" SG_ 1428 DTCI_ECP_E_DTCTriggered "Diagnostic Trouble Code Information Extended - ECP_E : Diagnostic Trouble Code Triggered";
BA_ "SignalType" SG_ 1428 DTCI_ECP_E_WrnIndTrggrd "ENM";
BA_ "SignalLongName" SG_ 1428 DTCI_ECP_E_WrnIndTrggrd "Diagnostic Trouble Code Information Extended - ECP_E : Warning Indicator Triggered";
BA_ "SignalType" SG_ 1428 DTCI_ECP_E_WrnIndRqd "ENM";
BA_ "SignalLongName" SG_ 1428 DTCI_ECP_E_WrnIndRqd "Diagnostic Trouble Code Information Extended - ECP_E : Warning Indicator Requested";
BA_ "SignalLongName" SG_ 1412 DTCI_ECP_MC_DTCFailType "Diagnostic Trouble Code Information Extended - ECP_MC : Diagnostic Trouble Code Failure Type";
BA_ "SignalType" SG_ 1412 DTCI_ECP_MC_CnfrmdDTC "ENM";
BA_ "SignalLongName" SG_ 1412 DTCI_ECP_MC_CnfrmdDTC "Diagnostic Trouble Code Information Extended - ECP_MC : Confirmed DTC";
BA_ "SignalType" SG_ 1412 DTCI_ECP_MC_DTCFaultType "ENM";
BA_ "SignalLongName" SG_ 1412 DTCI_ECP_MC_DTCFaultType "Diagnostic Trouble Code Information Extended - ECP_MC : Diagnostic Trouble Code Fault Type";
BA_ "SignalLongName" SG_ 1412 DTCI_ECP_MC_DTCNumber "Diagnostic Trouble Code Information Extended - ECP_MC : Diagnostic Trouble Code Number";
BA_ "SignalLongName" SG_ 1412 DTCI_ECP_MC_DTCSource "Diagnostic Trouble Code Information Extended - ECP_MC : Diagnostic Trouble Code Source";
BA_ "SignalType" SG_ 1412 DTCI_ECP_MC_TstNCmpltdOpCyc "ENM";
BA_ "SignalLongName" SG_ 1412 DTCI_ECP_MC_TstNCmpltdOpCyc "Diagnostic Trouble Code Information Extended - ECP_MC : Test Not Completed This Operation Cycle";
BA_ "SignalType" SG_ 1412 DTCI_ECP_MC_TstNCmpltdLstClr "ENM";
BA_ "SignalLongName" SG_ 1412 DTCI_ECP_MC_TstNCmpltdLstClr "Diagnostic Trouble Code Information Extended - ECP_MC : Test Not Completed Since Last Clear";
BA_ "SignalType" SG_ 1412 DTCI_ECP_MC_TstFldOpCyc "ENM";
BA_ "SignalLongName" SG_ 1412 DTCI_ECP_MC_TstFldOpCyc "Diagnostic Trouble Code Information Extended - ECP_MC : Test Failed This Operation Cycle";
BA_ "SignalType" SG_ 1412 DTCI_ECP_MC_TstFldLstClr "ENM";
BA_ "SignalLongName" SG_ 1412 DTCI_ECP_MC_TstFldLstClr "Diagnostic Trouble Code Information Extended - ECP_MC : Test Failed Since Last Clear";
BA_ "SignalType" SG_ 1412 DTCI_ECP_MC_TstFld "ENM";
BA_ "SignalLongName" SG_ 1412 DTCI_ECP_MC_TstFld "Diagnostic Trouble Code Information Extended - ECP_MC : Test Failed";
BA_ "SignalType" SG_ 1412 DTCI_ECP_MC_PndngDTC "ENM";
BA_ "SignalLongName" SG_ 1412 DTCI_ECP_MC_PndngDTC "Diagnostic Trouble Code Information Extended - ECP_MC : Pending DTC";
BA_ "SignalType" SG_ 1412 DTCI_ECP_MC_DTCTriggered "ENM";
BA_ "SignalLongName" SG_ 1412 DTCI_ECP_MC_DTCTriggered "Diagnostic Trouble Code Information Extended - ECP_MC : Diagnostic Trouble Code Triggered";
BA_ "SignalType" SG_ 1412 DTCI_ECP_MC_WrnIndTrggrd "ENM";
BA_ "SignalLongName" SG_ 1412 DTCI_ECP_MC_WrnIndTrggrd "Diagnostic Trouble Code Information Extended - ECP_MC : Warning Indicator Triggered";
BA_ "SignalType" SG_ 1412 DTCI_ECP_MC_WrnIndRqd "ENM";
BA_ "SignalLongName" SG_ 1412 DTCI_ECP_MC_WrnIndRqd "Diagnostic Trouble Code Information Extended - ECP_MC : Warning Indicator Requested";
BA_ "SignalLongName" SG_ 1129 DTCI_ECP_X1_DTCFailType "Diagnostic Trouble Code Information Extended - ECP_X1 : Diagnostic Trouble Code Failure Type";
BA_ "SignalType" SG_ 1129 DTCI_ECP_X1_CnfrmdDTC "ENM";
BA_ "SignalLongName" SG_ 1129 DTCI_ECP_X1_CnfrmdDTC "Diagnostic Trouble Code Information Extended - ECP_X1 : Confirmed DTC";
BA_ "SignalType" SG_ 1129 DTCI_ECP_X1_DTCFaultType "ENM";
BA_ "SignalLongName" SG_ 1129 DTCI_ECP_X1_DTCFaultType "Diagnostic Trouble Code Information Extended - ECP_X1 : Diagnostic Trouble Code Fault Type";
BA_ "SignalLongName" SG_ 1129 DTCI_ECP_X1_DTCNumber "Diagnostic Trouble Code Information Extended - ECP_X1 : Diagnostic Trouble Code Number";
BA_ "SignalLongName" SG_ 1129 DTCI_ECP_X1_DTCSource "Diagnostic Trouble Code Information Extended - ECP_X1 : Diagnostic Trouble Code Source";
BA_ "SignalType" SG_ 1129 DTCI_ECP_X1_TstNCmpltdOpCyc "ENM";
BA_ "SignalLongName" SG_ 1129 DTCI_ECP_X1_TstNCmpltdOpCyc "Diagnostic Trouble Code Information Extended - ECP_X1 : Test Not Completed This Operation Cycle";
BA_ "SignalType" SG_ 1129 DTCI_ECP_X1_TstNCmpltdLstClr "ENM";
BA_ "SignalLongName" SG_ 1129 DTCI_ECP_X1_TstNCmpltdLstClr "Diagnostic Trouble Code Information Extended - ECP_X1 : Test Not Completed Since Last Clear";
BA_ "SignalType" SG_ 1129 DTCI_ECP_X1_TstFldOpCyc "ENM";
BA_ "SignalLongName" SG_ 1129 DTCI_ECP_X1_TstFldOpCyc "Diagnostic Trouble Code Information Extended - ECP_X1 : Test Failed This Operation Cycle";
BA_ "SignalType" SG_ 1129 DTCI_ECP_X1_TstFldLstClr "ENM";
BA_ "SignalLongName" SG_ 1129 DTCI_ECP_X1_TstFldLstClr "Diagnostic Trouble Code Information Extended - ECP_X1 : Test Failed Since Last Clear";
BA_ "SignalType" SG_ 1129 DTCI_ECP_X1_TstFld "ENM";
BA_ "SignalLongName" SG_ 1129 DTCI_ECP_X1_TstFld "Diagnostic Trouble Code Information Extended - ECP_X1 : Test Failed";
BA_ "SignalType" SG_ 1129 DTCI_ECP_X1_PndngDTC "ENM";
BA_ "SignalLongName" SG_ 1129 DTCI_ECP_X1_PndngDTC "Diagnostic Trouble Code Information Extended - ECP_X1 : Pending DTC";
BA_ "SignalType" SG_ 1129 DTCI_ECP_X1_DTCTriggered "ENM";
BA_ "SignalLongName" SG_ 1129 DTCI_ECP_X1_DTCTriggered "Diagnostic Trouble Code Information Extended - ECP_X1 : Diagnostic Trouble Code Triggered";
BA_ "SignalType" SG_ 1129 DTCI_ECP_X1_WrnIndTrggrd "ENM";
BA_ "SignalLongName" SG_ 1129 DTCI_ECP_X1_WrnIndTrggrd "Diagnostic Trouble Code Information Extended - ECP_X1 : Warning Indicator Triggered";
BA_ "SignalType" SG_ 1129 DTCI_ECP_X1_WrnIndRqd "ENM";
BA_ "SignalLongName" SG_ 1129 DTCI_ECP_X1_WrnIndRqd "Diagnostic Trouble Code Information Extended - ECP_X1 : Warning Indicator Requested";
BA_ "SignalLongName" SG_ 1131 DTCI_ELM_DTCFailType "Diagnostic Trouble Code Information Extended - ELM : Diagnostic Trouble Code Failure Type";
BA_ "SignalType" SG_ 1131 DTCI_ELM_CnfrmdDTC "ENM";
BA_ "SignalLongName" SG_ 1131 DTCI_ELM_CnfrmdDTC "Diagnostic Trouble Code Information Extended - ELM : Confirmed DTC";
BA_ "SignalType" SG_ 1131 DTCI_ELM_DTCFaultType "ENM";
BA_ "SignalLongName" SG_ 1131 DTCI_ELM_DTCFaultType "Diagnostic Trouble Code Information Extended - ELM : Diagnostic Trouble Code Fault Type";
BA_ "SignalLongName" SG_ 1131 DTCI_ELM_DTCNumber "Diagnostic Trouble Code Information Extended - ELM : Diagnostic Trouble Code Number";
BA_ "SignalLongName" SG_ 1131 DTCI_ELM_DTCSource "Diagnostic Trouble Code Information Extended - ELM : Diagnostic Trouble Code Source";
BA_ "SignalType" SG_ 1131 DTCI_ELM_TstNCmpltdOpCyc "ENM";
BA_ "SignalLongName" SG_ 1131 DTCI_ELM_TstNCmpltdOpCyc "Diagnostic Trouble Code Information Extended - ELM : Test Not Completed This Operation Cycle";
BA_ "SignalType" SG_ 1131 DTCI_ELM_TstNCmpltdLstClr "ENM";
BA_ "SignalLongName" SG_ 1131 DTCI_ELM_TstNCmpltdLstClr "Diagnostic Trouble Code Information Extended - ELM : Test Not Completed Since Last Clear";
BA_ "SignalType" SG_ 1131 DTCI_ELM_TstFldOpCyc "ENM";
BA_ "SignalLongName" SG_ 1131 DTCI_ELM_TstFldOpCyc "Diagnostic Trouble Code Information Extended - ELM : Test Failed This Operation Cycle";
BA_ "SignalType" SG_ 1131 DTCI_ELM_TstFldLstClr "ENM";
BA_ "SignalLongName" SG_ 1131 DTCI_ELM_TstFldLstClr "Diagnostic Trouble Code Information Extended - ELM : Test Failed Since Last Clear";
BA_ "SignalType" SG_ 1131 DTCI_ELM_TstFld "ENM";
BA_ "SignalLongName" SG_ 1131 DTCI_ELM_TstFld "Diagnostic Trouble Code Information Extended - ELM : Test Failed";
BA_ "SignalType" SG_ 1131 DTCI_ELM_PndngDTC "ENM";
BA_ "SignalLongName" SG_ 1131 DTCI_ELM_PndngDTC "Diagnostic Trouble Code Information Extended - ELM : Pending DTC";
BA_ "SignalType" SG_ 1131 DTCI_ELM_DTCTriggered "ENM";
BA_ "SignalLongName" SG_ 1131 DTCI_ELM_DTCTriggered "Diagnostic Trouble Code Information Extended - ELM : Diagnostic Trouble Code Triggered";
BA_ "SignalType" SG_ 1131 DTCI_ELM_WrnIndTrggrd "ENM";
BA_ "SignalLongName" SG_ 1131 DTCI_ELM_WrnIndTrggrd "Diagnostic Trouble Code Information Extended - ELM : Warning Indicator Triggered";
BA_ "SignalType" SG_ 1131 DTCI_ELM_WrnIndRqd "ENM";
BA_ "SignalLongName" SG_ 1131 DTCI_ELM_WrnIndRqd "Diagnostic Trouble Code Information Extended - ELM : Warning Indicator Requested";
BA_ "SignalLongName" SG_ 1292 DTCI_EOCM_HCP1_DTCFailType "Diagnostic Trouble Code Information Extended - EOCM_HCP1 : Diagnostic Trouble Code Failure Type";
BA_ "SignalType" SG_ 1292 DTCI_EOCM_HCP1_CnfrmdDTC "ENM";
BA_ "SignalLongName" SG_ 1292 DTCI_EOCM_HCP1_CnfrmdDTC "Diagnostic Trouble Code Information Extended - EOCM_HCP1 : Confirmed DTC";
BA_ "SignalType" SG_ 1292 DTCI_EOCM_HCP1_DTCFaultType "ENM";
BA_ "SignalLongName" SG_ 1292 DTCI_EOCM_HCP1_DTCFaultType "Diagnostic Trouble Code Information Extended - EOCM_HCP1 : Diagnostic Trouble Code Fault Type";
BA_ "SignalLongName" SG_ 1292 DTCI_EOCM_HCP1_DTCNumber "Diagnostic Trouble Code Information Extended - EOCM_HCP1 : Diagnostic Trouble Code Number";
BA_ "SignalLongName" SG_ 1292 DTCI_EOCM_HCP1_DTCSource "Diagnostic Trouble Code Information Extended - EOCM_HCP1 : Diagnostic Trouble Code Source";
BA_ "SignalType" SG_ 1292 DTCI_EOCM_HCP1_TstNCmpltdOpCyc "ENM";
BA_ "SignalLongName" SG_ 1292 DTCI_EOCM_HCP1_TstNCmpltdOpCyc "Diagnostic Trouble Code Information Extended - EOCM_HCP1 : Test Not Completed This Operation Cycle";
BA_ "SignalType" SG_ 1292 DTCI_EOCM_HCP1_TstNCmpltdLstClr "ENM";
BA_ "SignalLongName" SG_ 1292 DTCI_EOCM_HCP1_TstNCmpltdLstClr "Diagnostic Trouble Code Information Extended - EOCM_HCP1 : Test Not Completed Since Last Clear";
BA_ "SignalType" SG_ 1292 DTCI_EOCM_HCP1_TstFldOpCyc "ENM";
BA_ "SignalLongName" SG_ 1292 DTCI_EOCM_HCP1_TstFldOpCyc "Diagnostic Trouble Code Information Extended - EOCM_HCP1 : Test Failed This Operation Cycle";
BA_ "SignalType" SG_ 1292 DTCI_EOCM_HCP1_TstFldLstClr "ENM";
BA_ "SignalLongName" SG_ 1292 DTCI_EOCM_HCP1_TstFldLstClr "Diagnostic Trouble Code Information Extended - EOCM_HCP1 : Test Failed Since Last Clear";
BA_ "SignalType" SG_ 1292 DTCI_EOCM_HCP1_TstFld "ENM";
BA_ "SignalLongName" SG_ 1292 DTCI_EOCM_HCP1_TstFld "Diagnostic Trouble Code Information Extended - EOCM_HCP1 : Test Failed";
BA_ "SignalType" SG_ 1292 DTCI_EOCM_HCP1_PndngDTC "ENM";
BA_ "SignalLongName" SG_ 1292 DTCI_EOCM_HCP1_PndngDTC "Diagnostic Trouble Code Information Extended - EOCM_HCP1 : Pending DTC";
BA_ "SignalType" SG_ 1292 DTCI_EOCM_HCP1_DTCTriggered "ENM";
BA_ "SignalLongName" SG_ 1292 DTCI_EOCM_HCP1_DTCTriggered "Diagnostic Trouble Code Information Extended - EOCM_HCP1 : Diagnostic Trouble Code Triggered";
BA_ "SignalType" SG_ 1292 DTCI_EOCM_HCP1_WrnIndTrggrd "ENM";
BA_ "SignalLongName" SG_ 1292 DTCI_EOCM_HCP1_WrnIndTrggrd "Diagnostic Trouble Code Information Extended - EOCM_HCP1 : Warning Indicator Triggered";
BA_ "SignalType" SG_ 1292 DTCI_EOCM_HCP1_WrnIndRqd "ENM";
BA_ "SignalLongName" SG_ 1292 DTCI_EOCM_HCP1_WrnIndRqd "Diagnostic Trouble Code Information Extended - EOCM_HCP1 : Warning Indicator Requested";
BA_ "SignalLongName" SG_ 1293 DTCI_EOCM_HCP2_DTCFailType "Diagnostic Trouble Code Information Extended - EOCM_HCP2 : Diagnostic Trouble Code Failure Type";
BA_ "SignalType" SG_ 1293 DTCI_EOCM_HCP2_CnfrmdDTC "ENM";
BA_ "SignalLongName" SG_ 1293 DTCI_EOCM_HCP2_CnfrmdDTC "Diagnostic Trouble Code Information Extended - EOCM_HCP2 : Confirmed DTC";
BA_ "SignalType" SG_ 1293 DTCI_EOCM_HCP2_DTCFaultType "ENM";
BA_ "SignalLongName" SG_ 1293 DTCI_EOCM_HCP2_DTCFaultType "Diagnostic Trouble Code Information Extended - EOCM_HCP2 : Diagnostic Trouble Code Fault Type";
BA_ "SignalLongName" SG_ 1293 DTCI_EOCM_HCP2_DTCNumber "Diagnostic Trouble Code Information Extended - EOCM_HCP2 : Diagnostic Trouble Code Number";
BA_ "SignalLongName" SG_ 1293 DTCI_EOCM_HCP2_DTCSource "Diagnostic Trouble Code Information Extended - EOCM_HCP2 : Diagnostic Trouble Code Source";
BA_ "SignalType" SG_ 1293 DTCI_EOCM_HCP2_TstNCmpltdOpCyc "ENM";
BA_ "SignalLongName" SG_ 1293 DTCI_EOCM_HCP2_TstNCmpltdOpCyc "Diagnostic Trouble Code Information Extended - EOCM_HCP2 : Test Not Completed This Operation Cycle";
BA_ "SignalType" SG_ 1293 DTCI_EOCM_HCP2_TstNCmpltdLstClr "ENM";
BA_ "SignalLongName" SG_ 1293 DTCI_EOCM_HCP2_TstNCmpltdLstClr "Diagnostic Trouble Code Information Extended - EOCM_HCP2 : Test Not Completed Since Last Clear";
BA_ "SignalType" SG_ 1293 DTCI_EOCM_HCP2_TstFldOpCyc "ENM";
BA_ "SignalLongName" SG_ 1293 DTCI_EOCM_HCP2_TstFldOpCyc "Diagnostic Trouble Code Information Extended - EOCM_HCP2 : Test Failed This Operation Cycle";
BA_ "SignalType" SG_ 1293 DTCI_EOCM_HCP2_TstFldLstClr "ENM";
BA_ "SignalLongName" SG_ 1293 DTCI_EOCM_HCP2_TstFldLstClr "Diagnostic Trouble Code Information Extended - EOCM_HCP2 : Test Failed Since Last Clear";
BA_ "SignalType" SG_ 1293 DTCI_EOCM_HCP2_TstFld "ENM";
BA_ "SignalLongName" SG_ 1293 DTCI_EOCM_HCP2_TstFld "Diagnostic Trouble Code Information Extended - EOCM_HCP2 : Test Failed";
BA_ "SignalType" SG_ 1293 DTCI_EOCM_HCP2_PndngDTC "ENM";
BA_ "SignalLongName" SG_ 1293 DTCI_EOCM_HCP2_PndngDTC "Diagnostic Trouble Code Information Extended - EOCM_HCP2 : Pending DTC";
BA_ "SignalType" SG_ 1293 DTCI_EOCM_HCP2_DTCTriggered "ENM";
BA_ "SignalLongName" SG_ 1293 DTCI_EOCM_HCP2_DTCTriggered "Diagnostic Trouble Code Information Extended - EOCM_HCP2 : Diagnostic Trouble Code Triggered";
BA_ "SignalType" SG_ 1293 DTCI_EOCM_HCP2_WrnIndTrggrd "ENM";
BA_ "SignalLongName" SG_ 1293 DTCI_EOCM_HCP2_WrnIndTrggrd "Diagnostic Trouble Code Information Extended - EOCM_HCP2 : Warning Indicator Triggered";
BA_ "SignalType" SG_ 1293 DTCI_EOCM_HCP2_WrnIndRqd "ENM";
BA_ "SignalLongName" SG_ 1293 DTCI_EOCM_HCP2_WrnIndRqd "Diagnostic Trouble Code Information Extended - EOCM_HCP2 : Warning Indicator Requested";
BA_ "SignalLongName" SG_ 1132 DTCI_EOCM_DTCFailType "Diagnostic Trouble Code Information Extended - EOCM : Diagnostic Trouble Code Failure Type";
BA_ "SignalType" SG_ 1132 DTCI_EOCM_CnfrmdDTC "ENM";
BA_ "SignalLongName" SG_ 1132 DTCI_EOCM_CnfrmdDTC "Diagnostic Trouble Code Information Extended - EOCM : Confirmed DTC";
BA_ "SignalType" SG_ 1132 DTCI_EOCM_DTCFaultType "ENM";
BA_ "SignalLongName" SG_ 1132 DTCI_EOCM_DTCFaultType "Diagnostic Trouble Code Information Extended - EOCM : Diagnostic Trouble Code Fault Type";
BA_ "SignalLongName" SG_ 1132 DTCI_EOCM_DTCNumber "Diagnostic Trouble Code Information Extended - EOCM : Diagnostic Trouble Code Number";
BA_ "SignalLongName" SG_ 1132 DTCI_EOCM_DTCSource "Diagnostic Trouble Code Information Extended - EOCM : Diagnostic Trouble Code Source";
BA_ "SignalType" SG_ 1132 DTCI_EOCM_TstNCmpltdOpCyc "ENM";
BA_ "SignalLongName" SG_ 1132 DTCI_EOCM_TstNCmpltdOpCyc "Diagnostic Trouble Code Information Extended - EOCM : Test Not Completed This Operation Cycle";
BA_ "SignalType" SG_ 1132 DTCI_EOCM_TstNCmpltdLstClr "ENM";
BA_ "SignalLongName" SG_ 1132 DTCI_EOCM_TstNCmpltdLstClr "Diagnostic Trouble Code Information Extended - EOCM : Test Not Completed Since Last Clear";
BA_ "SignalType" SG_ 1132 DTCI_EOCM_TstFldOpCyc "ENM";
BA_ "SignalLongName" SG_ 1132 DTCI_EOCM_TstFldOpCyc "Diagnostic Trouble Code Information Extended - EOCM : Test Failed This Operation Cycle";
BA_ "SignalType" SG_ 1132 DTCI_EOCM_TstFldLstClr "ENM";
BA_ "SignalLongName" SG_ 1132 DTCI_EOCM_TstFldLstClr "Diagnostic Trouble Code Information Extended - EOCM : Test Failed Since Last Clear";
BA_ "SignalType" SG_ 1132 DTCI_EOCM_TstFld "ENM";
BA_ "SignalLongName" SG_ 1132 DTCI_EOCM_TstFld "Diagnostic Trouble Code Information Extended - EOCM : Test Failed";
BA_ "SignalType" SG_ 1132 DTCI_EOCM_PndngDTC "ENM";
BA_ "SignalLongName" SG_ 1132 DTCI_EOCM_PndngDTC "Diagnostic Trouble Code Information Extended - EOCM : Pending DTC";
BA_ "SignalType" SG_ 1132 DTCI_EOCM_DTCTriggered "ENM";
BA_ "SignalLongName" SG_ 1132 DTCI_EOCM_DTCTriggered "Diagnostic Trouble Code Information Extended - EOCM : Diagnostic Trouble Code Triggered";
BA_ "SignalType" SG_ 1132 DTCI_EOCM_WrnIndTrggrd "ENM";
BA_ "SignalLongName" SG_ 1132 DTCI_EOCM_WrnIndTrggrd "Diagnostic Trouble Code Information Extended - EOCM : Warning Indicator Triggered";
BA_ "SignalType" SG_ 1132 DTCI_EOCM_WrnIndRqd "ENM";
BA_ "SignalLongName" SG_ 1132 DTCI_EOCM_WrnIndRqd "Diagnostic Trouble Code Information Extended - EOCM : Warning Indicator Requested";
BA_ "SignalLongName" SG_ 1133 DTCI_EPS_DTCFailType "Diagnostic Trouble Code Information Extended - EPS : Diagnostic Trouble Code Failure Type";
BA_ "SignalType" SG_ 1133 DTCI_EPS_CnfrmdDTC "ENM";
BA_ "SignalLongName" SG_ 1133 DTCI_EPS_CnfrmdDTC "Diagnostic Trouble Code Information Extended - EPS : Confirmed DTC";
BA_ "SignalType" SG_ 1133 DTCI_EPS_DTCFaultType "ENM";
BA_ "SignalLongName" SG_ 1133 DTCI_EPS_DTCFaultType "Diagnostic Trouble Code Information Extended - EPS : Diagnostic Trouble Code Fault Type";
BA_ "SignalLongName" SG_ 1133 DTCI_EPS_DTCNumber "Diagnostic Trouble Code Information Extended - EPS : Diagnostic Trouble Code Number";
BA_ "SignalLongName" SG_ 1133 DTCI_EPS_DTCSource "Diagnostic Trouble Code Information Extended - EPS : Diagnostic Trouble Code Source";
BA_ "SignalType" SG_ 1133 DTCI_EPS_TstNCmpltdOpCyc "ENM";
BA_ "SignalLongName" SG_ 1133 DTCI_EPS_TstNCmpltdOpCyc "Diagnostic Trouble Code Information Extended - EPS : Test Not Completed This Operation Cycle";
BA_ "SignalType" SG_ 1133 DTCI_EPS_TstNCmpltdLstClr "ENM";
BA_ "SignalLongName" SG_ 1133 DTCI_EPS_TstNCmpltdLstClr "Diagnostic Trouble Code Information Extended - EPS : Test Not Completed Since Last Clear";
BA_ "SignalType" SG_ 1133 DTCI_EPS_TstFldOpCyc "ENM";
BA_ "SignalLongName" SG_ 1133 DTCI_EPS_TstFldOpCyc "Diagnostic Trouble Code Information Extended - EPS : Test Failed This Operation Cycle";
BA_ "SignalType" SG_ 1133 DTCI_EPS_TstFldLstClr "ENM";
BA_ "SignalLongName" SG_ 1133 DTCI_EPS_TstFldLstClr "Diagnostic Trouble Code Information Extended - EPS : Test Failed Since Last Clear";
BA_ "SignalType" SG_ 1133 DTCI_EPS_TstFld "ENM";
BA_ "SignalLongName" SG_ 1133 DTCI_EPS_TstFld "Diagnostic Trouble Code Information Extended - EPS : Test Failed";
BA_ "SignalType" SG_ 1133 DTCI_EPS_PndngDTC "ENM";
BA_ "SignalLongName" SG_ 1133 DTCI_EPS_PndngDTC "Diagnostic Trouble Code Information Extended - EPS : Pending DTC";
BA_ "SignalType" SG_ 1133 DTCI_EPS_DTCTriggered "ENM";
BA_ "SignalLongName" SG_ 1133 DTCI_EPS_DTCTriggered "Diagnostic Trouble Code Information Extended - EPS : Diagnostic Trouble Code Triggered";
BA_ "SignalType" SG_ 1133 DTCI_EPS_WrnIndTrggrd "ENM";
BA_ "SignalLongName" SG_ 1133 DTCI_EPS_WrnIndTrggrd "Diagnostic Trouble Code Information Extended - EPS : Warning Indicator Triggered";
BA_ "SignalType" SG_ 1133 DTCI_EPS_WrnIndRqd "ENM";
BA_ "SignalLongName" SG_ 1133 DTCI_EPS_WrnIndRqd "Diagnostic Trouble Code Information Extended - EPS : Warning Indicator Requested";
BA_ "SignalLongName" SG_ 1135 DTCI_FCM_LC_DTCFailType "Diagnostic Trouble Code Information Extended - FCM_LC : Diagnostic Trouble Code Failure Type";
BA_ "SignalType" SG_ 1135 DTCI_FCM_LC_CnfrmdDTC "ENM";
BA_ "SignalLongName" SG_ 1135 DTCI_FCM_LC_CnfrmdDTC "Diagnostic Trouble Code Information Extended - FCM_LC : Confirmed DTC";
BA_ "SignalType" SG_ 1135 DTCI_FCM_LC_DTCFaultType "ENM";
BA_ "SignalLongName" SG_ 1135 DTCI_FCM_LC_DTCFaultType "Diagnostic Trouble Code Information Extended - FCM_LC : Diagnostic Trouble Code Fault Type";
BA_ "SignalLongName" SG_ 1135 DTCI_FCM_LC_DTCNumber "Diagnostic Trouble Code Information Extended - FCM_LC : Diagnostic Trouble Code Number";
BA_ "SignalLongName" SG_ 1135 DTCI_FCM_LC_DTCSource "Diagnostic Trouble Code Information Extended - FCM_LC : Diagnostic Trouble Code Source";
BA_ "SignalType" SG_ 1135 DTCI_FCM_LC_TstNCmpltdOpCyc "ENM";
BA_ "SignalLongName" SG_ 1135 DTCI_FCM_LC_TstNCmpltdOpCyc "Diagnostic Trouble Code Information Extended - FCM_LC : Test Not Completed This Operation Cycle";
BA_ "SignalType" SG_ 1135 DTCI_FCM_LC_TstNCmpltdLstClr "ENM";
BA_ "SignalLongName" SG_ 1135 DTCI_FCM_LC_TstNCmpltdLstClr "Diagnostic Trouble Code Information Extended - FCM_LC : Test Not Completed Since Last Clear";
BA_ "SignalType" SG_ 1135 DTCI_FCM_LC_TstFldOpCyc "ENM";
BA_ "SignalLongName" SG_ 1135 DTCI_FCM_LC_TstFldOpCyc "Diagnostic Trouble Code Information Extended - FCM_LC : Test Failed This Operation Cycle";
BA_ "SignalType" SG_ 1135 DTCI_FCM_LC_TstFldLstClr "ENM";
BA_ "SignalLongName" SG_ 1135 DTCI_FCM_LC_TstFldLstClr "Diagnostic Trouble Code Information Extended - FCM_LC : Test Failed Since Last Clear";
BA_ "SignalType" SG_ 1135 DTCI_FCM_LC_TstFld "ENM";
BA_ "SignalLongName" SG_ 1135 DTCI_FCM_LC_TstFld "Diagnostic Trouble Code Information Extended - FCM_LC : Test Failed";
BA_ "SignalType" SG_ 1135 DTCI_FCM_LC_PndngDTC "ENM";
BA_ "SignalLongName" SG_ 1135 DTCI_FCM_LC_PndngDTC "Diagnostic Trouble Code Information Extended - FCM_LC : Pending DTC";
BA_ "SignalType" SG_ 1135 DTCI_FCM_LC_DTCTriggered "ENM";
BA_ "SignalLongName" SG_ 1135 DTCI_FCM_LC_DTCTriggered "Diagnostic Trouble Code Information Extended - FCM_LC : Diagnostic Trouble Code Triggered";
BA_ "SignalType" SG_ 1135 DTCI_FCM_LC_WrnIndTrggrd "ENM";
BA_ "SignalLongName" SG_ 1135 DTCI_FCM_LC_WrnIndTrggrd "Diagnostic Trouble Code Information Extended - FCM_LC : Warning Indicator Triggered";
BA_ "SignalType" SG_ 1135 DTCI_FCM_LC_WrnIndRqd "ENM";
BA_ "SignalLongName" SG_ 1135 DTCI_FCM_LC_WrnIndRqd "Diagnostic Trouble Code Information Extended - FCM_LC : Warning Indicator Requested";
BA_ "SignalLongName" SG_ 1134 DTCI_FCM_DTCFailType "Diagnostic Trouble Code Information Extended - FCM : Diagnostic Trouble Code Failure Type";
BA_ "SignalType" SG_ 1134 DTCI_FCM_CnfrmdDTC "ENM";
BA_ "SignalLongName" SG_ 1134 DTCI_FCM_CnfrmdDTC "Diagnostic Trouble Code Information Extended - FCM : Confirmed DTC";
BA_ "SignalType" SG_ 1134 DTCI_FCM_DTCFaultType "ENM";
BA_ "SignalLongName" SG_ 1134 DTCI_FCM_DTCFaultType "Diagnostic Trouble Code Information Extended - FCM : Diagnostic Trouble Code Fault Type";
BA_ "SignalLongName" SG_ 1134 DTCI_FCM_DTCNumber "Diagnostic Trouble Code Information Extended - FCM : Diagnostic Trouble Code Number";
BA_ "SignalLongName" SG_ 1134 DTCI_FCM_DTCSource "Diagnostic Trouble Code Information Extended - FCM : Diagnostic Trouble Code Source";
BA_ "SignalType" SG_ 1134 DTCI_FCM_TstNCmpltdOpCyc "ENM";
BA_ "SignalLongName" SG_ 1134 DTCI_FCM_TstNCmpltdOpCyc "Diagnostic Trouble Code Information Extended - FCM : Test Not Completed This Operation Cycle";
BA_ "SignalType" SG_ 1134 DTCI_FCM_TstNCmpltdLstClr "ENM";
BA_ "SignalLongName" SG_ 1134 DTCI_FCM_TstNCmpltdLstClr "Diagnostic Trouble Code Information Extended - FCM : Test Not Completed Since Last Clear";
BA_ "SignalType" SG_ 1134 DTCI_FCM_TstFldOpCyc "ENM";
BA_ "SignalLongName" SG_ 1134 DTCI_FCM_TstFldOpCyc "Diagnostic Trouble Code Information Extended - FCM : Test Failed This Operation Cycle";
BA_ "SignalType" SG_ 1134 DTCI_FCM_TstFldLstClr "ENM";
BA_ "SignalLongName" SG_ 1134 DTCI_FCM_TstFldLstClr "Diagnostic Trouble Code Information Extended - FCM : Test Failed Since Last Clear";
BA_ "SignalType" SG_ 1134 DTCI_FCM_TstFld "ENM";
BA_ "SignalLongName" SG_ 1134 DTCI_FCM_TstFld "Diagnostic Trouble Code Information Extended - FCM : Test Failed";
BA_ "SignalType" SG_ 1134 DTCI_FCM_PndngDTC "ENM";
BA_ "SignalLongName" SG_ 1134 DTCI_FCM_PndngDTC "Diagnostic Trouble Code Information Extended - FCM : Pending DTC";
BA_ "SignalType" SG_ 1134 DTCI_FCM_DTCTriggered "ENM";
BA_ "SignalLongName" SG_ 1134 DTCI_FCM_DTCTriggered "Diagnostic Trouble Code Information Extended - FCM : Diagnostic Trouble Code Triggered";
BA_ "SignalType" SG_ 1134 DTCI_FCM_WrnIndTrggrd "ENM";
BA_ "SignalLongName" SG_ 1134 DTCI_FCM_WrnIndTrggrd "Diagnostic Trouble Code Information Extended - FCM : Warning Indicator Triggered";
BA_ "SignalType" SG_ 1134 DTCI_FCM_WrnIndRqd "ENM";
BA_ "SignalLongName" SG_ 1134 DTCI_FCM_WrnIndRqd "Diagnostic Trouble Code Information Extended - FCM : Warning Indicator Requested";
BA_ "SignalLongName" SG_ 1406 DTCI_HDLM_DTCFailType "Diagnostic Trouble Code Information Extended - HDLM : Diagnostic Trouble Code Failure Type";
BA_ "SignalType" SG_ 1406 DTCI_HDLM_CnfrmdDTC "ENM";
BA_ "SignalLongName" SG_ 1406 DTCI_HDLM_CnfrmdDTC "Diagnostic Trouble Code Information Extended - HDLM : Confirmed DTC";
BA_ "SignalType" SG_ 1406 DTCI_HDLM_DTCFaultType "ENM";
BA_ "SignalLongName" SG_ 1406 DTCI_HDLM_DTCFaultType "Diagnostic Trouble Code Information Extended - HDLM : Diagnostic Trouble Code Fault Type";
BA_ "SignalLongName" SG_ 1406 DTCI_HDLM_DTCNumber "Diagnostic Trouble Code Information Extended - HDLM : Diagnostic Trouble Code Number";
BA_ "SignalLongName" SG_ 1406 DTCI_HDLM_DTCSource "Diagnostic Trouble Code Information Extended - HDLM : Diagnostic Trouble Code Source";
BA_ "SignalType" SG_ 1406 DTCI_HDLM_TstNCmpltdOpCyc "ENM";
BA_ "SignalLongName" SG_ 1406 DTCI_HDLM_TstNCmpltdOpCyc "Diagnostic Trouble Code Information Extended - HDLM : Test Not Completed This Operation Cycle";
BA_ "SignalType" SG_ 1406 DTCI_HDLM_TstNCmpltdLstClr "ENM";
BA_ "SignalLongName" SG_ 1406 DTCI_HDLM_TstNCmpltdLstClr "Diagnostic Trouble Code Information Extended - HDLM : Test Not Completed Since Last Clear";
BA_ "SignalType" SG_ 1406 DTCI_HDLM_TstFldOpCyc "ENM";
BA_ "SignalLongName" SG_ 1406 DTCI_HDLM_TstFldOpCyc "Diagnostic Trouble Code Information Extended - HDLM : Test Failed This Operation Cycle";
BA_ "SignalType" SG_ 1406 DTCI_HDLM_TstFldLstClr "ENM";
BA_ "SignalLongName" SG_ 1406 DTCI_HDLM_TstFldLstClr "Diagnostic Trouble Code Information Extended - HDLM : Test Failed Since Last Clear";
BA_ "SignalType" SG_ 1406 DTCI_HDLM_TstFld "ENM";
BA_ "SignalLongName" SG_ 1406 DTCI_HDLM_TstFld "Diagnostic Trouble Code Information Extended - HDLM : Test Failed";
BA_ "SignalType" SG_ 1406 DTCI_HDLM_PndngDTC "ENM";
BA_ "SignalLongName" SG_ 1406 DTCI_HDLM_PndngDTC "Diagnostic Trouble Code Information Extended - HDLM : Pending DTC";
BA_ "SignalType" SG_ 1406 DTCI_HDLM_DTCTriggered "ENM";
BA_ "SignalLongName" SG_ 1406 DTCI_HDLM_DTCTriggered "Diagnostic Trouble Code Information Extended - HDLM : Diagnostic Trouble Code Triggered";
BA_ "SignalType" SG_ 1406 DTCI_HDLM_WrnIndTrggrd "ENM";
BA_ "SignalLongName" SG_ 1406 DTCI_HDLM_WrnIndTrggrd "Diagnostic Trouble Code Information Extended - HDLM : Warning Indicator Triggered";
BA_ "SignalType" SG_ 1406 DTCI_HDLM_WrnIndRqd "ENM";
BA_ "SignalLongName" SG_ 1406 DTCI_HDLM_WrnIndRqd "Diagnostic Trouble Code Information Extended - HDLM : Warning Indicator Requested";
BA_ "SignalLongName" SG_ 1286 DTCI_HUD_CAN_DTCFailType "Diagnostic Trouble Code Information Extended - HUD_CAN : Diagnostic Trouble Code Failure Type";
BA_ "SignalType" SG_ 1286 DTCI_HUD_CAN_CnfrmdDTC "ENM";
BA_ "SignalLongName" SG_ 1286 DTCI_HUD_CAN_CnfrmdDTC "Diagnostic Trouble Code Information Extended - HUD_CAN : Confirmed DTC";
BA_ "SignalType" SG_ 1286 DTCI_HUD_CAN_DTCFaultType "ENM";
BA_ "SignalLongName" SG_ 1286 DTCI_HUD_CAN_DTCFaultType "Diagnostic Trouble Code Information Extended - HUD_CAN : Diagnostic Trouble Code Fault Type";
BA_ "SignalLongName" SG_ 1286 DTCI_HUD_CAN_DTCNumber "Diagnostic Trouble Code Information Extended - HUD_CAN : Diagnostic Trouble Code Number";
BA_ "SignalLongName" SG_ 1286 DTCI_HUD_CAN_DTCSource "Diagnostic Trouble Code Information Extended - HUD_CAN : Diagnostic Trouble Code Source";
BA_ "SignalType" SG_ 1286 DTCI_HUD_CAN_TstNCmpltdOpCyc "ENM";
BA_ "SignalLongName" SG_ 1286 DTCI_HUD_CAN_TstNCmpltdOpCyc "Diagnostic Trouble Code Information Extended - HUD_CAN : Test Not Completed This Operation Cycle";
BA_ "SignalType" SG_ 1286 DTCI_HUD_CAN_TstNCmpltdLstClr "ENM";
BA_ "SignalLongName" SG_ 1286 DTCI_HUD_CAN_TstNCmpltdLstClr "Diagnostic Trouble Code Information Extended - HUD_CAN : Test Not Completed Since Last Clear";
BA_ "SignalType" SG_ 1286 DTCI_HUD_CAN_TstFldOpCyc "ENM";
BA_ "SignalLongName" SG_ 1286 DTCI_HUD_CAN_TstFldOpCyc "Diagnostic Trouble Code Information Extended - HUD_CAN : Test Failed This Operation Cycle";
BA_ "SignalType" SG_ 1286 DTCI_HUD_CAN_TstFldLstClr "ENM";
BA_ "SignalLongName" SG_ 1286 DTCI_HUD_CAN_TstFldLstClr "Diagnostic Trouble Code Information Extended - HUD_CAN : Test Failed Since Last Clear";
BA_ "SignalType" SG_ 1286 DTCI_HUD_CAN_TstFld "ENM";
BA_ "SignalLongName" SG_ 1286 DTCI_HUD_CAN_TstFld "Diagnostic Trouble Code Information Extended - HUD_CAN : Test Failed";
BA_ "SignalType" SG_ 1286 DTCI_HUD_CAN_PndngDTC "ENM";
BA_ "SignalLongName" SG_ 1286 DTCI_HUD_CAN_PndngDTC "Diagnostic Trouble Code Information Extended - HUD_CAN : Pending DTC";
BA_ "SignalType" SG_ 1286 DTCI_HUD_CAN_DTCTriggered "ENM";
BA_ "SignalLongName" SG_ 1286 DTCI_HUD_CAN_DTCTriggered "Diagnostic Trouble Code Information Extended - HUD_CAN : Diagnostic Trouble Code Triggered";
BA_ "SignalType" SG_ 1286 DTCI_HUD_CAN_WrnIndTrggrd "ENM";
BA_ "SignalLongName" SG_ 1286 DTCI_HUD_CAN_WrnIndTrggrd "Diagnostic Trouble Code Information Extended - HUD_CAN : Warning Indicator Triggered";
BA_ "SignalType" SG_ 1286 DTCI_HUD_CAN_WrnIndRqd "ENM";
BA_ "SignalLongName" SG_ 1286 DTCI_HUD_CAN_WrnIndRqd "Diagnostic Trouble Code Information Extended - HUD_CAN : Warning Indicator Requested";
BA_ "SignalLongName" SG_ 1287 DTCI_HVAC_FP_F_DTCFailType "Diagnostic Trouble Code Information Extended - HVAC_FP_F : Diagnostic Trouble Code Failure Type";
BA_ "SignalType" SG_ 1287 DTCI_HVAC_FP_F_CnfrmdDTC "ENM";
BA_ "SignalLongName" SG_ 1287 DTCI_HVAC_FP_F_CnfrmdDTC "Diagnostic Trouble Code Information Extended - HVAC_FP_F : Confirmed DTC";
BA_ "SignalType" SG_ 1287 DTCI_HVAC_FP_F_DTCFaultType "ENM";
BA_ "SignalLongName" SG_ 1287 DTCI_HVAC_FP_F_DTCFaultType "Diagnostic Trouble Code Information Extended - HVAC_FP_F : Diagnostic Trouble Code Fault Type";
BA_ "SignalLongName" SG_ 1287 DTCI_HVAC_FP_F_DTCNumber "Diagnostic Trouble Code Information Extended - HVAC_FP_F : Diagnostic Trouble Code Number";
BA_ "SignalLongName" SG_ 1287 DTCI_HVAC_FP_F_DTCSource "Diagnostic Trouble Code Information Extended - HVAC_FP_F : Diagnostic Trouble Code Source";
BA_ "SignalType" SG_ 1287 DTCI_HVAC_FP_F_TstNCmpltdOpCyc "ENM";
BA_ "SignalLongName" SG_ 1287 DTCI_HVAC_FP_F_TstNCmpltdOpCyc "Diagnostic Trouble Code Information Extended - HVAC_FP_F : Test Not Completed This Operation Cycle";
BA_ "SignalType" SG_ 1287 DTCI_HVAC_FP_F_TstNCmpltdLstClr "ENM";
BA_ "SignalLongName" SG_ 1287 DTCI_HVAC_FP_F_TstNCmpltdLstClr "Diagnostic Trouble Code Information Extended - HVAC_FP_F : Test Not Completed Since Last Clear";
BA_ "SignalType" SG_ 1287 DTCI_HVAC_FP_F_TstFldOpCyc "ENM";
BA_ "SignalLongName" SG_ 1287 DTCI_HVAC_FP_F_TstFldOpCyc "Diagnostic Trouble Code Information Extended - HVAC_FP_F : Test Failed This Operation Cycle";
BA_ "SignalType" SG_ 1287 DTCI_HVAC_FP_F_TstFldLstClr "ENM";
BA_ "SignalLongName" SG_ 1287 DTCI_HVAC_FP_F_TstFldLstClr "Diagnostic Trouble Code Information Extended - HVAC_FP_F : Test Failed Since Last Clear";
BA_ "SignalType" SG_ 1287 DTCI_HVAC_FP_F_TstFld "ENM";
BA_ "SignalLongName" SG_ 1287 DTCI_HVAC_FP_F_TstFld "Diagnostic Trouble Code Information Extended - HVAC_FP_F : Test Failed";
BA_ "SignalType" SG_ 1287 DTCI_HVAC_FP_F_PndngDTC "ENM";
BA_ "SignalLongName" SG_ 1287 DTCI_HVAC_FP_F_PndngDTC "Diagnostic Trouble Code Information Extended - HVAC_FP_F : Pending DTC";
BA_ "SignalType" SG_ 1287 DTCI_HVAC_FP_F_DTCTriggered "ENM";
BA_ "SignalLongName" SG_ 1287 DTCI_HVAC_FP_F_DTCTriggered "Diagnostic Trouble Code Information Extended - HVAC_FP_F : Diagnostic Trouble Code Triggered";
BA_ "SignalType" SG_ 1287 DTCI_HVAC_FP_F_WrnIndTrggrd "ENM";
BA_ "SignalLongName" SG_ 1287 DTCI_HVAC_FP_F_WrnIndTrggrd "Diagnostic Trouble Code Information Extended - HVAC_FP_F : Warning Indicator Triggered";
BA_ "SignalType" SG_ 1287 DTCI_HVAC_FP_F_WrnIndRqd "ENM";
BA_ "SignalLongName" SG_ 1287 DTCI_HVAC_FP_F_WrnIndRqd "Diagnostic Trouble Code Information Extended - HVAC_FP_F : Warning Indicator Requested";
BA_ "SignalLongName" SG_ 1304 DTCI_HVAC_FP_R_DTCFailType "Diagnostic Trouble Code Information Extended - HVAC_FP_R : Diagnostic Trouble Code Failure Type";
BA_ "SignalType" SG_ 1304 DTCI_HVAC_FP_R_CnfrmdDTC "ENM";
BA_ "SignalLongName" SG_ 1304 DTCI_HVAC_FP_R_CnfrmdDTC "Diagnostic Trouble Code Information Extended - HVAC_FP_R : Confirmed DTC";
BA_ "SignalType" SG_ 1304 DTCI_HVAC_FP_R_DTCFaultType "ENM";
BA_ "SignalLongName" SG_ 1304 DTCI_HVAC_FP_R_DTCFaultType "Diagnostic Trouble Code Information Extended - HVAC_FP_R : Diagnostic Trouble Code Fault Type";
BA_ "SignalLongName" SG_ 1304 DTCI_HVAC_FP_R_DTCNumber "Diagnostic Trouble Code Information Extended - HVAC_FP_R : Diagnostic Trouble Code Number";
BA_ "SignalLongName" SG_ 1304 DTCI_HVAC_FP_R_DTCSource "Diagnostic Trouble Code Information Extended - HVAC_FP_R : Diagnostic Trouble Code Source";
BA_ "SignalType" SG_ 1304 DTCI_HVAC_FP_R_TstNCmpltdOpCyc "ENM";
BA_ "SignalLongName" SG_ 1304 DTCI_HVAC_FP_R_TstNCmpltdOpCyc "Diagnostic Trouble Code Information Extended - HVAC_FP_R : Test Not Completed This Operation Cycle";
BA_ "SignalType" SG_ 1304 DTCI_HVAC_FP_R_TstNCmpltdLstClr "ENM";
BA_ "SignalLongName" SG_ 1304 DTCI_HVAC_FP_R_TstNCmpltdLstClr "Diagnostic Trouble Code Information Extended - HVAC_FP_R : Test Not Completed Since Last Clear";
BA_ "SignalType" SG_ 1304 DTCI_HVAC_FP_R_TstFldOpCyc "ENM";
BA_ "SignalLongName" SG_ 1304 DTCI_HVAC_FP_R_TstFldOpCyc "Diagnostic Trouble Code Information Extended - HVAC_FP_R : Test Failed This Operation Cycle";
BA_ "SignalType" SG_ 1304 DTCI_HVAC_FP_R_TstFldLstClr "ENM";
BA_ "SignalLongName" SG_ 1304 DTCI_HVAC_FP_R_TstFldLstClr "Diagnostic Trouble Code Information Extended - HVAC_FP_R : Test Failed Since Last Clear";
BA_ "SignalType" SG_ 1304 DTCI_HVAC_FP_R_TstFld "ENM";
BA_ "SignalLongName" SG_ 1304 DTCI_HVAC_FP_R_TstFld "Diagnostic Trouble Code Information Extended - HVAC_FP_R : Test Failed";
BA_ "SignalType" SG_ 1304 DTCI_HVAC_FP_R_PndngDTC "ENM";
BA_ "SignalLongName" SG_ 1304 DTCI_HVAC_FP_R_PndngDTC "Diagnostic Trouble Code Information Extended - HVAC_FP_R : Pending DTC";
BA_ "SignalType" SG_ 1304 DTCI_HVAC_FP_R_DTCTriggered "ENM";
BA_ "SignalLongName" SG_ 1304 DTCI_HVAC_FP_R_DTCTriggered "Diagnostic Trouble Code Information Extended - HVAC_FP_R : Diagnostic Trouble Code Triggered";
BA_ "SignalType" SG_ 1304 DTCI_HVAC_FP_R_WrnIndTrggrd "ENM";
BA_ "SignalLongName" SG_ 1304 DTCI_HVAC_FP_R_WrnIndTrggrd "Diagnostic Trouble Code Information Extended - HVAC_FP_R : Warning Indicator Triggered";
BA_ "SignalType" SG_ 1304 DTCI_HVAC_FP_R_WrnIndRqd "ENM";
BA_ "SignalLongName" SG_ 1304 DTCI_HVAC_FP_R_WrnIndRqd "Diagnostic Trouble Code Information Extended - HVAC_FP_R : Warning Indicator Requested";
BA_ "SignalLongName" SG_ 1349 DTCI_ICCM_DTCFailType "Diagnostic Trouble Code Information Extended - ICCM : Diagnostic Trouble Code Failure Type";
BA_ "SignalType" SG_ 1349 DTCI_ICCM_CnfrmdDTC "ENM";
BA_ "SignalLongName" SG_ 1349 DTCI_ICCM_CnfrmdDTC "Diagnostic Trouble Code Information Extended - ICCM : Confirmed DTC";
BA_ "SignalType" SG_ 1349 DTCI_ICCM_DTCFaultType "ENM";
BA_ "SignalLongName" SG_ 1349 DTCI_ICCM_DTCFaultType "Diagnostic Trouble Code Information Extended - ICCM : Diagnostic Trouble Code Fault Type";
BA_ "SignalLongName" SG_ 1349 DTCI_ICCM_DTCNumber "Diagnostic Trouble Code Information Extended - ICCM : Diagnostic Trouble Code Number";
BA_ "SignalLongName" SG_ 1349 DTCI_ICCM_DTCSource "Diagnostic Trouble Code Information Extended - ICCM : Diagnostic Trouble Code Source";
BA_ "SignalType" SG_ 1349 DTCI_ICCM_TstNCmpltdOpCyc "ENM";
BA_ "SignalLongName" SG_ 1349 DTCI_ICCM_TstNCmpltdOpCyc "Diagnostic Trouble Code Information Extended - ICCM : Test Not Completed This Operation Cycle";
BA_ "SignalType" SG_ 1349 DTCI_ICCM_TstNCmpltdLstClr "ENM";
BA_ "SignalLongName" SG_ 1349 DTCI_ICCM_TstNCmpltdLstClr "Diagnostic Trouble Code Information Extended - ICCM : Test Not Completed Since Last Clear";
BA_ "SignalType" SG_ 1349 DTCI_ICCM_TstFldOpCyc "ENM";
BA_ "SignalLongName" SG_ 1349 DTCI_ICCM_TstFldOpCyc "Diagnostic Trouble Code Information Extended - ICCM : Test Failed This Operation Cycle";
BA_ "SignalType" SG_ 1349 DTCI_ICCM_TstFldLstClr "ENM";
BA_ "SignalLongName" SG_ 1349 DTCI_ICCM_TstFldLstClr "Diagnostic Trouble Code Information Extended - ICCM : Test Failed Since Last Clear";
BA_ "SignalType" SG_ 1349 DTCI_ICCM_TstFld "ENM";
BA_ "SignalLongName" SG_ 1349 DTCI_ICCM_TstFld "Diagnostic Trouble Code Information Extended - ICCM : Test Failed";
BA_ "SignalType" SG_ 1349 DTCI_ICCM_PndngDTC "ENM";
BA_ "SignalLongName" SG_ 1349 DTCI_ICCM_PndngDTC "Diagnostic Trouble Code Information Extended - ICCM : Pending DTC";
BA_ "SignalType" SG_ 1349 DTCI_ICCM_DTCTriggered "ENM";
BA_ "SignalLongName" SG_ 1349 DTCI_ICCM_DTCTriggered "Diagnostic Trouble Code Information Extended - ICCM : Diagnostic Trouble Code Triggered";
BA_ "SignalType" SG_ 1349 DTCI_ICCM_WrnIndTrggrd "ENM";
BA_ "SignalLongName" SG_ 1349 DTCI_ICCM_WrnIndTrggrd "Diagnostic Trouble Code Information Extended - ICCM : Warning Indicator Triggered";
BA_ "SignalType" SG_ 1349 DTCI_ICCM_WrnIndRqd "ENM";
BA_ "SignalLongName" SG_ 1349 DTCI_ICCM_WrnIndRqd "Diagnostic Trouble Code Information Extended - ICCM : Warning Indicator Requested";
BA_ "SignalLongName" SG_ 1307 DTCI_ICS_Info_DTCFailType "Diagnostic Trouble Code Information Extended - ICS_Info : Diagnostic Trouble Code Failure Type";
BA_ "SignalType" SG_ 1307 DTCI_ICS_Info_CnfrmdDTC "ENM";
BA_ "SignalLongName" SG_ 1307 DTCI_ICS_Info_CnfrmdDTC "Diagnostic Trouble Code Information Extended - ICS_Info : Confirmed DTC";
BA_ "SignalType" SG_ 1307 DTCI_ICS_Info_DTCFaultType "ENM";
BA_ "SignalLongName" SG_ 1307 DTCI_ICS_Info_DTCFaultType "Diagnostic Trouble Code Information Extended - ICS_Info : Diagnostic Trouble Code Fault Type";
BA_ "SignalLongName" SG_ 1307 DTCI_ICS_Info_DTCNumber "Diagnostic Trouble Code Information Extended - ICS_Info : Diagnostic Trouble Code Number";
BA_ "SignalLongName" SG_ 1307 DTCI_ICS_Info_DTCSource "Diagnostic Trouble Code Information Extended - ICS_Info : Diagnostic Trouble Code Source";
BA_ "SignalType" SG_ 1307 DTCI_ICS_Info_TstNCmpltdOpCyc "ENM";
BA_ "SignalLongName" SG_ 1307 DTCI_ICS_Info_TstNCmpltdOpCyc "Diagnostic Trouble Code Information Extended - ICS_Info : Test Not Completed This Operation Cycle";
BA_ "SignalType" SG_ 1307 DTCI_ICS_Info_TstNCmpltdLstClr "ENM";
BA_ "SignalLongName" SG_ 1307 DTCI_ICS_Info_TstNCmpltdLstClr "Diagnostic Trouble Code Information Extended - ICS_Info : Test Not Completed Since Last Clear";
BA_ "SignalType" SG_ 1307 DTCI_ICS_Info_TstFldOpCyc "ENM";
BA_ "SignalLongName" SG_ 1307 DTCI_ICS_Info_TstFldOpCyc "Diagnostic Trouble Code Information Extended - ICS_Info : Test Failed This Operation Cycle";
BA_ "SignalType" SG_ 1307 DTCI_ICS_Info_TstFldLstClr "ENM";
BA_ "SignalLongName" SG_ 1307 DTCI_ICS_Info_TstFldLstClr "Diagnostic Trouble Code Information Extended - ICS_Info : Test Failed Since Last Clear";
BA_ "SignalType" SG_ 1307 DTCI_ICS_Info_TstFld "ENM";
BA_ "SignalLongName" SG_ 1307 DTCI_ICS_Info_TstFld "Diagnostic Trouble Code Information Extended - ICS_Info : Test Failed";
BA_ "SignalType" SG_ 1307 DTCI_ICS_Info_PndngDTC "ENM";
BA_ "SignalLongName" SG_ 1307 DTCI_ICS_Info_PndngDTC "Diagnostic Trouble Code Information Extended - ICS_Info : Pending DTC";
BA_ "SignalType" SG_ 1307 DTCI_ICS_Info_DTCTriggered "ENM";
BA_ "SignalLongName" SG_ 1307 DTCI_ICS_Info_DTCTriggered "Diagnostic Trouble Code Information Extended - ICS_Info : Diagnostic Trouble Code Triggered";
BA_ "SignalType" SG_ 1307 DTCI_ICS_Info_WrnIndTrggrd "ENM";
BA_ "SignalLongName" SG_ 1307 DTCI_ICS_Info_WrnIndTrggrd "Diagnostic Trouble Code Information Extended - ICS_Info : Warning Indicator Triggered";
BA_ "SignalType" SG_ 1307 DTCI_ICS_Info_WrnIndRqd "ENM";
BA_ "SignalLongName" SG_ 1307 DTCI_ICS_Info_WrnIndRqd "Diagnostic Trouble Code Information Extended - ICS_Info : Warning Indicator Requested";
VAL_ 1470 PTOStndbySpdCstCurrSetVal 0 "Setting Unknown" 1 "RPM 900" 2 "RPM 1000" 3 "RPM 1100" 4 "RPM 1200" 5 "RPM 1300" 6 "RPM 1400" 7 "RPM 1500" ;
VAL_ 1470 PTOEngRunTmrCstAvlFlg1 0 "FALSE" 1 "TRUE" ;
VAL_ 1470 PTOEngSpdTypCstCurrSetVal 0 "Setting Unknown" 1 "Preset" 2 "Variable" ;
VAL_ 1470 PTOTpStpSpdCstCurrSetVal 0 "Setting Unknown" 1 "RPM 5" 2 "RPM 10" 3 "RPM 25" 4 "RPM 50" 5 "RPM 100" 6 "RPM 250" 7 "RPM 500" ;
VAL_ 1263 TrlrProfDrvrReqdSeltn 0 "No Action" 1 "Default Profile" 2 "Profile1" 3 "Profile2" 4 "Profile3" 5 "Profile4" 6 "Profile5" 7 "Profile6" 8 "Profile7" 9 "Profile8" 10 "Profile9" 11 "Profile10" 12 "Profile11" 13 "Profile12" 14 "Profile13" 15 "Profile14" 16 "Profile15" 17 "Profile16" 18 "Profile17" 19 "Profile18" 20 "Profile19" 21 "Profile20" ;
VAL_ 1263 TrlrProfDeltn 0 "No Profile Deleted" 1 "Profile1 Deleted" 2 "Profile2 Deleted" 3 "Profile3 Deleted" 4 "Profile4 Deleted" 5 "Profile5 Deleted" 6 "Profile6 Deleted" 7 "Profile7 Deleted" 8 "Profile8 Deleted" 9 "Profile9 Deleted" 10 "Profile10 Deleted" 11 "Profile11 Deleted" 12 "Profile12 Deleted" 13 "Profile13 Deleted" 14 "Profile14 Deleted" 15 "Profile15 Deleted" 16 "Profile16 Deleted" 17 "Profile17 Deleted" 18 "Profile18 Deleted" 19 "Profile19 Deleted" 20 "Profile20 Deleted" ;
VAL_ 1263 NumofAxls 0 "Unknown" 1 "1" 2 "2" 3 "3" ;
VAL_ 1265 ASTC_ChimSnkSpkrPos 0 "NO_ACTION" 1 "FULL_FRONT" 2 "FULL_REAR" 3 "FULL_LEFT" 4 "FULL_RIGHT" 5 "RIGHT_FRONT" 6 "RIGHT_REAR" 7 "LEFT_FRONT" 8 "LEFT_REAR" 9 "RESERVED_1" 10 "RESERVED_2" 11 "RESERVED_3" 12 "RESERVED_4" 13 "RESERVED_5" 14 "RESERVED_6" 15 "RESERVED_7" ;
VAL_ 1265 ASTC_MtxSnkMut 0 "FALSE" 1 "TRUE" ;
VAL_ 1265 ASTC_DSPMd 0 "NO_ACTION" 1 "DSP_MODE_0" 2 "DSP_MODE_1" 3 "DSP_MODE_2" 4 "DSP_MODE_3" 5 "DSP_MODE_4" 6 "DSP_MODE_5" 7 "DSP_MODE_6" 8 "DSP_MODE_7" 9 "RESERVED_1" 10 "RESERVED_2" 11 "RESERVED_3" 12 "RESERVED_4" 13 "RESERVED_5" 14 "RESERVED_6" 15 "RESERVED_7" ;
VAL_ 1265 ASTC_AmpLwPwrSt 0 "FALSE" 1 "TRUE" ;
VAL_ 1265 ASTC_VehNoisCmpnAct 0 "FALSE" 1 "TRUE" ;
VAL_ 1265 FrtCntrStckHptcFdbkReq 0 "NO_ACTION" 1 "TAP" 2 "LONG_PRESS" 3 "PRESS_&_HOLD_SCROLL" 4 "PRESS_&_HOLD_END" 5 "RESERVED_05" 6 "RESERVED_06" 7 "RESERVED_07" 8 "RESERVED_08" 9 "RESERVED_09" 10 "RESERVED_10" 11 "RESERVED_11" 12 "RESERVED_12" 13 "RESERVED_13" 14 "RESERVED_14" 15 "RESERVED_15" ;
VAL_ 1265 ASTC_GblAudSnkMut 0 "FALSE" 1 "TRUE" ;
VAL_ 1266 ZALC_LRMtxSnkMut 0 "FALSE" 1 "TRUE" ;
VAL_ 1266 ZALC_PsngrFrtMtxSnkMut 0 "FALSE" 1 "TRUE" ;
VAL_ 1266 ZALC_MltZnMixPrmtAudRR 0 "FALSE" 1 "TRUE" ;
VAL_ 1266 ZALC_RRMtxSnkMut 0 "FALSE" 1 "TRUE" ;
VAL_ 1266 ZALC_MltZnAudFtrStat 0 "Unknown" 1 "Single Zone Audio" 2 "Dual Zone Audio" 3 "Quad Zone Audio" ;
VAL_ 1266 ZALC_VcSrcActvOnRRMtx 0 "FALSE" 1 "TRUE" ;
VAL_ 1266 ZALC_MltZnMixPrmtAudDrvrFrt 0 "FALSE" 1 "TRUE" ;
VAL_ 1266 ZALC_VcSrcActvOnPsngrFrtMtx 0 "FALSE" 1 "TRUE" ;
VAL_ 1266 FrtCntrStckOptDskDrvDckStat 0 "DS_EMPTY" 1 "DS_LOADING" 2 "DS_READY" 3 "DS_EJECT" 4 "DS_READ_FORMAT_ERROR" 5 "DS_STAT_5" 6 "DS_STAT_6" 7 "DS_STAT_7" ;
VAL_ 1266 ZALC_MltZnMixPrmtAudLR 0 "FALSE" 1 "TRUE" ;
VAL_ 1266 ZALC_MltZnMixPrmtAudPsngrFrt 0 "FALSE" 1 "TRUE" ;
VAL_ 1266 ZALC_VcSrcActvOnLRMtx 0 "FALSE" 1 "TRUE" ;
VAL_ 1268 TrlrTirePresSnsrIDLrnReqd 0 "FALSE" 1 "TRUE" ;
VAL_ 1268 TrlrThftAlrtEnbld 0 "FALSE" 1 "TRUE" ;
VAL_ 1268 TrlrLghtAlrtEnbld 0 "FALSE" 1 "TRUE" ;
VAL_ 1268 DAPR_CtlDir 0 "None" 1 "Left" 2 "Right" 3 "Center" 4 "Custom1" 5 "Custom 2" 6 "Custom 3" 7 "Custom 4" ;
VAL_ 1268 TrlrTirePresProfXferd 0 "FALSE" 1 "TRUE" ;
VAL_ 1268 DAPR_CurrPrmt 0 "FALSE" 1 "TRUE" ;
VAL_ 1268 DAPR_CtlZn 0 "None" 1 "Zone 1" 2 "Zone 2" 3 "Zone 3" 4 "Zone 4" 5 "Zone 5" 6 "Zone 6" 7 "Zone 7" 8 "Zone 8" 9 "Zone 9" 10 "Zone 10" 11 "Zone 11" 12 "Zone 12" 13 "Zone 13" 14 "Custom 1" 15 "Custom 2" ;
VAL_ 1269 LVMAVC_RmtSpchRcgnID 0 "NO_ACTION" 1 "LVM_NAV" 2 "LVM_DMB" 3 "LVM_PDR" ;
VAL_ 1269 LVMAVC_PrmtAudResp 0 "NO_ACTION" 1 "ACTIVE" ;
VAL_ 1269 LVMAVC_RmtSpchRcgnActn 0 "NO_ACTION" 1 "ACTIVATE_LVM_SR" 2 "PTT_BUTTON_PRESS" 3 "END_BUTTON_PRESS" ;
VAL_ 1269 LVMAVC_ApplID 0 "NO_ACTION" 1 "LVM_NAV" 2 "LVM_DMB" 3 "LVM_PERFORMANCE_COMPUTER" 4 "LVM_COMPLEX_MODE" ;
VAL_ 1269 LVMAVC_StreoAudResp 0 "NO_ACTION" 1 "ACTIVE" ;
VAL_ 1269 LVMAVC_RmtEnbl 0 "NO_ACTION" 1 "REMOTE_ENABLE_ON" 2 "REMOTE_ENABLE_ACTIVE" ;
VAL_ 1269 LVMAVC_SpchRcgnAval 0 "NO_ACTION" 1 "LVM_SPEECH_REC_AVAILABLE" ;
VAL_ 1269 TrlrStatTowHaulModeOvrrd 0 "No Override" 1 "Override to Not Tow Haul" 2 "Unused and Reserved 1" 3 "Unused and Reserved 2" ;
VAL_ 1269 TrlrLtngSeqReq 0 "No Action" 1 "Off" 2 "On" ;
VAL_ 1269 TrlrHtchTyp 0 "Unknown" 1 "Conventional" 2 "5th Wheel" 3 "Gooseneck" ;
VAL_ 1269 FrtCntrStckVidInSel 0 "Primary Video Input" 1 "Reserved" 2 "LVM Video Input" ;
VAL_ 1269 TrlrAppInvsblTrlrPrvwReqd 0 "FALSE" 1 "TRUE" ;
VAL_ 1269 TrlrAppAux2CamPrvwReqd 0 "FALSE" 1 "TRUE" ;
VAL_ 1269 TrlrAppAux1CamPrvwReqd 0 "FALSE" 1 "TRUE" ;
VAL_ 1269 TrlRvsLghtFldEnbld 0 "FALSE" 1 "TRUE" ;
VAL_ 1269 FrtCntrStckTchCtlrRstCmd 0 "FALSE" 1 "TRUE" ;
VAL_ 1269 Frt360CamSwAct 0 "FALSE" 1 "TRUE" ;
VAL_ 1269 TrlrTyp 0 "Unknown" 1 "Box" 2 "Not-Box" ;
VAL_ 1272 TrgdVidRecSwAct 0 "FALSE" 1 "TRUE" ;
VAL_ 1272 SrrndVsnRcrdrListFcs 0 "Unknown" 1 "File_1" 2 "File_2" 3 "File_3" 4 "File_4" 5 "File_5" 6 "Delete_1" 7 "Delete_2" 8 "Delete_3" 9 "Delete_4" 10 "Delete_5" 11 "No Focus" ;
VAL_ 1272 VwgVwprtSeltn 0 "Unknown" 1 "Front Perspective" 2 "Front Junction" 3 "Front Overhead" 4 "Side Forward" 5 "Rear Perspective" 6 "Rear Junction" 7 "Rear Overhead" 8 "Side Rearward" 9 "Bowl" 10 "Zoomed Bowl" 11 "Japan" 12 "Rear Hitch" 13 "Bed Hitch" 14 "Trailer Aux1" 15 "Trailer Towing Mirror" 16 "L R Trailer Towing Mirror" 17 "Trailer Aux1 Combined" 18 "Trailer Aux2" 19 "Invisible Trailer" 20 "Cargo Bed" 21 "Curb Overhead" 22 "Curb" 23 "No Request" 24 "Transparent Hood" ;
VAL_ 1272 PFASndSeltnCstChgSetReq 0 "No Action" 1 "Pedestrian Alert Sound 1" 2 "Pedestrian Alert Sound 2" 3 "Pedestrian Alert Sound 3" 4 "RESERVED_4" 5 "RESERVED_5" 6 "RESERVED_6" 7 "RESERVED_7" ;
VAL_ 1272 SrrndVsnRcrdrVwprtSeltn 0 "Unknown" 1 "Playback Mosaic" 2 "Playback Zoom1" 3 "Playback Zoom2" 4 "Playback Zoom3" 5 "Playback Zoom4" 6 "List Recent" 7 "List Saved" 8 "No Request" ;
VAL_ 1272 SrrndVsnRcrdrFileSeltn 0 "Unknown" 1 "File_1" 2 "File_2" 3 "File_3" 4 "File_4" 5 "File_5" 6 "No Selection" ;
VAL_ 1272 SrrndVsnRcrdrFileDeltn 0 "Unknown" 1 "File_1" 2 "File_2" 3 "File_3" 4 "File_4" 5 "File_5" 6 "No Selection" ;
VAL_ 1272 VGS_DynActv 0 "FALSE" 1 "TRUE" ;
VAL_ 1272 VGS_CurbVwActv 0 "FALSE" 1 "TRUE" ;
VAL_ 1272 SrrndVsnRcrdrPlybkSeltn 0 "Unknown" 1 "Play" 2 "Pause" 3 "Rewind" 4 "Fast Forward" 5 "No Selection" ;
VAL_ 1272 SrrndVsnRcrdrPlybkFcs 0 "Unknown" 1 "View_1" 2 "View_2" 3 "View_3" 4 "View_4" 5 "Zoomed" 6 "No Focus" ;
VAL_ 1272 SrrndVsnRcrdrSaveFile 0 "Unknown" 1 "Save" 2 "Not Pressed" ;
VAL_ 1272 SrrndVsnRcrdrRcrdSeltn 0 "Unknown" 1 "Enabled" 2 "Disabled" ;
VAL_ 1272 SrrndVsnRcrdrListPgSeltn 0 "Unknown" 1 "Page Up" 2 "Page Down" 3 "No Selection" ;
VAL_ 1272 VGS_TrlrActv 0 "FALSE" 1 "TRUE" ;
VAL_ 1258 HMIInCarVcCommCtl 0 "ICC_Off" 1 "Front_High_Rear_High" 2 "Front_High_Rear_Normal" 3 "Front_High_Rear_Off" 4 "Front_Normal_Rear_High" 5 "Front_Normal_Rear_Normal" 6 "Front_Normal_Rear_Off" ;
VAL_ 1258 AutoLnChgCstChgSetReq 0 "No Action" 1 "Off" 2 "On" 3 "LCOD" 4 "LCOD and ALC" ;
VAL_ 1258 DrvrSeltdTrlrPrsnt 0 "Trailer Present" 1 "No Trailer" ;
VAL_ 1258 VcRcgnSesnActv 0 "FALSE" 1 "TRUE" ;
VAL_ 1258 HndsFrVcCallActv 0 "FALSE" 1 "TRUE" ;
VAL_ 1258 FrtZnAudVolSyncCtlOn 0 "FALSE" 1 "TRUE" ;
VAL_ 1258 DirAudPrmtRndrngEnbld 0 "FALSE" 1 "TRUE" ;
VAL_ 1063 PASftBtnSeltdStatRw 0 "Not_Pressed" 1 "Pressed" 2 "Unknown" 3 "Failed" ;
VAL_ 1063 APASftBtnSeltdStatRw 0 "Not_Pressed" 1 "Pressed" 2 "Unknown" 3 "Failed" ;
VAL_ 552 WCM_LCMDataMsgStat 0 "No Action" 1 "Acknowledge" ;
VAL_ 552 WCM_LCMFileTrans 0 "No Action" 1 "Begin Transfer" 2 "Successful Block Transfer" 3 "Cancel Transfer" 4 "Retry Last Block" ;
VAL_ 1356 PwrRrClsrCstChgSetReq 0 "No_Action" 1 "Off" 2 "On" 3 "On_Custom_Height" 4 "RESERVED_4" 5 "RESERVED_5" 6 "RESERVED_6" 7 "RESERVED_7" ;
VAL_ 1060 OATDispdVal_DuD 0 "FALSE" 1 "TRUE" ;
VAL_ 1060 PTOSet1SpdCstSetReq 0 "No Action" 1 "RPM 1100" 2 "RPM 1200" 3 "RPM 1300" 4 "RPM 1400" 5 "RPM 1500" 6 "RPM 1600" 7 "RPM 1700" 8 "RPM 1800" 9 "RPM 1900" 10 "RPM 2000" 11 "RPM 2100" 12 "RPM 2200" 13 "RPM 2300" 14 "RPM 2400" 15 "RPM 2500" ;
VAL_ 1060 PTOEngRunTmrCstSetReq 0 "No Action" 1 "Min 10" 2 "Min 30" 3 "Min 90" 4 "Min 120" 5 "Min 150" 6 "Min 180" 7 "Min 210" 8 "Min 240" 9 "Min 270" 10 "Min 200" 11 "Min 330" 12 "Min 360" 13 "Min 390" 14 "Min 420" 15 "Min 450" ;
VAL_ 1060 PTOStndbySpdCstSetReq 0 "No Action" 1 "RPM 900" 2 "RPM 1000" 3 "RPM 1100" 4 "RPM 1200" 5 "RPM 1300" 6 "RPM 1400" 7 "RPM 1500" ;
VAL_ 1060 PTOSet2SpdCstSetReq 0 "No Action" 1 "RPM 1900" 2 "RPM 2000" 3 "RPM 2100" 4 "RPM 2200" 5 "RPM 2300" 6 "RPM 2400" 7 "RPM 2500" 8 "RPM 2600" 9 "RPM 2700" 10 "RPM 2800" 11 "RPM 2900" 12 "RPM 3000" 13 "RPM 3100" 14 "RPM 3200" 15 "RPM 3300" ;
VAL_ 1060 PTOModeCstSetReq 0 "No Action" 1 "Standard" 2 "Remote" ;
VAL_ 1060 PTOEngSpdTypCstSetReq 0 "No Action" 1 "Preset" 2 "Variable" ;
VAL_ 1060 PTOTpStpSpdCstSetReq 0 "No Action" 1 "RPM 5" 2 "RPM 10" 3 "RPM 25" 4 "RPM 50" 5 "RPM 100" 6 "RPM 250" 7 "RPM 500" ;
VAL_ 1419 AutoTrnspHdActvnCstChgSetReq 0 "No Action" 1 "Active" 2 "Inactive" ;
VAL_ 1108 DTCI_AGC_CnfrmdDTC 0 "FALSE" 1 "TRUE" ;
VAL_ 1108 DTCI_AGC_DTCFaultType 0 "Not Supported" 1 "Type A" 2 "Type B" 3 "Type C" ;
VAL_ 1108 DTCI_AGC_TstNCmpltdOpCyc 0 "FALSE" 1 "TRUE" ;
VAL_ 1108 DTCI_AGC_TstNCmpltdLstClr 0 "FALSE" 1 "TRUE" ;
VAL_ 1108 DTCI_AGC_TstFldOpCyc 0 "FALSE" 1 "TRUE" ;
VAL_ 1108 DTCI_AGC_TstFldLstClr 0 "FALSE" 1 "TRUE" ;
VAL_ 1108 DTCI_AGC_TstFld 0 "FALSE" 1 "TRUE" ;
VAL_ 1108 DTCI_AGC_PndngDTC 0 "FALSE" 1 "TRUE" ;
VAL_ 1108 DTCI_AGC_DTCTriggered 0 "FALSE" 1 "TRUE" ;
VAL_ 1108 DTCI_AGC_WrnIndTrggrd 0 "FALSE" 1 "TRUE" ;
VAL_ 1108 DTCI_AGC_WrnIndRqd 0 "FALSE" 1 "TRUE" ;
VAL_ 1116 DTCI_AHL_AFL_CnfrmdDTC 0 "FALSE" 1 "TRUE" ;
VAL_ 1116 DTCI_AHL_AFL_DTCFaultType 0 "Not Supported" 1 "Type A" 2 "Type B" 3 "Type C" ;
VAL_ 1116 DTCI_AHL_AFL_TstNCmpltdOpCyc 0 "FALSE" 1 "TRUE" ;
VAL_ 1116 DTCI_AHL_AFL_TstNCmpltdLstClr 0 "FALSE" 1 "TRUE" ;
VAL_ 1116 DTCI_AHL_AFL_TstFldOpCyc 0 "FALSE" 1 "TRUE" ;
VAL_ 1116 DTCI_AHL_AFL_TstFldLstClr 0 "FALSE" 1 "TRUE" ;
VAL_ 1116 DTCI_AHL_AFL_TstFld 0 "FALSE" 1 "TRUE" ;
VAL_ 1116 DTCI_AHL_AFL_PndngDTC 0 "FALSE" 1 "TRUE" ;
VAL_ 1116 DTCI_AHL_AFL_DTCTriggered 0 "FALSE" 1 "TRUE" ;
VAL_ 1116 DTCI_AHL_AFL_WrnIndTrggrd 0 "FALSE" 1 "TRUE" ;
VAL_ 1116 DTCI_AHL_AFL_WrnIndRqd 0 "FALSE" 1 "TRUE" ;
VAL_ 1422 DTCI_AHS_CnfrmdDTC 0 "FALSE" 1 "TRUE" ;
VAL_ 1422 DTCI_AHS_DTCFaultType 0 "Not Supported" 1 "Type A" 2 "Type B" 3 "Type C" ;
VAL_ 1422 DTCI_AHS_TstNCmpltdOpCyc 0 "FALSE" 1 "TRUE" ;
VAL_ 1422 DTCI_AHS_TstNCmpltdLstClr 0 "FALSE" 1 "TRUE" ;
VAL_ 1422 DTCI_AHS_TstFldOpCyc 0 "FALSE" 1 "TRUE" ;
VAL_ 1422 DTCI_AHS_TstFldLstClr 0 "FALSE" 1 "TRUE" ;
VAL_ 1422 DTCI_AHS_TstFld 0 "FALSE" 1 "TRUE" ;
VAL_ 1422 DTCI_AHS_PndngDTC 0 "FALSE" 1 "TRUE" ;
VAL_ 1422 DTCI_AHS_DTCTriggered 0 "FALSE" 1 "TRUE" ;
VAL_ 1422 DTCI_AHS_WrnIndTrggrd 0 "FALSE" 1 "TRUE" ;
VAL_ 1422 DTCI_AHS_WrnIndRqd 0 "FALSE" 1 "TRUE" ;
VAL_ 1117 DTCI_ALC_CnfrmdDTC 0 "FALSE" 1 "TRUE" ;
VAL_ 1117 DTCI_ALC_DTCFaultType 0 "Not Supported" 1 "Type A" 2 "Type B" 3 "Type C" ;
VAL_ 1117 DTCI_ALC_TstNCmpltdOpCyc 0 "FALSE" 1 "TRUE" ;
VAL_ 1117 DTCI_ALC_TstNCmpltdLstClr 0 "FALSE" 1 "TRUE" ;
VAL_ 1117 DTCI_ALC_TstFldOpCyc 0 "FALSE" 1 "TRUE" ;
VAL_ 1117 DTCI_ALC_TstFldLstClr 0 "FALSE" 1 "TRUE" ;
VAL_ 1117 DTCI_ALC_TstFld 0 "FALSE" 1 "TRUE" ;
VAL_ 1117 DTCI_ALC_PndngDTC 0 "FALSE" 1 "TRUE" ;
VAL_ 1117 DTCI_ALC_DTCTriggered 0 "FALSE" 1 "TRUE" ;
VAL_ 1117 DTCI_ALC_WrnIndTrggrd 0 "FALSE" 1 "TRUE" ;
VAL_ 1117 DTCI_ALC_WrnIndRqd 0 "FALSE" 1 "TRUE" ;
VAL_ 1109 DTCI_AMP_CnfrmdDTC 0 "FALSE" 1 "TRUE" ;
VAL_ 1109 DTCI_AMP_DTCFaultType 0 "Not Supported" 1 "Type A" 2 "Type B" 3 "Type C" ;
VAL_ 1109 DTCI_AMP_TstNCmpltdOpCyc 0 "FALSE" 1 "TRUE" ;
VAL_ 1109 DTCI_AMP_TstNCmpltdLstClr 0 "FALSE" 1 "TRUE" ;
VAL_ 1109 DTCI_AMP_TstFldOpCyc 0 "FALSE" 1 "TRUE" ;
VAL_ 1109 DTCI_AMP_TstFldLstClr 0 "FALSE" 1 "TRUE" ;
VAL_ 1109 DTCI_AMP_TstFld 0 "FALSE" 1 "TRUE" ;
VAL_ 1109 DTCI_AMP_PndngDTC 0 "FALSE" 1 "TRUE" ;
VAL_ 1109 DTCI_AMP_DTCTriggered 0 "FALSE" 1 "TRUE" ;
VAL_ 1109 DTCI_AMP_WrnIndTrggrd 0 "FALSE" 1 "TRUE" ;
VAL_ 1109 DTCI_AMP_WrnIndRqd 0 "FALSE" 1 "TRUE" ;
VAL_ 1118 DTCI_AOS_CnfrmdDTC 0 "FALSE" 1 "TRUE" ;
VAL_ 1118 DTCI_AOS_DTCFaultType 0 "Not Supported" 1 "Type A" 2 "Type B" 3 "Type C" ;
VAL_ 1118 DTCI_AOS_TstNCmpltdOpCyc 0 "FALSE" 1 "TRUE" ;
VAL_ 1118 DTCI_AOS_TstNCmpltdLstClr 0 "FALSE" 1 "TRUE" ;
VAL_ 1118 DTCI_AOS_TstFldOpCyc 0 "FALSE" 1 "TRUE" ;
VAL_ 1118 DTCI_AOS_TstFldLstClr 0 "FALSE" 1 "TRUE" ;
VAL_ 1118 DTCI_AOS_TstFld 0 "FALSE" 1 "TRUE" ;
VAL_ 1118 DTCI_AOS_PndngDTC 0 "FALSE" 1 "TRUE" ;
VAL_ 1118 DTCI_AOS_DTCTriggered 0 "FALSE" 1 "TRUE" ;
VAL_ 1118 DTCI_AOS_WrnIndTrggrd 0 "FALSE" 1 "TRUE" ;
VAL_ 1118 DTCI_AOS_WrnIndRqd 0 "FALSE" 1 "TRUE" ;
VAL_ 1119 DTCI_APA_CnfrmdDTC 0 "FALSE" 1 "TRUE" ;
VAL_ 1119 DTCI_APA_DTCFaultType 0 "Not Supported" 1 "Type A" 2 "Type B" 3 "Type C" ;
VAL_ 1119 DTCI_APA_TstNCmpltdOpCyc 0 "FALSE" 1 "TRUE" ;
VAL_ 1119 DTCI_APA_TstNCmpltdLstClr 0 "FALSE" 1 "TRUE" ;
VAL_ 1119 DTCI_APA_TstFldOpCyc 0 "FALSE" 1 "TRUE" ;
VAL_ 1119 DTCI_APA_TstFldLstClr 0 "FALSE" 1 "TRUE" ;
VAL_ 1119 DTCI_APA_TstFld 0 "FALSE" 1 "TRUE" ;
VAL_ 1119 DTCI_APA_PndngDTC 0 "FALSE" 1 "TRUE" ;
VAL_ 1119 DTCI_APA_DTCTriggered 0 "FALSE" 1 "TRUE" ;
VAL_ 1119 DTCI_APA_WrnIndTrggrd 0 "FALSE" 1 "TRUE" ;
VAL_ 1119 DTCI_APA_WrnIndRqd 0 "FALSE" 1 "TRUE" ;
VAL_ 1120 DTCI_ARB_CnfrmdDTC 0 "FALSE" 1 "TRUE" ;
VAL_ 1120 DTCI_ARB_DTCFaultType 0 "Not Supported" 1 "Type A" 2 "Type B" 3 "Type C" ;
VAL_ 1120 DTCI_ARB_TstNCmpltdOpCyc 0 "FALSE" 1 "TRUE" ;
VAL_ 1120 DTCI_ARB_TstNCmpltdLstClr 0 "FALSE" 1 "TRUE" ;
VAL_ 1120 DTCI_ARB_TstFldOpCyc 0 "FALSE" 1 "TRUE" ;
VAL_ 1120 DTCI_ARB_TstFldLstClr 0 "FALSE" 1 "TRUE" ;
VAL_ 1120 DTCI_ARB_TstFld 0 "FALSE" 1 "TRUE" ;
VAL_ 1120 DTCI_ARB_PndngDTC 0 "FALSE" 1 "TRUE" ;
VAL_ 1120 DTCI_ARB_DTCTriggered 0 "FALSE" 1 "TRUE" ;
VAL_ 1120 DTCI_ARB_WrnIndTrggrd 0 "FALSE" 1 "TRUE" ;
VAL_ 1120 DTCI_ARB_WrnIndRqd 0 "FALSE" 1 "TRUE" ;
VAL_ 1054 DTCI_ARS_CnfrmdDTC 0 "FALSE" 1 "TRUE" ;
VAL_ 1054 DTCI_ARS_DTCFaultType 0 "Not Supported" 1 "Type A" 2 "Type B" 3 "Type C" ;
VAL_ 1054 DTCI_ARS_TstNCmpltdOpCyc 0 "FALSE" 1 "TRUE" ;
VAL_ 1054 DTCI_ARS_TstNCmpltdLstClr 0 "FALSE" 1 "TRUE" ;
VAL_ 1054 DTCI_ARS_TstFldOpCyc 0 "FALSE" 1 "TRUE" ;
VAL_ 1054 DTCI_ARS_TstFldLstClr 0 "FALSE" 1 "TRUE" ;
VAL_ 1054 DTCI_ARS_TstFld 0 "FALSE" 1 "TRUE" ;
VAL_ 1054 DTCI_ARS_PndngDTC 0 "FALSE" 1 "TRUE" ;
VAL_ 1054 DTCI_ARS_DTCTriggered 0 "FALSE" 1 "TRUE" ;
VAL_ 1054 DTCI_ARS_WrnIndTrggrd 0 "FALSE" 1 "TRUE" ;
VAL_ 1054 DTCI_ARS_WrnIndRqd 0 "FALSE" 1 "TRUE" ;
VAL_ 1121 DTCI_BCM_CnfrmdDTC 0 "FALSE" 1 "TRUE" ;
VAL_ 1121 DTCI_BCM_DTCFaultType 0 "Not Supported" 1 "Type A" 2 "Type B" 3 "Type C" ;
VAL_ 1121 DTCI_BCM_TstNCmpltdOpCyc 0 "FALSE" 1 "TRUE" ;
VAL_ 1121 DTCI_BCM_TstNCmpltdLstClr 0 "FALSE" 1 "TRUE" ;
VAL_ 1121 DTCI_BCM_TstFldOpCyc 0 "FALSE" 1 "TRUE" ;
VAL_ 1121 DTCI_BCM_TstFldLstClr 0 "FALSE" 1 "TRUE" ;
VAL_ 1121 DTCI_BCM_TstFld 0 "FALSE" 1 "TRUE" ;
VAL_ 1121 DTCI_BCM_PndngDTC 0 "FALSE" 1 "TRUE" ;
VAL_ 1121 DTCI_BCM_DTCTriggered 0 "FALSE" 1 "TRUE" ;
VAL_ 1121 DTCI_BCM_WrnIndTrggrd 0 "FALSE" 1 "TRUE" ;
VAL_ 1121 DTCI_BCM_WrnIndRqd 0 "FALSE" 1 "TRUE" ;
VAL_ 1411 DTCI_BSM_MH_CnfrmdDTC 0 "FALSE" 1 "TRUE" ;
VAL_ 1411 DTCI_BSM_MH_DTCFaultType 0 "Not Supported" 1 "Type A" 2 "Type B" 3 "Type C" ;
VAL_ 1411 DTCI_BSM_MH_TstNCmpltdOpCyc 0 "FALSE" 1 "TRUE" ;
VAL_ 1411 DTCI_BSM_MH_TstNCmpltdLstClr 0 "FALSE" 1 "TRUE" ;
VAL_ 1411 DTCI_BSM_MH_TstFldOpCyc 0 "FALSE" 1 "TRUE" ;
VAL_ 1411 DTCI_BSM_MH_TstFldLstClr 0 "FALSE" 1 "TRUE" ;
VAL_ 1411 DTCI_BSM_MH_TstFld 0 "FALSE" 1 "TRUE" ;
VAL_ 1411 DTCI_BSM_MH_PndngDTC 0 "FALSE" 1 "TRUE" ;
VAL_ 1411 DTCI_BSM_MH_DTCTriggered 0 "FALSE" 1 "TRUE" ;
VAL_ 1411 DTCI_BSM_MH_WrnIndTrggrd 0 "FALSE" 1 "TRUE" ;
VAL_ 1411 DTCI_BSM_MH_WrnIndRqd 0 "FALSE" 1 "TRUE" ;
VAL_ 1122 DTCI_BSM_CnfrmdDTC 0 "FALSE" 1 "TRUE" ;
VAL_ 1122 DTCI_BSM_DTCFaultType 0 "Not Supported" 1 "Type A" 2 "Type B" 3 "Type C" ;
VAL_ 1122 DTCI_BSM_TstNCmpltdOpCyc 0 "FALSE" 1 "TRUE" ;
VAL_ 1122 DTCI_BSM_TstNCmpltdLstClr 0 "FALSE" 1 "TRUE" ;
VAL_ 1122 DTCI_BSM_TstFldOpCyc 0 "FALSE" 1 "TRUE" ;
VAL_ 1122 DTCI_BSM_TstFldLstClr 0 "FALSE" 1 "TRUE" ;
VAL_ 1122 DTCI_BSM_TstFld 0 "FALSE" 1 "TRUE" ;
VAL_ 1122 DTCI_BSM_PndngDTC 0 "FALSE" 1 "TRUE" ;
VAL_ 1122 DTCI_BSM_DTCTriggered 0 "FALSE" 1 "TRUE" ;
VAL_ 1122 DTCI_BSM_WrnIndTrggrd 0 "FALSE" 1 "TRUE" ;
VAL_ 1122 DTCI_BSM_WrnIndRqd 0 "FALSE" 1 "TRUE" ;
VAL_ 1123 DTCI_CGM_CnfrmdDTC 0 "FALSE" 1 "TRUE" ;
VAL_ 1123 DTCI_CGM_DTCFaultType 0 "Not Supported" 1 "Type A" 2 "Type B" 3 "Type C" ;
VAL_ 1123 DTCI_CGM_TstNCmpltdOpCyc 0 "FALSE" 1 "TRUE" ;
VAL_ 1123 DTCI_CGM_TstNCmpltdLstClr 0 "FALSE" 1 "TRUE" ;
VAL_ 1123 DTCI_CGM_TstFldOpCyc 0 "FALSE" 1 "TRUE" ;
VAL_ 1123 DTCI_CGM_TstFldLstClr 0 "FALSE" 1 "TRUE" ;
VAL_ 1123 DTCI_CGM_TstFld 0 "FALSE" 1 "TRUE" ;
VAL_ 1123 DTCI_CGM_PndngDTC 0 "FALSE" 1 "TRUE" ;
VAL_ 1123 DTCI_CGM_DTCTriggered 0 "FALSE" 1 "TRUE" ;
VAL_ 1123 DTCI_CGM_WrnIndTrggrd 0 "FALSE" 1 "TRUE" ;
VAL_ 1123 DTCI_CGM_WrnIndRqd 0 "FALSE" 1 "TRUE" ;
VAL_ 1065 DTCI_CMMa_CnfrmdDTC 0 "FALSE" 1 "TRUE" ;
VAL_ 1065 DTCI_CMMa_DTCFaultType 0 "Not Supported" 1 "Type A" 2 "Type B" 3 "Type C" ;
VAL_ 1065 DTCI_CMMa_TstNCmpltdOpCyc 0 "FALSE" 1 "TRUE" ;
VAL_ 1065 DTCI_CMMa_TstNCmpltdLstClr 0 "FALSE" 1 "TRUE" ;
VAL_ 1065 DTCI_CMMa_TstFldOpCyc 0 "FALSE" 1 "TRUE" ;
VAL_ 1065 DTCI_CMMa_TstFldLstClr 0 "FALSE" 1 "TRUE" ;
VAL_ 1065 DTCI_CMMa_TstFld 0 "FALSE" 1 "TRUE" ;
VAL_ 1065 DTCI_CMMa_PndngDTC 0 "FALSE" 1 "TRUE" ;
VAL_ 1065 DTCI_CMMa_DTCTriggered 0 "FALSE" 1 "TRUE" ;
VAL_ 1065 DTCI_CMMa_WrnIndTrggrd 0 "FALSE" 1 "TRUE" ;
VAL_ 1065 DTCI_CMMa_WrnIndRqd 0 "FALSE" 1 "TRUE" ;
VAL_ 1072 DTCI_CMMb_CnfrmdDTC 0 "FALSE" 1 "TRUE" ;
VAL_ 1072 DTCI_CMMb_DTCFaultType 0 "Not Supported" 1 "Type A" 2 "Type B" 3 "Type C" ;
VAL_ 1072 DTCI_CMMb_TstNCmpltdOpCyc 0 "FALSE" 1 "TRUE" ;
VAL_ 1072 DTCI_CMMb_TstNCmpltdLstClr 0 "FALSE" 1 "TRUE" ;
VAL_ 1072 DTCI_CMMb_TstFldOpCyc 0 "FALSE" 1 "TRUE" ;
VAL_ 1072 DTCI_CMMb_TstFldLstClr 0 "FALSE" 1 "TRUE" ;
VAL_ 1072 DTCI_CMMb_TstFld 0 "FALSE" 1 "TRUE" ;
VAL_ 1072 DTCI_CMMb_PndngDTC 0 "FALSE" 1 "TRUE" ;
VAL_ 1072 DTCI_CMMb_DTCTriggered 0 "FALSE" 1 "TRUE" ;
VAL_ 1072 DTCI_CMMb_WrnIndTrggrd 0 "FALSE" 1 "TRUE" ;
VAL_ 1072 DTCI_CMMb_WrnIndRqd 0 "FALSE" 1 "TRUE" ;
VAL_ 1262 DTCI_CSM_CnfrmdDTC 0 "FALSE" 1 "TRUE" ;
VAL_ 1262 DTCI_CSM_DTCFaultType 0 "Not Supported" 1 "Type A" 2 "Type B" 3 "Type C" ;
VAL_ 1262 DTCI_CSM_TstNCmpltdOpCyc 0 "FALSE" 1 "TRUE" ;
VAL_ 1262 DTCI_CSM_TstNCmpltdLstClr 0 "FALSE" 1 "TRUE" ;
VAL_ 1262 DTCI_CSM_TstFldOpCyc 0 "FALSE" 1 "TRUE" ;
VAL_ 1262 DTCI_CSM_TstFldLstClr 0 "FALSE" 1 "TRUE" ;
VAL_ 1262 DTCI_CSM_TstFld 0 "FALSE" 1 "TRUE" ;
VAL_ 1262 DTCI_CSM_PndngDTC 0 "FALSE" 1 "TRUE" ;
VAL_ 1262 DTCI_CSM_DTCTriggered 0 "FALSE" 1 "TRUE" ;
VAL_ 1262 DTCI_CSM_WrnIndTrggrd 0 "FALSE" 1 "TRUE" ;
VAL_ 1262 DTCI_CSM_WrnIndRqd 0 "FALSE" 1 "TRUE" ;
VAL_ 1124 DTCI_DCM_CnfrmdDTC 0 "FALSE" 1 "TRUE" ;
VAL_ 1124 DTCI_DCM_DTCFaultType 0 "Not Supported" 1 "Type A" 2 "Type B" 3 "Type C" ;
VAL_ 1124 DTCI_DCM_TstNCmpltdOpCyc 0 "FALSE" 1 "TRUE" ;
VAL_ 1124 DTCI_DCM_TstNCmpltdLstClr 0 "FALSE" 1 "TRUE" ;
VAL_ 1124 DTCI_DCM_TstFldOpCyc 0 "FALSE" 1 "TRUE" ;
VAL_ 1124 DTCI_DCM_TstFldLstClr 0 "FALSE" 1 "TRUE" ;
VAL_ 1124 DTCI_DCM_TstFld 0 "FALSE" 1 "TRUE" ;
VAL_ 1124 DTCI_DCM_PndngDTC 0 "FALSE" 1 "TRUE" ;
VAL_ 1124 DTCI_DCM_DTCTriggered 0 "FALSE" 1 "TRUE" ;
VAL_ 1124 DTCI_DCM_WrnIndTrggrd 0 "FALSE" 1 "TRUE" ;
VAL_ 1124 DTCI_DCM_WrnIndRqd 0 "FALSE" 1 "TRUE" ;
VAL_ 1126 DTCI_DMS_CnfrmdDTC 0 "FALSE" 1 "TRUE" ;
VAL_ 1126 DTCI_DMS_DTCFaultType 0 "Not Supported" 1 "Type A" 2 "Type B" 3 "Type C" ;
VAL_ 1126 DTCI_DMS_TstNCmpltdOpCyc 0 "FALSE" 1 "TRUE" ;
VAL_ 1126 DTCI_DMS_TstNCmpltdLstClr 0 "FALSE" 1 "TRUE" ;
VAL_ 1126 DTCI_DMS_TstFldOpCyc 0 "FALSE" 1 "TRUE" ;
VAL_ 1126 DTCI_DMS_TstFldLstClr 0 "FALSE" 1 "TRUE" ;
VAL_ 1126 DTCI_DMS_TstFld 0 "FALSE" 1 "TRUE" ;
VAL_ 1126 DTCI_DMS_PndngDTC 0 "FALSE" 1 "TRUE" ;
VAL_ 1126 DTCI_DMS_DTCTriggered 0 "FALSE" 1 "TRUE" ;
VAL_ 1126 DTCI_DMS_WrnIndTrggrd 0 "FALSE" 1 "TRUE" ;
VAL_ 1126 DTCI_DMS_WrnIndRqd 0 "FALSE" 1 "TRUE" ;
VAL_ 1127 DTCI_EBCM_CnfrmdDTC 0 "FALSE" 1 "TRUE" ;
VAL_ 1127 DTCI_EBCM_DTCFaultType 0 "Not Supported" 1 "Type A" 2 "Type B" 3 "Type C" ;
VAL_ 1127 DTCI_EBCM_TstNCmpltdOpCyc 0 "FALSE" 1 "TRUE" ;
VAL_ 1127 DTCI_EBCM_TstNCmpltdLstClr 0 "FALSE" 1 "TRUE" ;
VAL_ 1127 DTCI_EBCM_TstFldOpCyc 0 "FALSE" 1 "TRUE" ;
VAL_ 1127 DTCI_EBCM_TstFldLstClr 0 "FALSE" 1 "TRUE" ;
VAL_ 1127 DTCI_EBCM_TstFld 0 "FALSE" 1 "TRUE" ;
VAL_ 1127 DTCI_EBCM_PndngDTC 0 "FALSE" 1 "TRUE" ;
VAL_ 1127 DTCI_EBCM_DTCTriggered 0 "FALSE" 1 "TRUE" ;
VAL_ 1127 DTCI_EBCM_WrnIndTrggrd 0 "FALSE" 1 "TRUE" ;
VAL_ 1127 DTCI_EBCM_WrnIndRqd 0 "FALSE" 1 "TRUE" ;
VAL_ 1128 DTCI_ECM_CnfrmdDTC 0 "FALSE" 1 "TRUE" ;
VAL_ 1128 DTCI_ECM_DTCFaultType 0 "Not Supported" 1 "Type A" 2 "Type B" 3 "Type C" ;
VAL_ 1128 DTCI_ECM_TstNCmpltdOpCyc 0 "FALSE" 1 "TRUE" ;
VAL_ 1128 DTCI_ECM_TstNCmpltdLstClr 0 "FALSE" 1 "TRUE" ;
VAL_ 1128 DTCI_ECM_TstFldOpCyc 0 "FALSE" 1 "TRUE" ;
VAL_ 1128 DTCI_ECM_TstFldLstClr 0 "FALSE" 1 "TRUE" ;
VAL_ 1128 DTCI_ECM_TstFld 0 "FALSE" 1 "TRUE" ;
VAL_ 1128 DTCI_ECM_PndngDTC 0 "FALSE" 1 "TRUE" ;
VAL_ 1128 DTCI_ECM_DTCTriggered 0 "FALSE" 1 "TRUE" ;
VAL_ 1128 DTCI_ECM_WrnIndTrggrd 0 "FALSE" 1 "TRUE" ;
VAL_ 1128 DTCI_ECM_WrnIndRqd 0 "FALSE" 1 "TRUE" ;
VAL_ 1428 DTCI_ECP_E_CnfrmdDTC 0 "FALSE" 1 "TRUE" ;
VAL_ 1428 DTCI_ECP_E_DTCFaultType 0 "Not Supported" 1 "Type A" 2 "Type B" 3 "Type C" ;
VAL_ 1428 DTCI_ECP_E_TstNCmpltdOpCyc 0 "FALSE" 1 "TRUE" ;
VAL_ 1428 DTCI_ECP_E_TstNCmpltdLstClr 0 "FALSE" 1 "TRUE" ;
VAL_ 1428 DTCI_ECP_E_TstFldOpCyc 0 "FALSE" 1 "TRUE" ;
VAL_ 1428 DTCI_ECP_E_TstFldLstClr 0 "FALSE" 1 "TRUE" ;
VAL_ 1428 DTCI_ECP_E_TstFld 0 "FALSE" 1 "TRUE" ;
VAL_ 1428 DTCI_ECP_E_PndngDTC 0 "FALSE" 1 "TRUE" ;
VAL_ 1428 DTCI_ECP_E_DTCTriggered 0 "FALSE" 1 "TRUE" ;
VAL_ 1428 DTCI_ECP_E_WrnIndTrggrd 0 "FALSE" 1 "TRUE" ;
VAL_ 1428 DTCI_ECP_E_WrnIndRqd 0 "FALSE" 1 "TRUE" ;
VAL_ 1412 DTCI_ECP_MC_CnfrmdDTC 0 "FALSE" 1 "TRUE" ;
VAL_ 1412 DTCI_ECP_MC_DTCFaultType 0 "Not Supported" 1 "Type A" 2 "Type B" 3 "Type C" ;
VAL_ 1412 DTCI_ECP_MC_TstNCmpltdOpCyc 0 "FALSE" 1 "TRUE" ;
VAL_ 1412 DTCI_ECP_MC_TstNCmpltdLstClr 0 "FALSE" 1 "TRUE" ;
VAL_ 1412 DTCI_ECP_MC_TstFldOpCyc 0 "FALSE" 1 "TRUE" ;
VAL_ 1412 DTCI_ECP_MC_TstFldLstClr 0 "FALSE" 1 "TRUE" ;
VAL_ 1412 DTCI_ECP_MC_TstFld 0 "FALSE" 1 "TRUE" ;
VAL_ 1412 DTCI_ECP_MC_PndngDTC 0 "FALSE" 1 "TRUE" ;
VAL_ 1412 DTCI_ECP_MC_DTCTriggered 0 "FALSE" 1 "TRUE" ;
VAL_ 1412 DTCI_ECP_MC_WrnIndTrggrd 0 "FALSE" 1 "TRUE" ;
VAL_ 1412 DTCI_ECP_MC_WrnIndRqd 0 "FALSE" 1 "TRUE" ;
VAL_ 1129 DTCI_ECP_X1_CnfrmdDTC 0 "FALSE" 1 "TRUE" ;
VAL_ 1129 DTCI_ECP_X1_DTCFaultType 0 "Not Supported" 1 "Type A" 2 "Type B" 3 "Type C" ;
VAL_ 1129 DTCI_ECP_X1_TstNCmpltdOpCyc 0 "FALSE" 1 "TRUE" ;
VAL_ 1129 DTCI_ECP_X1_TstNCmpltdLstClr 0 "FALSE" 1 "TRUE" ;
VAL_ 1129 DTCI_ECP_X1_TstFldOpCyc 0 "FALSE" 1 "TRUE" ;
VAL_ 1129 DTCI_ECP_X1_TstFldLstClr 0 "FALSE" 1 "TRUE" ;
VAL_ 1129 DTCI_ECP_X1_TstFld 0 "FALSE" 1 "TRUE" ;
VAL_ 1129 DTCI_ECP_X1_PndngDTC 0 "FALSE" 1 "TRUE" ;
VAL_ 1129 DTCI_ECP_X1_DTCTriggered 0 "FALSE" 1 "TRUE" ;
VAL_ 1129 DTCI_ECP_X1_WrnIndTrggrd 0 "FALSE" 1 "TRUE" ;
VAL_ 1129 DTCI_ECP_X1_WrnIndRqd 0 "FALSE" 1 "TRUE" ;
VAL_ 1131 DTCI_ELM_CnfrmdDTC 0 "FALSE" 1 "TRUE" ;
VAL_ 1131 DTCI_ELM_DTCFaultType 0 "Not Supported" 1 "Type A" 2 "Type B" 3 "Type C" ;
VAL_ 1131 DTCI_ELM_TstNCmpltdOpCyc 0 "FALSE" 1 "TRUE" ;
VAL_ 1131 DTCI_ELM_TstNCmpltdLstClr 0 "FALSE" 1 "TRUE" ;
VAL_ 1131 DTCI_ELM_TstFldOpCyc 0 "FALSE" 1 "TRUE" ;
VAL_ 1131 DTCI_ELM_TstFldLstClr 0 "FALSE" 1 "TRUE" ;
VAL_ 1131 DTCI_ELM_TstFld 0 "FALSE" 1 "TRUE" ;
VAL_ 1131 DTCI_ELM_PndngDTC 0 "FALSE" 1 "TRUE" ;
VAL_ 1131 DTCI_ELM_DTCTriggered 0 "FALSE" 1 "TRUE" ;
VAL_ 1131 DTCI_ELM_WrnIndTrggrd 0 "FALSE" 1 "TRUE" ;
VAL_ 1131 DTCI_ELM_WrnIndRqd 0 "FALSE" 1 "TRUE" ;
VAL_ 1292 DTCI_EOCM_HCP1_CnfrmdDTC 0 "FALSE" 1 "TRUE" ;
VAL_ 1292 DTCI_EOCM_HCP1_DTCFaultType 0 "Not Supported" 1 "Type A" 2 "Type B" 3 "Type C" ;
VAL_ 1292 DTCI_EOCM_HCP1_TstNCmpltdOpCyc 0 "FALSE" 1 "TRUE" ;
VAL_ 1292 DTCI_EOCM_HCP1_TstNCmpltdLstClr 0 "FALSE" 1 "TRUE" ;
VAL_ 1292 DTCI_EOCM_HCP1_TstFldOpCyc 0 "FALSE" 1 "TRUE" ;
VAL_ 1292 DTCI_EOCM_HCP1_TstFldLstClr 0 "FALSE" 1 "TRUE" ;
VAL_ 1292 DTCI_EOCM_HCP1_TstFld 0 "FALSE" 1 "TRUE" ;
VAL_ 1292 DTCI_EOCM_HCP1_PndngDTC 0 "FALSE" 1 "TRUE" ;
VAL_ 1292 DTCI_EOCM_HCP1_DTCTriggered 0 "FALSE" 1 "TRUE" ;
VAL_ 1292 DTCI_EOCM_HCP1_WrnIndTrggrd 0 "FALSE" 1 "TRUE" ;
VAL_ 1292 DTCI_EOCM_HCP1_WrnIndRqd 0 "FALSE" 1 "TRUE" ;
VAL_ 1293 DTCI_EOCM_HCP2_CnfrmdDTC 0 "FALSE" 1 "TRUE" ;
VAL_ 1293 DTCI_EOCM_HCP2_DTCFaultType 0 "Not Supported" 1 "Type A" 2 "Type B" 3 "Type C" ;
VAL_ 1293 DTCI_EOCM_HCP2_TstNCmpltdOpCyc 0 "FALSE" 1 "TRUE" ;
VAL_ 1293 DTCI_EOCM_HCP2_TstNCmpltdLstClr 0 "FALSE" 1 "TRUE" ;
VAL_ 1293 DTCI_EOCM_HCP2_TstFldOpCyc 0 "FALSE" 1 "TRUE" ;
VAL_ 1293 DTCI_EOCM_HCP2_TstFldLstClr 0 "FALSE" 1 "TRUE" ;
VAL_ 1293 DTCI_EOCM_HCP2_TstFld 0 "FALSE" 1 "TRUE" ;
VAL_ 1293 DTCI_EOCM_HCP2_PndngDTC 0 "FALSE" 1 "TRUE" ;
VAL_ 1293 DTCI_EOCM_HCP2_DTCTriggered 0 "FALSE" 1 "TRUE" ;
VAL_ 1293 DTCI_EOCM_HCP2_WrnIndTrggrd 0 "FALSE" 1 "TRUE" ;
VAL_ 1293 DTCI_EOCM_HCP2_WrnIndRqd 0 "FALSE" 1 "TRUE" ;
VAL_ 1132 DTCI_EOCM_CnfrmdDTC 0 "FALSE" 1 "TRUE" ;
VAL_ 1132 DTCI_EOCM_DTCFaultType 0 "Not Supported" 1 "Type A" 2 "Type B" 3 "Type C" ;
VAL_ 1132 DTCI_EOCM_TstNCmpltdOpCyc 0 "FALSE" 1 "TRUE" ;
VAL_ 1132 DTCI_EOCM_TstNCmpltdLstClr 0 "FALSE" 1 "TRUE" ;
VAL_ 1132 DTCI_EOCM_TstFldOpCyc 0 "FALSE" 1 "TRUE" ;
VAL_ 1132 DTCI_EOCM_TstFldLstClr 0 "FALSE" 1 "TRUE" ;
VAL_ 1132 DTCI_EOCM_TstFld 0 "FALSE" 1 "TRUE" ;
VAL_ 1132 DTCI_EOCM_PndngDTC 0 "FALSE" 1 "TRUE" ;
VAL_ 1132 DTCI_EOCM_DTCTriggered 0 "FALSE" 1 "TRUE" ;
VAL_ 1132 DTCI_EOCM_WrnIndTrggrd 0 "FALSE" 1 "TRUE" ;
VAL_ 1132 DTCI_EOCM_WrnIndRqd 0 "FALSE" 1 "TRUE" ;
VAL_ 1133 DTCI_EPS_CnfrmdDTC 0 "FALSE" 1 "TRUE" ;
VAL_ 1133 DTCI_EPS_DTCFaultType 0 "Not Supported" 1 "Type A" 2 "Type B" 3 "Type C" ;
VAL_ 1133 DTCI_EPS_TstNCmpltdOpCyc 0 "FALSE" 1 "TRUE" ;
VAL_ 1133 DTCI_EPS_TstNCmpltdLstClr 0 "FALSE" 1 "TRUE" ;
VAL_ 1133 DTCI_EPS_TstFldOpCyc 0 "FALSE" 1 "TRUE" ;
VAL_ 1133 DTCI_EPS_TstFldLstClr 0 "FALSE" 1 "TRUE" ;
VAL_ 1133 DTCI_EPS_TstFld 0 "FALSE" 1 "TRUE" ;
VAL_ 1133 DTCI_EPS_PndngDTC 0 "FALSE" 1 "TRUE" ;
VAL_ 1133 DTCI_EPS_DTCTriggered 0 "FALSE" 1 "TRUE" ;
VAL_ 1133 DTCI_EPS_WrnIndTrggrd 0 "FALSE" 1 "TRUE" ;
VAL_ 1133 DTCI_EPS_WrnIndRqd 0 "FALSE" 1 "TRUE" ;
VAL_ 1135 DTCI_FCM_LC_CnfrmdDTC 0 "FALSE" 1 "TRUE" ;
VAL_ 1135 DTCI_FCM_LC_DTCFaultType 0 "Not Supported" 1 "Type A" 2 "Type B" 3 "Type C" ;
VAL_ 1135 DTCI_FCM_LC_TstNCmpltdOpCyc 0 "FALSE" 1 "TRUE" ;
VAL_ 1135 DTCI_FCM_LC_TstNCmpltdLstClr 0 "FALSE" 1 "TRUE" ;
VAL_ 1135 DTCI_FCM_LC_TstFldOpCyc 0 "FALSE" 1 "TRUE" ;
VAL_ 1135 DTCI_FCM_LC_TstFldLstClr 0 "FALSE" 1 "TRUE" ;
VAL_ 1135 DTCI_FCM_LC_TstFld 0 "FALSE" 1 "TRUE" ;
VAL_ 1135 DTCI_FCM_LC_PndngDTC 0 "FALSE" 1 "TRUE" ;
VAL_ 1135 DTCI_FCM_LC_DTCTriggered 0 "FALSE" 1 "TRUE" ;
VAL_ 1135 DTCI_FCM_LC_WrnIndTrggrd 0 "FALSE" 1 "TRUE" ;
VAL_ 1135 DTCI_FCM_LC_WrnIndRqd 0 "FALSE" 1 "TRUE" ;
VAL_ 1134 DTCI_FCM_CnfrmdDTC 0 "FALSE" 1 "TRUE" ;
VAL_ 1134 DTCI_FCM_DTCFaultType 0 "Not Supported" 1 "Type A" 2 "Type B" 3 "Type C" ;
VAL_ 1134 DTCI_FCM_TstNCmpltdOpCyc 0 "FALSE" 1 "TRUE" ;
VAL_ 1134 DTCI_FCM_TstNCmpltdLstClr 0 "FALSE" 1 "TRUE" ;
VAL_ 1134 DTCI_FCM_TstFldOpCyc 0 "FALSE" 1 "TRUE" ;
VAL_ 1134 DTCI_FCM_TstFldLstClr 0 "FALSE" 1 "TRUE" ;
VAL_ 1134 DTCI_FCM_TstFld 0 "FALSE" 1 "TRUE" ;
VAL_ 1134 DTCI_FCM_PndngDTC 0 "FALSE" 1 "TRUE" ;
VAL_ 1134 DTCI_FCM_DTCTriggered 0 "FALSE" 1 "TRUE" ;
VAL_ 1134 DTCI_FCM_WrnIndTrggrd 0 "FALSE" 1 "TRUE" ;
VAL_ 1134 DTCI_FCM_WrnIndRqd 0 "FALSE" 1 "TRUE" ;
VAL_ 1406 DTCI_HDLM_CnfrmdDTC 0 "FALSE" 1 "TRUE" ;
VAL_ 1406 DTCI_HDLM_DTCFaultType 0 "Not Supported" 1 "Type A" 2 "Type B" 3 "Type C" ;
VAL_ 1406 DTCI_HDLM_TstNCmpltdOpCyc 0 "FALSE" 1 "TRUE" ;
VAL_ 1406 DTCI_HDLM_TstNCmpltdLstClr 0 "FALSE" 1 "TRUE" ;
VAL_ 1406 DTCI_HDLM_TstFldOpCyc 0 "FALSE" 1 "TRUE" ;
VAL_ 1406 DTCI_HDLM_TstFldLstClr 0 "FALSE" 1 "TRUE" ;
VAL_ 1406 DTCI_HDLM_TstFld 0 "FALSE" 1 "TRUE" ;
VAL_ 1406 DTCI_HDLM_PndngDTC 0 "FALSE" 1 "TRUE" ;
VAL_ 1406 DTCI_HDLM_DTCTriggered 0 "FALSE" 1 "TRUE" ;
VAL_ 1406 DTCI_HDLM_WrnIndTrggrd 0 "FALSE" 1 "TRUE" ;
VAL_ 1406 DTCI_HDLM_WrnIndRqd 0 "FALSE" 1 "TRUE" ;
VAL_ 1286 DTCI_HUD_CAN_CnfrmdDTC 0 "FALSE" 1 "TRUE" ;
VAL_ 1286 DTCI_HUD_CAN_DTCFaultType 0 "Not Supported" 1 "Type A" 2 "Type B" 3 "Type C" ;
VAL_ 1286 DTCI_HUD_CAN_TstNCmpltdOpCyc 0 "FALSE" 1 "TRUE" ;
VAL_ 1286 DTCI_HUD_CAN_TstNCmpltdLstClr 0 "FALSE" 1 "TRUE" ;
VAL_ 1286 DTCI_HUD_CAN_TstFldOpCyc 0 "FALSE" 1 "TRUE" ;
VAL_ 1286 DTCI_HUD_CAN_TstFldLstClr 0 "FALSE" 1 "TRUE" ;
VAL_ 1286 DTCI_HUD_CAN_TstFld 0 "FALSE" 1 "TRUE" ;
VAL_ 1286 DTCI_HUD_CAN_PndngDTC 0 "FALSE" 1 "TRUE" ;
VAL_ 1286 DTCI_HUD_CAN_DTCTriggered 0 "FALSE" 1 "TRUE" ;
VAL_ 1286 DTCI_HUD_CAN_WrnIndTrggrd 0 "FALSE" 1 "TRUE" ;
VAL_ 1286 DTCI_HUD_CAN_WrnIndRqd 0 "FALSE" 1 "TRUE" ;
VAL_ 1287 DTCI_HVAC_FP_F_CnfrmdDTC 0 "FALSE" 1 "TRUE" ;
VAL_ 1287 DTCI_HVAC_FP_F_DTCFaultType 0 "Not Supported" 1 "Type A" 2 "Type B" 3 "Type C" ;
VAL_ 1287 DTCI_HVAC_FP_F_TstNCmpltdOpCyc 0 "FALSE" 1 "TRUE" ;
VAL_ 1287 DTCI_HVAC_FP_F_TstNCmpltdLstClr 0 "FALSE" 1 "TRUE" ;
VAL_ 1287 DTCI_HVAC_FP_F_TstFldOpCyc 0 "FALSE" 1 "TRUE" ;
VAL_ 1287 DTCI_HVAC_FP_F_TstFldLstClr 0 "FALSE" 1 "TRUE" ;
VAL_ 1287 DTCI_HVAC_FP_F_TstFld 0 "FALSE" 1 "TRUE" ;
VAL_ 1287 DTCI_HVAC_FP_F_PndngDTC 0 "FALSE" 1 "TRUE" ;
VAL_ 1287 DTCI_HVAC_FP_F_DTCTriggered 0 "FALSE" 1 "TRUE" ;
VAL_ 1287 DTCI_HVAC_FP_F_WrnIndTrggrd 0 "FALSE" 1 "TRUE" ;
VAL_ 1287 DTCI_HVAC_FP_F_WrnIndRqd 0 "FALSE" 1 "TRUE" ;
VAL_ 1304 DTCI_HVAC_FP_R_CnfrmdDTC 0 "FALSE" 1 "TRUE" ;
VAL_ 1304 DTCI_HVAC_FP_R_DTCFaultType 0 "Not Supported" 1 "Type A" 2 "Type B" 3 "Type C" ;
VAL_ 1304 DTCI_HVAC_FP_R_TstNCmpltdOpCyc 0 "FALSE" 1 "TRUE" ;
VAL_ 1304 DTCI_HVAC_FP_R_TstNCmpltdLstClr 0 "FALSE" 1 "TRUE" ;
VAL_ 1304 DTCI_HVAC_FP_R_TstFldOpCyc 0 "FALSE" 1 "TRUE" ;
VAL_ 1304 DTCI_HVAC_FP_R_TstFldLstClr 0 "FALSE" 1 "TRUE" ;
VAL_ 1304 DTCI_HVAC_FP_R_TstFld 0 "FALSE" 1 "TRUE" ;
VAL_ 1304 DTCI_HVAC_FP_R_PndngDTC 0 "FALSE" 1 "TRUE" ;
VAL_ 1304 DTCI_HVAC_FP_R_DTCTriggered 0 "FALSE" 1 "TRUE" ;
VAL_ 1304 DTCI_HVAC_FP_R_WrnIndTrggrd 0 "FALSE" 1 "TRUE" ;
VAL_ 1304 DTCI_HVAC_FP_R_WrnIndRqd 0 "FALSE" 1 "TRUE" ;
VAL_ 1349 DTCI_ICCM_CnfrmdDTC 0 "FALSE" 1 "TRUE" ;
VAL_ 1349 DTCI_ICCM_DTCFaultType 0 "Not Supported" 1 "Type A" 2 "Type B" 3 "Type C" ;
VAL_ 1349 DTCI_ICCM_TstNCmpltdOpCyc 0 "FALSE" 1 "TRUE" ;
VAL_ 1349 DTCI_ICCM_TstNCmpltdLstClr 0 "FALSE" 1 "TRUE" ;
VAL_ 1349 DTCI_ICCM_TstFldOpCyc 0 "FALSE" 1 "TRUE" ;
VAL_ 1349 DTCI_ICCM_TstFldLstClr 0 "FALSE" 1 "TRUE" ;
VAL_ 1349 DTCI_ICCM_TstFld 0 "FALSE" 1 "TRUE" ;
VAL_ 1349 DTCI_ICCM_PndngDTC 0 "FALSE" 1 "TRUE" ;
VAL_ 1349 DTCI_ICCM_DTCTriggered 0 "FALSE" 1 "TRUE" ;
VAL_ 1349 DTCI_ICCM_WrnIndTrggrd 0 "FALSE" 1 "TRUE" ;
VAL_ 1349 DTCI_ICCM_WrnIndRqd 0 "FALSE" 1 "TRUE" ;
VAL_ 1307 DTCI_ICS_Info_CnfrmdDTC 0 "FALSE" 1 "TRUE" ;
VAL_ 1307 DTCI_ICS_Info_DTCFaultType 0 "Not Supported" 1 "Type A" 2 "Type B" 3 "Type C" ;
VAL_ 1307 DTCI_ICS_Info_TstNCmpltdOpCyc 0 "FALSE" 1 "TRUE" ;
VAL_ 1307 DTCI_ICS_Info_TstNCmpltdLstClr 0 "FALSE" 1 "TRUE" ;
VAL_ 1307 DTCI_ICS_Info_TstFldOpCyc 0 "FALSE" 1 "TRUE" ;
VAL_ 1307 DTCI_ICS_Info_TstFldLstClr 0 "FALSE" 1 "TRUE" ;
VAL_ 1307 DTCI_ICS_Info_TstFld 0 "FALSE" 1 "TRUE" ;
VAL_ 1307 DTCI_ICS_Info_PndngDTC 0 "FALSE" 1 "TRUE" ;
VAL_ 1307 DTCI_ICS_Info_DTCTriggered 0 "FALSE" 1 "TRUE" ;
VAL_ 1307 DTCI_ICS_Info_WrnIndTrggrd 0 "FALSE" 1 "TRUE" ;
VAL_ 1307 DTCI_ICS_Info_WrnIndRqd 0 "FALSE" 1 "TRUE" ;
